VERSION "HNNBNNNYNNNNNNNNNNNNNNNNNNNNNNNNNNNNNNNNNN/4/%%%/4/'%**4NNN///"

NS_ :

BS_:

BU_: BAP_Tester BMS_NV_12V Gateway_Max Klima

BO_ 1640 Klima_12: 8 Klima
 SG_ KL_LRH_Taster : 0|1@1+ (1.0,0.0) [0.0|1] ""  Gateway_Max
 SG_ KL_LRH_Stufe : 1|2@1+ (1.0,0.0) [0.0|3] ""  Gateway_Max
 SG_ HSH_Taster : 3|2@1+ (1.0,0.0) [0.0|3] ""  Gateway_Max
 SG_ FSH_Taster : 5|1@1+ (1.0,0.0) [0.0|1] ""  Gateway_Max
 SG_ KL_Zuheizer_Freigabe : 6|1@1+ (1.0,0.0) [0.0|1] ""  Gateway_Max
 SG_ KL_Beschlagsgefahr : 7|1@1+ (1.0,0.0) [0.0|1] ""  Gateway_Max
 SG_ KL_SIH_Soll_li : 8|3@1+ (1,0) [0|6] ""  Gateway_Max
 SG_ KL_SIH_Soll_re : 11|3@1+ (1,0) [0|6] ""  Gateway_Max
 SG_ KRH_Soll_li : 14|2@1+ (1.0,0.0) [0.0|3] ""  Gateway_Max
 SG_ KL_SIL_Soll_li : 16|3@1+ (1,0) [0|6] ""  Gateway_Max
 SG_ KL_SIL_Soll_re : 19|3@1+ (1,0) [0|6] ""  Gateway_Max
 SG_ KRH_Soll_re : 22|2@1+ (1.0,0.0) [0.0|3] ""  Gateway_Max
 SG_ KL_Geblspng_Soll : 24|8@1+ (0.05,1.45) [1.50|14.00] "Unit_Volt"  Gateway_Max
 SG_ KL_Geblspng_Fond_Soll : 32|8@1+ (0.05,1.45) [1.50|14.00] "Unit_Volt"  Gateway_Max
 SG_ KL_I_Geblaese : 40|8@1+ (0.25,0) [0.00|63.50] "Unit_Amper"  Gateway_Max
 SG_ KL_Kompressorstrom_soll : 48|10@1+ (1,0) [0|1021] ""  Gateway_Max
 SG_ KL_Umluftklappe_Status : 58|4@1+ (1.0,0.0) [0.0|15] ""  Gateway_Max
 SG_ KL_PTC_Verbauinfo : 62|2@1+ (1.0,0.0) [0.0|3] ""  Gateway_Max

BO_ 2527679635 Klima_16: 8 Klima
 SG_ KL_Voko_Status : 0|4@1+ (1.0,0.0) [0.0|15] ""  Gateway_Max
 SG_ KL_LRH_PWM : 4|7@1+ (1,0) [0|100] "Unit_PerCent"  Gateway_Max
 SG_ KL_LRH_Soll : 11|1@1+ (1.0,0.0) [0.0|1] ""  Gateway_Max
 SG_ KL_AL_VR_Anf : 12|2@1+ (1.0,0.0) [0.0|3] ""  Gateway_Max
 SG_ KL_AL_VL_Anf : 14|2@1+ (1.0,0.0) [0.0|3] ""  Gateway_Max
 SG_ KL_AL_HR_Anf : 16|2@1+ (1.0,0.0) [0.0|3] ""  Gateway_Max
 SG_ KL_AL_HL_Anf : 18|2@1+ (1.0,0.0) [0.0|3] ""  Gateway_Max
 SG_ KL_HSH_Soll : 20|1@1+ (1.0,0.0) [0.0|1] ""  Gateway_Max
 SG_ KL_FSH_Soll : 21|1@1+ (1.0,0.0) [0.0|1] ""  Gateway_Max
 SG_ KL_ZR_Anforderung : 22|2@1+ (1.0,0.0) [0.0|3] ""  Gateway_Max
 SG_ KL_VoKo_LED : 24|1@1+ (1.0,0.0) [0.0|1] ""  Gateway_Max
 SG_ KL_Defrost_LED : 25|1@1+ (1.0,0.0) [0.0|1] ""  Gateway_Max
 SG_ KL_HSH_LED : 26|1@1+ (1.0,0.0) [0.0|1] ""  Gateway_Max
 SG_ HSH_Relais_Anf : 27|1@1+ (1.0,0.0) [0.0|1] ""  Gateway_Max
 SG_ FSH_Status : 28|2@1+ (1.0,0.0) [0.0|3] ""  Gateway_Max
 SG_ SIH_Stufe_LED_li : 30|3@1+ (1.0,0.0) [0.0|7] ""  Gateway_Max
 SG_ SIH_Stufe_LED_re : 33|3@1+ (1.0,0.0) [0.0|7] ""  Gateway_Max
 SG_ KL_FSH_LED : 36|1@1+ (1.0,0.0) [0.0|1] ""  Gateway_Max
 SG_ KL_HUP_aktiv : 37|1@1+ (1.0,0.0) [0.0|1] ""  Gateway_Max
 SG_ KL_LSH_DBetr_Ein : 38|1@1+ (1.0,0.0) [0.0|1] ""  Gateway_Max
 SG_ KL_LSH_DBetr_Bestaet : 39|1@1+ (1.0,0.0) [0.0|1] ""  Gateway_Max
 SG_ KL_Klappe_Status : 40|3@1+ (1.0,0.0) [0.0|7] ""  Gateway_Max
 SG_ KL_LSH_Ansteuerung : 43|2@1+ (1.0,0.0) [0.0|3] ""  Gateway_Max
 SG_ KL_Heizstufe_LSH : 45|4@1+ (1.0,0.0) [0.0|15] ""  Gateway_Max
 SG_ KL_LSH_Betriebsdauer : 49|7@1+ (1,0) [0|120] "Unit_Minut"  Gateway_Max
 SG_ KL_Temp_ZH_Soll : 56|8@1+ (0.5,0) [0.5|127.0] "Unit_DegreCelsi"  Gateway_Max

BO_ 2589284015 Klima_21: 8 Klima
 SG_ KL_LRH_FoD_Status : 12|2@1+ (1.0,0.0) [0.0|3] ""  Gateway_Max

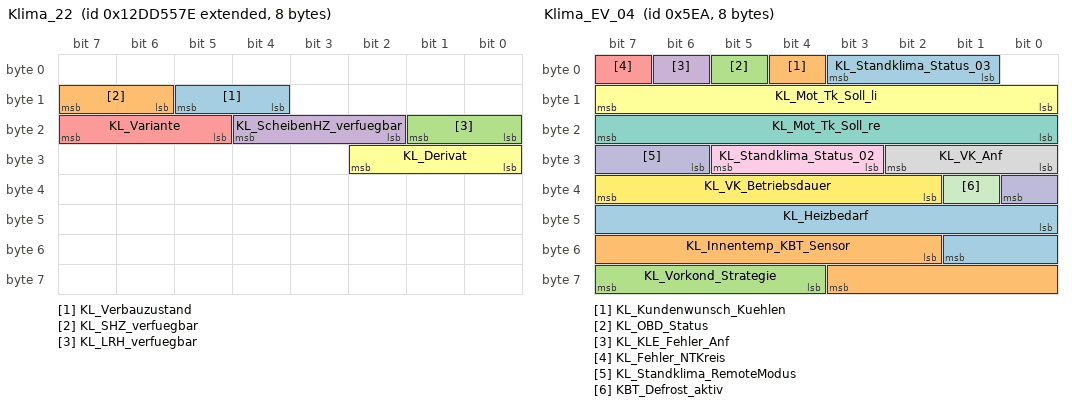
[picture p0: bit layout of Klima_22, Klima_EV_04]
BO_ 2463978878 Klima_22: 8 Klima
 SG_ KL_Verbauzustand : 12|2@1+ (1.0,0.0) [0.0|3] ""  Gateway_Max
 SG_ KL_SHZ_verfuegbar : 14|2@1+ (1.0,0.0) [0.0|3] ""  Gateway_Max
 SG_ KL_LRH_verfuegbar : 16|2@1+ (1.0,0.0) [0.0|3] ""  Gateway_Max
 SG_ KL_ScheibenHZ_verfuegbar : 18|3@1+ (1.0,0.0) [0.0|7] ""  Gateway_Max
 SG_ KL_Variante : 21|3@1+ (1.0,0.0) [0.0|7] ""  Gateway_Max
 SG_ KL_Derivat : 24|3@1+ (1.0,0.0) [0.0|7] ""  Gateway_Max

BO_ 1511 Klima_EV_03: 8 Klima
 SG_ KL_HV_Heizer_Strom : 0|8@1+ (0.25,0) [0.00|63.50] "Unit_Amper"  Gateway_Max
 SG_ KL_EKK_Strom : 8|8@1+ (0.25,0) [0.00|63.50] "Unit_Amper"  Gateway_Max
 SG_ KL_Pumpe_02_Soll : 16|7@1+ (1,0) [0|100] "Unit_PerCent"  Gateway_Max
 SG_ KL_Ventil_03_Soll : 23|1@1+ (1.0,0.0) [0.0|1] ""  Gateway_Max
 SG_ KL_Ventil_10_Status : 24|3@1+ (1.0,0.0) [0.0|7] ""  Gateway_Max
 SG_ KL_Senderkennung : 27|1@1+ (1.0,0.0) [0.0|1] ""  Gateway_Max
 SG_ WP_KJ_Soll : 28|2@1+ (1.0,0.0) [0.0|3] ""  Gateway_Max
 SG_ KL_Fehler_HV_EKK : 30|2@1+ (1.0,0.0) [0.0|3] ""  Gateway_Max
 SG_ KL_Fehler_HV_Heizer : 32|2@1+ (1.0,0.0) [0.0|3] ""  Gateway_Max
 SG_ KL_BattKond_WaPu_DZMax : 34|6@1+ (2,0) [0|100] "Unit_PerCent"  Gateway_Max
 SG_ WP_Kuehlerluefter_Anf : 40|8@1+ (0.4,0) [0.0|101.6] "Unit_PerCent"  Gateway_Max
 SG_ KL_KM_ASV_01_Status : 48|2@1+ (1.0,0.0) [0.0|3] ""  Gateway_Max
 SG_ KL_KM_ASV_02_Status : 50|2@1+ (1.0,0.0) [0.0|3] ""  Gateway_Max
 SG_ KL_Vorwarn_HVHeizer_Leistung : 52|4@1+ (1.0,0.0) [0.0|15] ""  Gateway_Max
 SG_ KL_Status_EoHVL_EKK : 56|2@1+ (1.0,0.0) [0.0|3] ""  Gateway_Max
 SG_ KL_Status_EoHVL_Heizer : 58|2@1+ (1.0,0.0) [0.0|3] ""  Gateway_Max
 SG_ KL_Status_EoHVL_EKK_2 : 60|2@1+ (1.0,0.0) [0.0|3] ""  Gateway_Max
 SG_ KL_Status_EoHVL_Heizer_2 : 62|2@1+ (1.0,0.0) [0.0|3] ""  Gateway_Max

BO_ 1514 Klima_EV_04: 8 Klima
 SG_ KL_Standklima_Status_03 : 1|3@1+ (1.0,0.0) [0.0|7] ""  Gateway_Max
 SG_ KL_Kundenwunsch_Kuehlen : 4|1@1+ (1.0,0.0) [0.0|1] ""  Gateway_Max
 SG_ KL_OBD_Status : 5|1@1+ (1.0,0.0) [0.0|1] ""  Gateway_Max
 SG_ KL_KLE_Fehler_Anf : 6|1@1+ (1.0,0.0) [0.0|1] ""  Gateway_Max
 SG_ KL_Fehler_NTKreis : 7|1@1+ (1.0,0.0) [0.0|1] ""  Gateway_Max
 SG_ KL_Mot_Tk_Soll_li : 8|8@1+ (0.5,0) [0.0|100.0] "Unit_PerCent"  Gateway_Max
 SG_ KL_Mot_Tk_Soll_re : 16|8@1+ (0.5,0) [0.0|100.0] "Unit_PerCent"  Gateway_Max
 SG_ KL_VK_Anf : 24|3@1+ (1.0,0.0) [0.0|7] ""  Gateway_Max
 SG_ KL_Standklima_Status_02 : 27|3@1+ (1.0,0.0) [0.0|7] ""  Gateway_Max
 SG_ KL_Standklima_RemoteModus : 30|3@1+ (1.0,0.0) [0.0|7] ""  Gateway_Max
 SG_ KBT_Defrost_aktiv : 33|1@1+ (1.0,0.0) [0.0|1] ""  Gateway_Max
 SG_ KL_VK_Betriebsdauer : 34|6@1+ (1,0) [0|60] "Unit_Minut"  Gateway_Max
 SG_ KL_Heizbedarf : 40|10@1+ (0.1,0) [0.1|90.0] "Unit_DegreCelsi"  Gateway_Max
 SG_ KL_Innentemp_KBT_Sensor : 50|10@1+ (0.1,-40) [-40.0|62.0] "Unit_DegreCelsi"  Gateway_Max
 SG_ KL_Vorkond_Strategie : 60|4@1+ (1.0,0.0) [0.0|15] ""  Gateway_Max

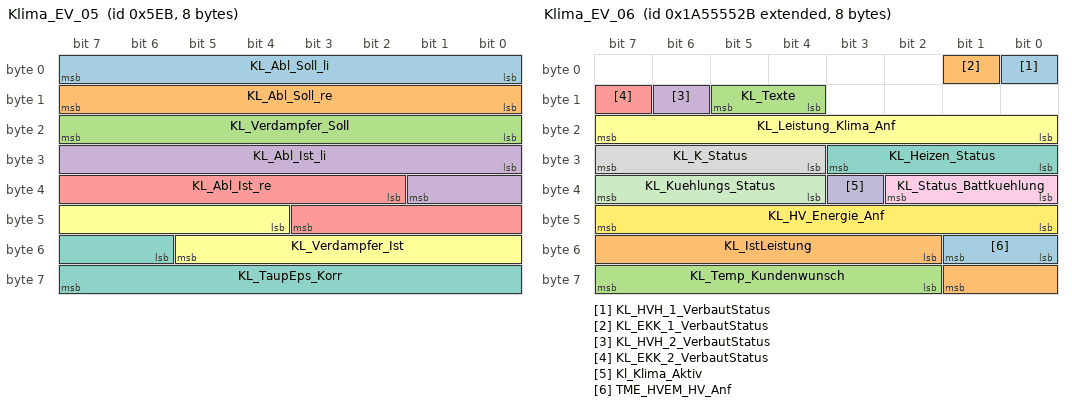
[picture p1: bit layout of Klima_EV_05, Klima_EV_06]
BO_ 1515 Klima_EV_05: 8 Klima
 SG_ KL_Abl_Soll_li : 0|8@1+ (0.5,0) [0.0|86.0] "Unit_DegreCelsi"  Vector__XXX
 SG_ KL_Abl_Soll_re : 8|8@1+ (0.5,0) [0.0|86.0] "Unit_DegreCelsi"  Vector__XXX
 SG_ KL_Verdampfer_Soll : 16|8@1+ (0.5,-40) [-40.0|86.5] "Unit_DegreCelsi"  Vector__XXX
 SG_ KL_Abl_Ist_li : 24|10@1+ (0.1,-20) [-20.0|82.0] "Unit_DegreCelsi"  Vector__XXX
 SG_ KL_Abl_Ist_re : 34|10@1+ (0.1,-20) [-20.0|82.0] "Unit_DegreCelsi"  Vector__XXX
 SG_ KL_Verdampfer_Ist : 44|10@1+ (0.1,-40) [-40.0|62.0] "Unit_DegreCelsi"  Vector__XXX
 SG_ KL_TaupEps_Korr : 54|10@1+ (0.1,-50) [-50.0|52.0] "Unit_DegreCelsi"  Vector__XXX

BO_ 2589283627 Klima_EV_06: 8 Klima
 SG_ KL_HVH_1_VerbautStatus : 0|1@1+ (1.0,0.0) [0.0|1] ""  Gateway_Max
 SG_ KL_EKK_1_VerbautStatus : 1|1@1+ (1.0,0.0) [0.0|1] ""  Gateway_Max
 SG_ KL_Texte : 12|2@1+ (1.0,0.0) [0.0|3] ""  Gateway_Max
 SG_ KL_HVH_2_VerbautStatus : 14|1@1+ (1.0,0.0) [0.0|1] ""  Gateway_Max
 SG_ KL_EKK_2_VerbautStatus : 15|1@1+ (1.0,0.0) [0.0|1] ""  Gateway_Max
 SG_ KL_Leistung_Klima_Anf : 16|8@1+ (50,0) [0|12650] "Unit_Watt"  Gateway_Max
 SG_ KL_Heizen_Status : 24|4@1+ (1.0,0.0) [0.0|15] ""  Gateway_Max
 SG_ KL_K_Status : 28|4@1+ (1.0,0.0) [0.0|15] ""  Gateway_Max
 SG_ KL_Status_Battkuehlung : 32|3@1+ (1.0,0.0) [0.0|7] ""  Gateway_Max
 SG_ Kl_Klima_Aktiv : 35|1@1+ (1.0,0.0) [0.0|1] ""  Gateway_Max
 SG_ KL_Kuehlungs_Status : 36|4@1+ (1.0,0.0) [0.0|15] ""  Gateway_Max
 SG_ KL_HV_Energie_Anf : 40|8@1+ (50,0) [0|12600] "Unit_WattHour"  Gateway_Max
 SG_ TME_HVEM_HV_Anf : 48|2@1+ (1.0,0.0) [0.0|3] ""  Gateway_Max
 SG_ KL_IstLeistung : 50|8@1+ (50,0) [0|12650] "Unit_Watt"  Gateway_Max
 SG_ KL_Temp_Kundenwunsch : 58|6@1+ (0.5,15) [16.0|29.5] "Unit_DegreCelsi"  Gateway_Max

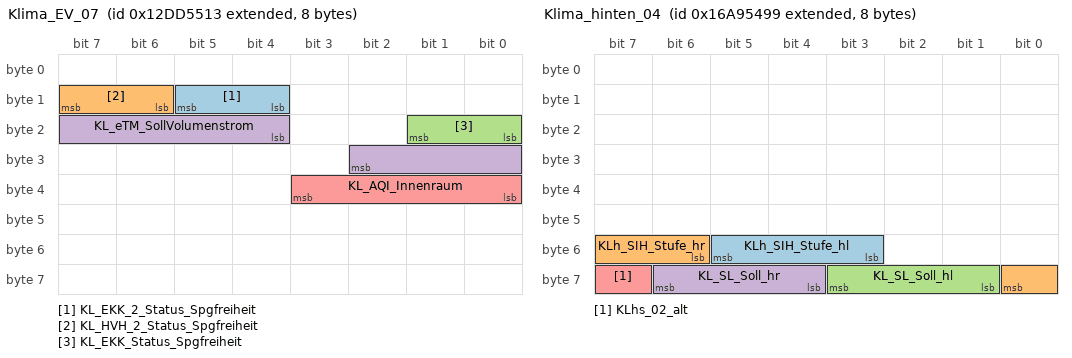
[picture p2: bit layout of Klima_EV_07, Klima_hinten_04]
BO_ 2463978771 Klima_EV_07: 8 Klima
 SG_ KL_EKK_2_Status_Spgfreiheit : 12|2@1+ (1.0,0.0) [0.0|3] ""  Vector__XXX
 SG_ KL_HVH_2_Status_Spgfreiheit : 14|2@1+ (1.0,0.0) [0.0|3] ""  Vector__XXX
 SG_ KL_EKK_Status_Spgfreiheit : 16|2@1+ (1.0,0.0) [0.0|3] ""  Vector__XXX
 SG_ KL_eTM_SollVolumenstrom : 20|7@1+ (0.125,0) [0.000|15.000] "Unit_LiterPerMinut"  Vector__XXX
 SG_ KL_AQI_Innenraum : 32|4@1+ (1.0,0.0) [0.0|15] ""  Gateway_Max

BO_ 2589283574 Klima_EV_10: 16 Klima
 SG_ KL_OBD_Status_Auth : 12|1@1+ (1.0,0.0) [0.0|1] ""  Gateway_Max
 SG_ OBDProtocol_Klima : 16|8@1+ (1.0,0.0) [0.0|255] ""  Gateway_Max
 SG_ SOK_Klima_EV_10_Signatur : 64|64@1+ (1,0) [1|18446744073709551615] "Unit_None"  Gateway_Max

BO_ 2527679641 Klima_hinten_04: 8 Klima
 SG_ KLh_SIH_Stufe_hl : 51|3@1+ (1.0,0.0) [0.0|7] ""  Gateway_Max
 SG_ KLh_SIH_Stufe_hr : 54|3@1+ (1.0,0.0) [0.0|7] ""  Gateway_Max
 SG_ KL_SL_Soll_hl : 57|3@1+ (1.0,0.0) [0.0|7] ""  Gateway_Max
 SG_ KL_SL_Soll_hr : 60|3@1+ (1.0,0.0) [0.0|7] ""  Gateway_Max
 SG_ KLhs_02_alt : 63|1@1+ (1.0,0.0) [0.0|1] ""  Vector__XXX

BO_ 2589283728 Klima_SDA_01: 8 Klima
 SG_ KL_SDA_Sonderfunktionen_Sprache : 0|5@1+ (1.0,0.0) [0.0|31] ""  Gateway_Max
 SG_ KL_SDA_Menutaste : 5|1@1+ (1.0,0.0) [0.0|1] ""  Gateway_Max
 SG_ KL_SDA_Luft_Qualitaet : 6|4@1+ (1.0,0.0) [0.0|15] ""  Gateway_Max
 SG_ KL_SDA_Luft_Feinstaub : 10|8@1+ (5,0) [0|1200] ""  Gateway_Max
 SG_ KL_SDA_AQS_VOZBereich : 18|2@1+ (1.0,0.0) [0.0|3] ""  Gateway_Max
 SG_ KL_SDA_AQS_Traffic : 20|2@1+ (1.0,0.0) [0.0|3] ""  Gateway_Max
 SG_ KL_SDA_AQS_NoxBereich : 22|2@1+ (1.0,0.0) [0.0|3] ""  Gateway_Max
 SG_ KL_SDA_AQS_COBereich : 24|2@1+ (1.0,0.0) [0.0|3] ""  Gateway_Max
 SG_ KL_SDA_AQS_COStatus : 26|4@1+ (1.0,0.0) [0.0|15] ""  Gateway_Max
 SG_ KL_SDA_AQS_NoxStatus : 30|4@1+ (1.0,0.0) [0.0|15] ""  Gateway_Max
 SG_ KL_SDA_AQS_VOZStatus : 34|4@1+ (1.0,0.0) [0.0|15] ""  Gateway_Max
 SG_ KL_SDA_Klima_Automatik : 38|1@1+ (1.0,0.0) [0.0|1] ""  Gateway_Max
 SG_ KL_SDA_Luftverteilung_Person : 39|1@1+ (1.0,0.0) [0.0|1] ""  Gateway_Max
 SG_ KL_SDA_Luftverteilung_Scheibe : 40|1@1+ (1.0,0.0) [0.0|1] ""  Gateway_Max
 SG_ KL_SDA_Luftverteilung_Unten : 41|1@1+ (1.0,0.0) [0.0|1] ""  Gateway_Max
 SG_ KL_SDA_Sitzheizung_VL : 42|2@1+ (1.0,0.0) [0.0|3] ""  Gateway_Max
 SG_ KL_SDA_Sitzheizung_VR : 44|2@1+ (1.0,0.0) [0.0|3] ""  Gateway_Max
 SG_ KL_SDA_Sitzlueftung_VL : 46|2@1+ (1.0,0.0) [0.0|3] ""  Gateway_Max
 SG_ KL_SDA_Sitzlueftung_VR : 48|2@1+ (1.0,0.0) [0.0|3] ""  Gateway_Max
 SG_ KL_SDA_Sonderfkt_AirCare : 50|1@1+ (1.0,0.0) [0.0|1] ""  Gateway_Max
 SG_ KL_SDA_Sonderfkt_HSH : 51|1@1+ (1.0,0.0) [0.0|1] ""  Gateway_Max
 SG_ KL_SDA_Sonderfkt_MaxAC : 52|1@1+ (1.0,0.0) [0.0|1] ""  Gateway_Max
 SG_ KL_SDA_Sonderfkt_MaxDefrost : 53|1@1+ (1.0,0.0) [0.0|1] ""  Gateway_Max
 SG_ KL_SDA_Temp_Kundenwunsch_2 : 54|5@1+ (1.0,0.0) [0.0|31] ""  Gateway_Max
 SG_ KL_SDA_Temp_Kundenwunsch_3 : 59|5@1+ (1.0,0.0) [0.0|31] ""  Gateway_Max

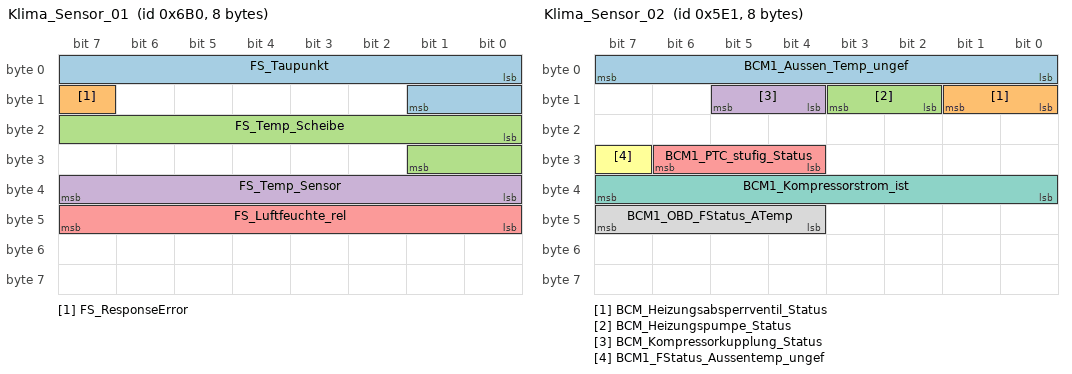
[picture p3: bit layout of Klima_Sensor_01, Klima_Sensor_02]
BO_ 1712 Klima_Sensor_01: 8 Gateway_Max
 SG_ FS_Taupunkt : 0|10@1+ (0.1,-39.6) [-39.5|60.4] "Unit_DegreCelsi"  Klima
 SG_ FS_ResponseError : 15|1@1+ (1.0,0.0) [0.0|1] ""  Klima
 SG_ FS_Temp_Scheibe : 16|10@1+ (0.1,-39.6) [-39.5|60.4] "Unit_DegreCelsi"  Klima
 SG_ FS_Temp_Sensor : 32|8@1+ (0.5,-40) [-39.5|87.0] "Unit_DegreCelsi"  Klima
 SG_ FS_Luftfeuchte_rel : 40|8@1+ (0.5,-0.5) [0.0|100.0] "Unit_PerCent"  Klima

BO_ 1505 Klima_Sensor_02: 8 Gateway_Max
 SG_ BCM1_Aussen_Temp_ungef : 0|8@1+ (0.5,-50) [-50.0|76.0] "Unit_DegreCelsi"  Klima
 SG_ BCM_Heizungsabsperrventil_Status : 8|2@1+ (1.0,0.0) [0.0|3] ""  Vector__XXX
 SG_ BCM_Heizungspumpe_Status : 10|2@1+ (1.0,0.0) [0.0|3] ""  Vector__XXX
 SG_ BCM_Kompressorkupplung_Status : 12|2@1+ (1.0,0.0) [0.0|3] ""  Vector__XXX
 SG_ BCM1_PTC_stufig_Status : 28|3@1+ (1.0,0.0) [0.0|7] ""  Vector__XXX
 SG_ BCM1_FStatus_Aussentemp_ungef : 31|1@1+ (1.0,0.0) [0.0|1] ""  Klima
 SG_ BCM1_Kompressorstrom_ist : 32|8@1+ (4,0) [0|1000] "Unit_MilliAmper"  Vector__XXX
 SG_ BCM1_OBD_FStatus_ATemp : 44|4@1+ (1.0,0.0) [0.0|15] ""  Klima

BO_ 1717 Klima_Sensor_03: 8 Klima
 SG_ FSA_Taupunkt : 0|10@1+ (0.1,-40) [-40.0|60.0] "Unit_DegreCelsi"  Gateway_Max
 SG_ FSA_Err_Defekt_Tsens_TF : 10|1@1+ (1.0,0.0) [0.0|1] ""  Gateway_Max
 SG_ FSA_Luftfeuchte_TNCTOC : 11|1@1+ (1.0,0.0) [0.0|1] ""  Gateway_Max
 SG_ FSA_Luftfeuchte_TF : 12|1@1+ (1.0,0.0) [0.0|1] ""  Gateway_Max
 SG_ FSA_Err_Unterspannung_TF : 13|1@1+ (1.0,0.0) [0.0|1] ""  Gateway_Max
 SG_ FSA_Err_RAMROM_Check_TF : 14|1@1+ (1.0,0.0) [0.0|1] ""  Gateway_Max
 SG_ FSA_ResponseError : 15|1@1+ (1.0,0.0) [0.0|1] ""  Gateway_Max
 SG_ FSA_Temp_Luft : 16|10@1+ (0.1,-40) [-40.0|61.0] "Unit_DegreCelsi"  Gateway_Max
 SG_ FSA_Err_RAMROM_Check_TNCTOC : 26|1@1+ (1.0,0.0) [0.0|1] ""  Gateway_Max
 SG_ FSA_Err_Ueberspannung_TF : 30|1@1+ (1.0,0.0) [0.0|1] ""  Gateway_Max
 SG_ FSA_Luftfeuchte_rel : 32|8@1+ (0.5,0) [0.0|126.0] "Unit_PerCent"  Gateway_Max
 SG_ FSA_HW : 40|4@1+ (1,0) [0|15] ""  Gateway_Max
 SG_ FSA_SW : 44|4@1+ (1,0) [0|15] ""  Gateway_Max
 SG_ FSA_Temp_Sensor : 48|11@1+ (0.1,-40) [-40.0|90.0] "Unit_DegreCelsi"  Gateway_Max
 SG_ FSA_Sensorheizung_Status : 59|1@1+ (1.0,0.0) [0.0|1] ""  Gateway_Max
 SG_ FSA_Err_Defekt_HumSense_TF : 60|1@1+ (1.0,0.0) [0.0|1] ""  Gateway_Max
 SG_ FSA_Err_Defekt_HumSens_TNCTOC : 61|1@1+ (1.0,0.0) [0.0|1] ""  Gateway_Max
 SG_ FSA_ErrMemState : 62|2@1+ (1.0,0.0) [0.0|3] ""  Gateway_Max

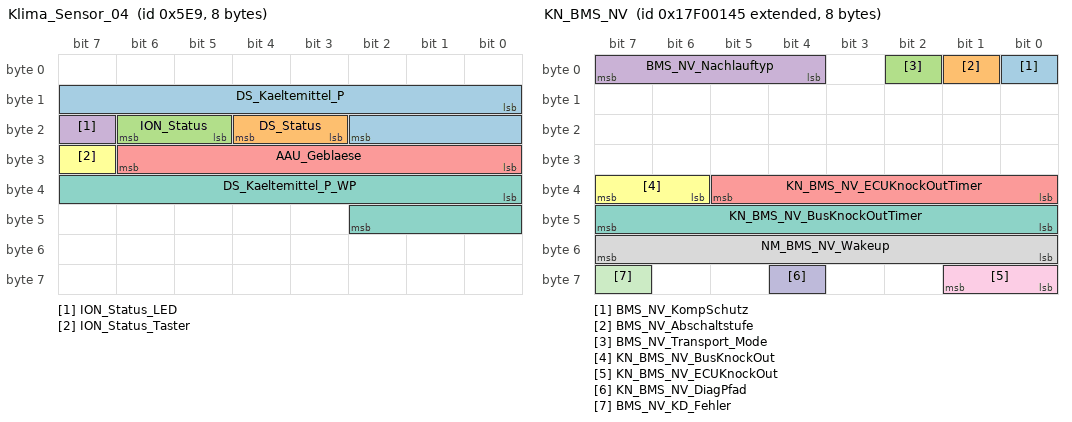
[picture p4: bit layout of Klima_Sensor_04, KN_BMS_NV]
BO_ 1513 Klima_Sensor_04: 8 Klima
 SG_ DS_Kaeltemittel_P : 8|11@1+ (0.0161,0) [0.0000|32.9245] "Unit_Bar"  Gateway_Max
 SG_ DS_Status : 19|2@1+ (1.0,0.0) [0.0|3] ""  Gateway_Max
 SG_ ION_Status : 21|2@1+ (1.0,0.0) [0.0|3] ""  Gateway_Max
 SG_ ION_Status_LED : 23|1@1+ (1.0,0.0) [0.0|1] ""  Gateway_Max
 SG_ AAU_Geblaese : 24|7@1+ (1,0) [0|100] "Unit_PerCent"  Gateway_Max
 SG_ ION_Status_Taster : 31|1@1+ (1.0,0.0) [0.0|1] ""  Gateway_Max
 SG_ DS_Kaeltemittel_P_WP : 32|11@1+ (0.5,0) [0.0|180.0] "Unit_Bar"  Gateway_Max

BO_ 2549088581 KN_BMS_NV: 8 BMS_NV_12V
 SG_ BMS_NV_KompSchutz : 0|1@1+ (1.0,0.0) [0.0|1] ""  Vector__XXX
 SG_ BMS_NV_Abschaltstufe : 1|1@1+ (1.0,0.0) [0.0|1] ""  Vector__XXX
 SG_ BMS_NV_Transport_Mode : 2|1@1+ (1.0,0.0) [0.0|1] ""  Vector__XXX
 SG_ BMS_NV_Nachlauftyp : 4|4@1+ (1.0,0.0) [0.0|15] ""  Gateway_Max
 SG_ KN_BMS_NV_ECUKnockOutTimer : 32|6@1+ (1,0) [0|62] "Unit_Minut"  Vector__XXX
 SG_ KN_BMS_NV_BusKnockOut : 38|2@1+ (1.0,0.0) [0.0|3] ""  Vector__XXX
 SG_ KN_BMS_NV_BusKnockOutTimer : 40|8@1+ (1,0) [0|254] ""  Vector__XXX
 SG_ NM_BMS_NV_Wakeup : 48|8@1+ (1.0,0.0) [0.0|255] ""  Vector__XXX
 SG_ KN_BMS_NV_ECUKnockOut : 56|2@1+ (1.0,0.0) [0.0|3] ""  Vector__XXX
 SG_ KN_BMS_NV_DiagPfad : 60|1@1+ (1.0,0.0) [0.0|1] ""  Gateway_Max
 SG_ BMS_NV_KD_Fehler : 63|1@1+ (1.0,0.0) [0.0|1] ""  Gateway_Max

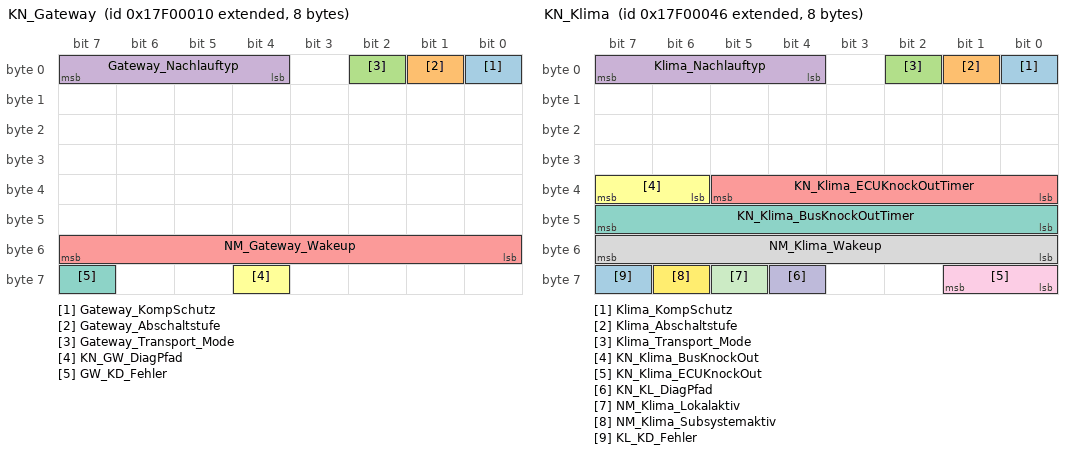
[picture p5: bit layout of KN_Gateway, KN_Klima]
BO_ 2549088272 KN_Gateway: 8 Gateway_Max
 SG_ Gateway_KompSchutz : 0|1@1+ (1.0,0.0) [0.0|1] ""  Vector__XXX
 SG_ Gateway_Abschaltstufe : 1|1@1+ (1.0,0.0) [0.0|1] ""  Vector__XXX
 SG_ Gateway_Transport_Mode : 2|1@1+ (1.0,0.0) [0.0|1] ""  Vector__XXX
 SG_ Gateway_Nachlauftyp : 4|4@1+ (1.0,0.0) [0.0|15] ""  Vector__XXX
 SG_ NM_Gateway_Wakeup : 48|8@1+ (1.0,0.0) [0.0|255] ""  Vector__XXX
 SG_ KN_GW_DiagPfad : 60|1@1+ (1.0,0.0) [0.0|1] ""  Vector__XXX
 SG_ GW_KD_Fehler : 63|1@1+ (1.0,0.0) [0.0|1] ""  Vector__XXX

BO_ 2549088326 KN_Klima: 8 Klima
 SG_ Klima_KompSchutz : 0|1@1+ (1.0,0.0) [0.0|1] ""  Vector__XXX
 SG_ Klima_Abschaltstufe : 1|1@1+ (1.0,0.0) [0.0|1] ""  Vector__XXX
 SG_ Klima_Transport_Mode : 2|1@1+ (1.0,0.0) [0.0|1] ""  Vector__XXX
 SG_ Klima_Nachlauftyp : 4|4@1+ (1.0,0.0) [0.0|15] ""  Gateway_Max
 SG_ KN_Klima_ECUKnockOutTimer : 32|6@1+ (1,0) [0|62] "Unit_Minut"  Vector__XXX
 SG_ KN_Klima_BusKnockOut : 38|2@1+ (1.0,0.0) [0.0|3] ""  Vector__XXX
 SG_ KN_Klima_BusKnockOutTimer : 40|8@1+ (1,0) [0|254] ""  Vector__XXX
 SG_ NM_Klima_Wakeup : 48|8@1+ (1.0,0.0) [0.0|255] ""  Vector__XXX
 SG_ KN_Klima_ECUKnockOut : 56|2@1+ (1.0,0.0) [0.0|3] ""  Vector__XXX
 SG_ KN_KL_DiagPfad : 60|1@1+ (1.0,0.0) [0.0|1] ""  Gateway_Max
 SG_ NM_Klima_Lokalaktiv : 61|1@1+ (1.0,0.0) [0.0|1] ""  Vector__XXX
 SG_ NM_Klima_Subsystemaktiv : 62|1@1+ (1.0,0.0) [0.0|1] ""  Vector__XXX
 SG_ KL_KD_Fehler : 63|1@1+ (1.0,0.0) [0.0|1] ""  Gateway_Max

BO_ 779 Kombi_01: 8 Gateway_Max
 SG_ KBI_ABS_Lampe : 0|1@1+ (1.0,0.0) [0.0|1] ""  Vector__XXX
 SG_ KBI_ESP_Lampe : 1|1@1+ (1.0,0.0) [0.0|1] ""  Vector__XXX
 SG_ KBI_BKL_Lampe : 2|1@1+ (1.0,0.0) [0.0|1] ""  Vector__XXX
 SG_ KBI_Airbag_Lampe : 3|1@1+ (1.0,0.0) [0.0|1] ""  Vector__XXX
 SG_ KBI_SILA_gueltig : 4|1@1+ (1.0,0.0) [0.0|1] ""  Vector__XXX
 SG_ KBI_Lenkung_Lampe : 5|1@1+ (1,0) [0|1] ""  Vector__XXX
 SG_ KBI_Vorglueh_System_Lampe : 6|1@1+ (1.0,0.0) [0.0|1] ""  Vector__XXX
 SG_ KBI_NV_in_Anzeige : 7|1@1+ (1.0,0.0) [0.0|1] ""  Vector__XXX
 SG_ Kombi_01_BZ : 8|4@1+ (1,0) [0|15] ""  Vector__XXX
 SG_ KBI_Anzeigestatus_ACC : 12|1@1+ (1.0,0.0) [0.0|1] ""  Vector__XXX
 SG_ KBI_Anzeigestatus_GRA : 13|2@1+ (1.0,0.0) [0.0|3] ""  Vector__XXX
 SG_ KBI_Oeldruck_Schalter : 15|1@1+ (1.0,0.0) [0.0|1] ""  Vector__XXX
 SG_ KBI_Tankwarnung : 16|1@1+ (1.0,0.0) [0.0|1] ""  Klima
 SG_ KBI_MFA_v_Einheit_01 : 17|1@1+ (1.0,0.0) [0.0|1] ""  Vector__XXX
 SG_ KBI_im_Stellgliedtest : 18|1@1+ (1.0,0.0) [0.0|1] ""  Vector__XXX
 SG_ KBI_Anzeigefehler_LDW : 19|2@1+ (1.0,0.0) [0.0|3] ""  Vector__XXX
 SG_ KBI_Tankwarnung_ungueltig : 21|1@1+ (1.0,0.0) [0.0|1] ""  Vector__XXX
 SG_ KBI_Oeldruckwarnung : 22|1@1+ (1.0,0.0) [0.0|1] ""  Vector__XXX
 SG_ KBI_Handbremse : 23|1@1+ (1.0,0.0) [0.0|1] ""  Vector__XXX
 SG_ KBI_V_Digital : 24|9@1+ (1,0) [0|511] ""  Vector__XXX
 SG_ KBI_PLA_in_Anzeige : 33|1@1+ (1.0,0.0) [0.0|1] ""  Vector__XXX
 SG_ KBI_Anzeigefehler_NV : 34|1@1+ (1.0,0.0) [0.0|1] ""  Vector__XXX
 SG_ KBI_Anzeigestatus_LIM : 35|2@1+ (1.0,0.0) [0.0|3] ""  Vector__XXX
 SG_ KBI_ARA_in_Anzeige : 37|1@1+ (1.0,0.0) [0.0|1] ""  Vector__XXX
 SG_ KBI_Taster_Lift : 38|1@1+ (1.0,0.0) [0.0|1] ""  Vector__XXX
 SG_ KBI_Taster_Fahrwerk : 39|1@1+ (1.0,0.0) [0.0|1] ""  Vector__XXX
 SG_ KBI_Audioabsenkung_MIB : 40|2@1+ (1.0,0.0) [0.0|3] ""  Vector__XXX
 SG_ KBI_Bestaetigung_ESP_Off : 42|2@1+ (1.0,0.0) [0.0|3] ""  Vector__XXX
 SG_ KBI_Anzeigestatus_RHP : 44|2@1+ (1.0,0.0) [0.0|3] ""  Vector__XXX
 SG_ KBI_angez_Geschw : 48|10@1+ (0.32,0) [0.00|325.12] "Unit_KiloMeterPerHour"  Vector__XXX
 SG_ KBI_Konsistenz_ACC : 59|1@1+ (1.0,0.0) [0.0|1] ""  Vector__XXX
 SG_ KBI_Fehler_Anzeige_ACC : 60|1@1+ (1.0,0.0) [0.0|1] ""  Vector__XXX
 SG_ KBI_Anzeigefehler_SWA : 61|2@1+ (1.0,0.0) [0.0|3] ""  Vector__XXX
 SG_ KBI_Systemstatus : 63|1@1+ (1.0,0.0) [0.0|1] ""  Vector__XXX

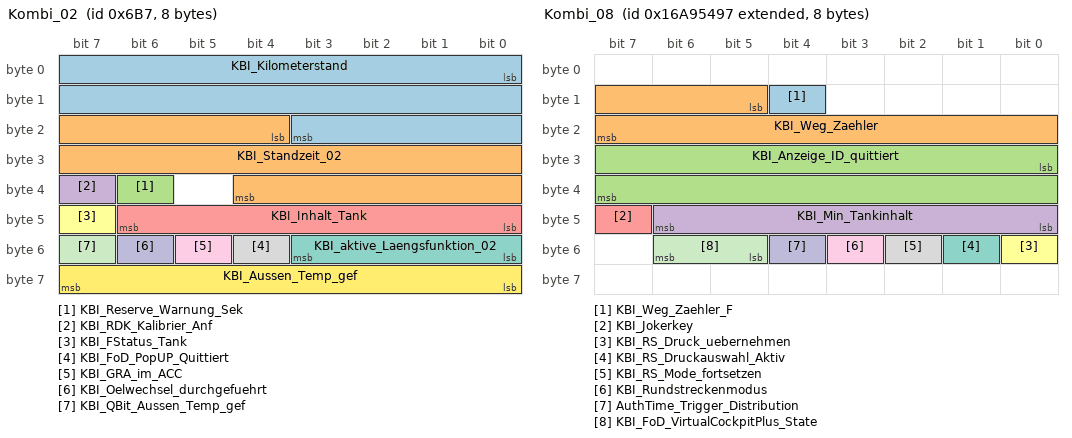
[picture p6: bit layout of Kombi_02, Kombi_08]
BO_ 1719 Kombi_02: 8 Gateway_Max
 SG_ KBI_Kilometerstand : 0|20@1+ (1,0) [0|1048573] "Unit_KiloMeter"  Vector__XXX
 SG_ KBI_Standzeit_02 : 20|17@1+ (1,0) [0|131068] "Unit_Secon"  Klima
 SG_ KBI_Reserve_Warnung_Sek : 38|1@1+ (1.0,0.0) [0.0|1] ""  Vector__XXX
 SG_ KBI_RDK_Kalibrier_Anf : 39|1@1+ (1.0,0.0) [0.0|1] ""  Vector__XXX
 SG_ KBI_Inhalt_Tank : 40|7@1+ (1,0) [0|125] "Unit_Liter"  Vector__XXX
 SG_ KBI_FStatus_Tank : 47|1@1+ (1.0,0.0) [0.0|1] ""  Vector__XXX
 SG_ KBI_aktive_Laengsfunktion_02 : 48|4@1+ (1.0,0.0) [0.0|15] ""  Vector__XXX
 SG_ KBI_FoD_PopUP_Quittiert : 52|1@1+ (1.0,0.0) [0.0|1] ""  Vector__XXX
 SG_ KBI_GRA_im_ACC : 53|1@1+ (1.0,0.0) [0.0|1] ""  Vector__XXX
 SG_ KBI_Oelwechsel_durchgefuehrt : 54|1@1+ (1.0,0.0) [0.0|1] ""  Vector__XXX
 SG_ KBI_QBit_Aussen_Temp_gef : 55|1@1+ (1.0,0.0) [0.0|1] ""  Klima
 SG_ KBI_Aussen_Temp_gef : 56|8@1+ (0.5,-50) [-50.0|75.0] "Unit_DegreCelsi"  Klima

BO_ 2527679639 Kombi_08: 8 Gateway_Max
 SG_ KBI_Weg_Zaehler_F : 12|1@1+ (1.0,0.0) [0.0|1] ""  Vector__XXX
 SG_ KBI_Weg_Zaehler : 13|11@1+ (1,0) [0|2047] "Unit_Meter"  Vector__XXX
 SG_ KBI_Anzeige_ID_quittiert : 24|16@1+ (1,0) [1|65336] "Unit_None"  Vector__XXX
 SG_ KBI_Min_Tankinhalt : 40|7@1+ (0.1,0) [0.0|12.5] "Unit_Liter"  Vector__XXX
 SG_ KBI_Jokerkey : 47|1@1+ (1.0,0.0) [0.0|1] ""  Vector__XXX
 SG_ KBI_RS_Druck_uebernehmen : 48|1@1+ (1.0,0.0) [0.0|1] ""  Vector__XXX
 SG_ KBI_RS_Druckauswahl_Aktiv : 49|1@1+ (1.0,0.0) [0.0|1] ""  Vector__XXX
 SG_ KBI_RS_Mode_fortsetzen : 50|1@1+ (1.0,0.0) [0.0|1] ""  Vector__XXX
 SG_ KBI_Rundstreckenmodus : 51|1@1+ (1.0,0.0) [0.0|1] ""  Vector__XXX
 SG_ AuthTime_Trigger_Distribution : 52|1@1+ (1.0,0.0) [0.0|1] ""  Vector__XXX
 SG_ KBI_FoD_VirtualCockpitPlus_State : 53|2@1+ (1.0,0.0) [0.0|3] ""  Vector__XXX

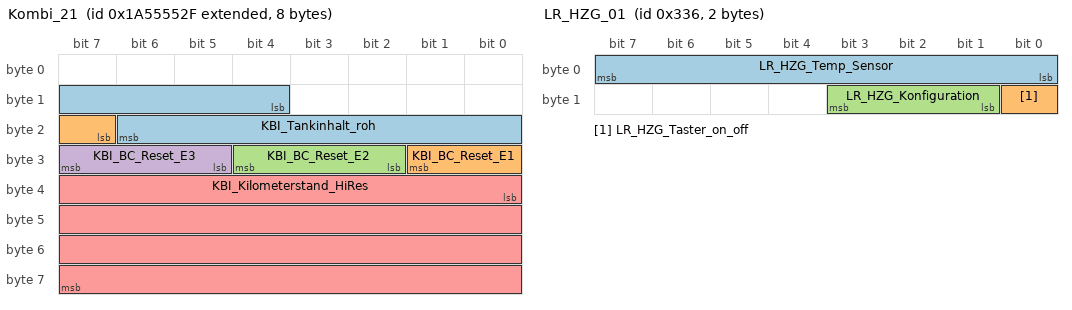
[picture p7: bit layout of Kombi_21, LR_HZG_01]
BO_ 2589283631 Kombi_21: 8 Gateway_Max
 SG_ KBI_Tankinhalt_roh : 12|11@1+ (0.1,0) [0.0|204.5] "Unit_Liter"  Vector__XXX
 SG_ KBI_BC_Reset_E1 : 23|3@1+ (1.0,0.0) [0.0|7] ""  Vector__XXX
 SG_ KBI_BC_Reset_E2 : 26|3@1+ (1.0,0.0) [0.0|7] ""  Vector__XXX
 SG_ KBI_BC_Reset_E3 : 29|3@1+ (1.0,0.0) [0.0|7] ""  Vector__XXX
 SG_ KBI_Kilometerstand_HiRes : 32|32@1+ (0.1,0) [0.0|429496729.5] "Unit_KiloMeter"  Vector__XXX

BO_ 2621440379 KS_Hybrid_01_Req_FD: 16 Gateway_Max
 SG_ KS_Hybrid_01_Req_FD_Data : 0|128@1+ (1.0,0.0) [0.0|340282366920938463463374607431768211455] ""  Vector__XXX

BO_ 2621571451 KS_Hybrid_01_Resp_FD: 16 Vector__XXX
 SG_ KS_Hybrid_01_Resp_FD_Data : 0|128@1+ (1.0,0.0) [0.0|340282366920938463463374607431768211455] ""  Gateway_Max

BO_ 822 LR_HZG_01: 2 Gateway_Max
 SG_ LR_HZG_Temp_Sensor : 0|8@1+ (1,-50) [-50|104] "Unit_DegreCelsi"  Klima
 SG_ LR_HZG_Taster_on_off : 8|1@1+ (1.0,0.0) [0.0|1] ""  Vector__XXX
 SG_ LR_HZG_Konfiguration : 9|3@1+ (1.0,0.0) [0.0|7] ""  Klima

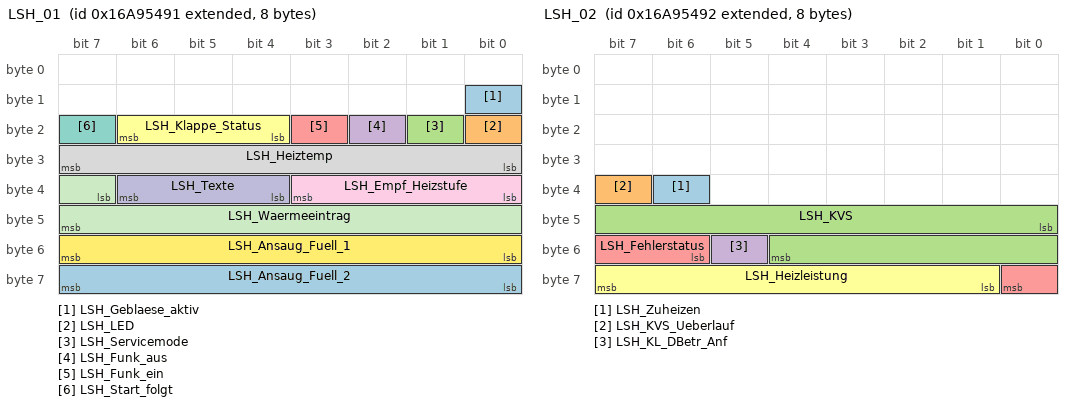
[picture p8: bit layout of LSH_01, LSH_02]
BO_ 2527679633 LSH_01: 8 Gateway_Max
 SG_ LSH_Geblaese_aktiv : 8|1@1+ (1.0,0.0) [0.0|1] ""  Vector__XXX
 SG_ LSH_LED : 16|1@1+ (1.0,0.0) [0.0|1] ""  Klima
 SG_ LSH_Servicemode : 17|1@1+ (1.0,0.0) [0.0|1] ""  Klima
 SG_ LSH_Funk_aus : 18|1@1+ (1.0,0.0) [0.0|1] ""  Klima
 SG_ LSH_Funk_ein : 19|1@1+ (1.0,0.0) [0.0|1] ""  Klima
 SG_ LSH_Klappe_Status : 20|3@1+ (1.0,0.0) [0.0|7] ""  Klima
 SG_ LSH_Start_folgt : 23|1@1+ (1.0,0.0) [0.0|1] ""  Klima
 SG_ LSH_Heiztemp : 24|8@1+ (2,-40) [-40|360] "Unit_DegreCelsi"  Klima
 SG_ LSH_Empf_Heizstufe : 32|4@1+ (1.0,0.0) [0.0|15] ""  Klima
 SG_ LSH_Texte : 36|3@1+ (1.0,0.0) [0.0|7] ""  Klima
 SG_ LSH_Waermeeintrag : 39|9@1+ (5,0) [0|2500] "Unit_Minut"  Klima
 SG_ LSH_Ansaug_Fuell_1 : 48|8@1+ (0.75,-40) [-40.00|142.25] "Unit_DegreCelsi"  Klima
 SG_ LSH_Ansaug_Fuell_2 : 56|8@1+ (0.75,-40) [-40.00|142.25] "Unit_DegreCelsi"  Klima

BO_ 2527679634 LSH_02: 8 Gateway_Max
 SG_ LSH_Zuheizen : 38|1@1+ (1.0,0.0) [0.0|1] ""  Klima
 SG_ LSH_KVS_Ueberlauf : 39|1@1+ (1.0,0.0) [0.0|1] ""  Vector__XXX
 SG_ LSH_KVS : 40|13@1+ (1,0) [0|8191] "Unit_MilliLiter"  Vector__XXX
 SG_ LSH_KL_DBetr_Anf : 53|1@1+ (1.0,0.0) [0.0|1] ""  Klima
 SG_ LSH_Fehlerstatus : 54|3@1+ (1.0,0.0) [0.0|7] ""  Klima
 SG_ LSH_Heizleistung : 57|7@1+ (1,0) [0|100] "Unit_PerCent"  Klima

BO_ 1164 MFG_03: 8 Gateway_Max
 SG_ MFG_Infotainment_Autark : 12|1@1+ (1.0,0.0) [0.0|1] ""  Vector__XXX
 SG_ MFG_Klappe_Status : 13|3@1+ (1.0,0.0) [0.0|7] ""  Vector__XXX
 SG_ MFG_LSH_DBetr_Ein : 16|1@1+ (1.0,0.0) [0.0|1] ""  Vector__XXX
 SG_ MFG_LSH_Betriebsdauer : 17|7@1+ (1,0) [0|120] "Unit_Minut"  Vector__XXX
 SG_ MFG_LSH_DBetr_Bestaet : 24|1@1+ (1.0,0.0) [0.0|1] ""  Vector__XXX
 SG_ MFG_LSH_Ansteuerung : 25|2@1+ (1.0,0.0) [0.0|3] ""  Vector__XXX
 SG_ MF_Radiomute : 27|1@1+ (1.0,0.0) [0.0|1] ""  Vector__XXX
 SG_ MF_Relais_2_Batterie : 28|1@1+ (1.0,0.0) [0.0|1] ""  Vector__XXX
 SG_ MF_Batteriediagnose : 29|3@1+ (1.0,0.0) [0.0|7] ""  Vector__XXX
 SG_ MFG_AppConnect_Anf : 32|2@1+ (1.0,0.0) [0.0|3] ""  Vector__XXX
 SG_ MF_Lampenausfall : 34|1@1+ (1.0,0.0) [0.0|1] ""  Vector__XXX
 SG_ MF_Blinker_L_Sta : 35|1@1+ (1.0,0.0) [0.0|1] ""  Vector__XXX
 SG_ MF_Blinker_R_Sta : 36|1@1+ (1.0,0.0) [0.0|1] ""  Vector__XXX
 SG_ MF_interm_Nebelscheinwerfer : 37|1@1+ (1.0,0.0) [0.0|1] ""  Vector__XXX
 SG_ MF_Generatordiagnose : 38|2@1+ (1.0,0.0) [0.0|3] ""  Vector__XXX
 SG_ MF_Heck_entriegeln : 40|1@1+ (1.0,0.0) [0.0|1] ""  Vector__XXX
 SG_ MF_Heck_verriegeln : 41|1@1+ (1.0,0.0) [0.0|1] ""  Vector__XXX
 SG_ MF_2BatSOCzugering : 42|1@1+ (1.0,0.0) [0.0|1] ""  Vector__XXX
 SG_ MF_Fahrerhinweis : 43|3@1+ (1.0,0.0) [0.0|7] ""  Vector__XXX
 SG_ MF_ZV_Unlock : 46|1@1+ (1.0,0.0) [0.0|1] ""  Vector__XXX
 SG_ MF_Tuerverriegelung_hinten : 47|1@1+ (1.0,0.0) [0.0|1] ""  Vector__XXX
 SG_ MF_2BattAb : 48|1@1+ (1.0,0.0) [0.0|1] ""  Vector__XXX
 SG_ MF_2BattHlkAnf : 49|1@1+ (1.0,0.0) [0.0|1] ""  Vector__XXX
 SG_ MF_2BattLadWarn : 50|1@1+ (1.0,0.0) [0.0|1] ""  Vector__XXX
 SG_ MF_2BattLlaAnf : 51|1@1+ (1.0,0.0) [0.0|1] ""  Vector__XXX
 SG_ MF_2BattSpannungsAnf : 52|2@1+ (1.0,0.0) [0.0|3] ""  Vector__XXX
 SG_ MF_NotStartAktiv : 54|1@1+ (1.0,0.0) [0.0|1] ""  Vector__XXX
 SG_ MF_ExterneLadungWarn : 55|1@1+ (1.0,0.0) [0.0|1] ""  Vector__XXX
 SG_ MF_LSH_Zielzeit : 56|4@1+ (10,0) [0|130] "Unit_Minut"  Klima
 SG_ MF_LSH_Abschaltstufe : 60|3@1+ (1.0,0.0) [0.0|7] ""  Klima
 SG_ MF_LSH_Einschaltverbot : 63|1@1+ (1.0,0.0) [0.0|1] ""  Klima

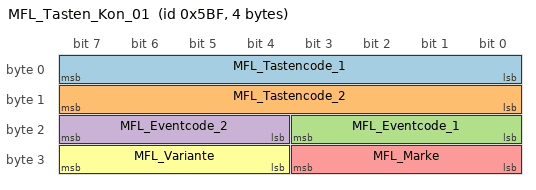
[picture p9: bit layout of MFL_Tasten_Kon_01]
BO_ 1471 MFL_Tasten_Kon_01: 4 Gateway_Max
 SG_ MFL_Tastencode_1 : 0|8@1+ (1.0,0.0) [0.0|255] ""  Klima
 SG_ MFL_Tastencode_2 : 8|8@1+ (1.0,0.0) [0.0|255] ""  Klima
 SG_ MFL_Eventcode_1 : 16|4@1+ (1.0,0.0) [0.0|15] ""  Klima
 SG_ MFL_Eventcode_2 : 20|4@1+ (1.0,0.0) [0.0|15] ""  Klima
 SG_ MFL_Marke : 24|4@1+ (1.0,0.0) [0.0|15] ""  Vector__XXX
 SG_ MFL_Variante : 28|4@1+ (1,0) [0|15] ""  Klima

BO_ 1600 Motor_07: 8 Gateway_Max
 SG_ MO_QBit_Ansaugluft_Temp : 0|1@1+ (1.0,0.0) [0.0|1] ""  Vector__XXX
 SG_ MO_QBit_Oel_Temp : 1|1@1+ (1.0,0.0) [0.0|1] ""  Vector__XXX
 SG_ MO_QBit_Kuehlmittel_Temp : 2|1@1+ (1.0,0.0) [0.0|1] ""  Vector__XXX
 SG_ MO_KL15_Abschaltempfehlung : 3|1@1+ (1.0,0.0) [0.0|1] ""  Vector__XXX
 SG_ MO_HYB_Fehler_HV_Netz : 4|1@1+ (1.0,0.0) [0.0|1] ""  Vector__XXX
 SG_ MO_aktives_Getriebeheizen : 5|1@1+ (1.0,0.0) [0.0|1] ""  Vector__XXX
 SG_ MO_Absperrventil_oeffnen : 6|2@1+ (1.0,0.0) [0.0|3] ""  Klima
 SG_ MO_Ansaugluft_Temp : 8|8@1+ (0.75,-48) [-48.00|141.75] "Unit_DegreCelsi"  Vector__XXX
 SG_ MO_Oel_Temp : 16|8@1+ (1,-60) [-60|192] "Unit_DegreCelsi"  Vector__XXX
 SG_ MO_Kuehlmittel_Temp : 24|8@1+ (0.75,-48) [-48.00|141.75] "Unit_DegreCelsi"  Klima
 SG_ MO_Hoeheninfo : 32|8@1+ (0.00781,0) [0.00000|1.98374] ""  BMS_NV_12V,Klima
 SG_ MO_Kennfeldk : 40|1@1+ (1.0,0.0) [0.0|1] ""  Klima
 SG_ MO_Versionsinfo_02 : 41|5@1+ (1.0,0.0) [0.0|31] ""  Vector__XXX
 SG_ MO_QBit_Hoeheninfo : 46|1@1+ (1.0,0.0) [0.0|1] ""  Vector__XXX
 SG_ MO_Getriebe_kuehlen : 47|1@1+ (1.0,0.0) [0.0|1] ""  Klima
 SG_ MO_Mom_Traegheit_02 : 48|5@1+ (0.01,0) [0.00|0.31] "Unit_KiloGramMeterSquar"  Vector__XXX
 SG_ MO_Heizungspumpenansteuerung : 53|4@1+ (10,0) [0|100] "Unit_PerCent"  Klima
 SG_ MO_SpannungsAnf : 57|1@1+ (1.0,0.0) [0.0|1] ""  Vector__XXX
 SG_ MO_Nachlaufzeit_Heizungspumpe : 58|6@1+ (15,0) [0|945] "Unit_Secon"  Vector__XXX

CM_ BO_ 1640 "ab MQB IS-4";
CM_ BO_ 1712 "1:1 LIN-CAN Botschaft, Originalsender ist Regen-/Licht-/Feuchtesensor auf dem BCM-LIN1";
CM_ BO_ 1505 "ab MQB 7.3";
CM_ BO_ 1717 "ab D4 gültig  --  geänderter Wertebereich und Signalnamen
1:1 LIN-CAN Botschaft vom BCM1, nur bei Kl.15 EIN gesendet";
CM_ BO_ 779 "MQB";
CM_ BO_ 2527679633 "Botschaft mit Signalen der Luftzusatzheizung";
CM_ BO_ 1600 "ab MQB mit QBit Höheneinfo und MO_Versionsinfo_02";

CM_ SG_ 1640 FSH_Taster "Tasterbetätigung Frontscheibenheizung
";
CM_ SG_ 1640 HSH_Taster "An-/Abforderung Heckscheibenheizung über spezielles Tastersignal
";
CM_ SG_ 1640 KL_Beschlagsgefahr "Beschlagsgefahr auf der Frontscheibe im Bereich des Spiegelfusses. Dient zur präventiven Ansteuerung der  Kamera-Scheibenheizung, um Kamera-Blindheit zu vermeiden
PHEV: volle Leistungsfreigabe 
HV Heizer und HV EKK bei Scheibenbeschlag ";
CM_ SG_ 1640 KL_Geblspng_Fond_Soll "Ausgabe des Sollwertes für die Spannung des Klimagebläsemotores hinten.






";
CM_ SG_ 1640 KL_Geblspng_Soll "Ausgabe des Sollwertes für die Spannung des Klimagebläsemotores vorne.







";
CM_ SG_ 1640 KL_I_Geblaese "Stromaufnahme Gebläse";
CM_ SG_ 1640 KL_Kompressorstrom_soll "Sollvorgabe Klima-Kompressorstrom";
CM_ SG_ 1640 KL_LRH_Stufe "Eingestellte Temperaturstufe der Lenkradheizung";
CM_ SG_ 1640 KL_LRH_Taster "Tasterbetätigung Lenkradheizung";
CM_ SG_ 1640 KL_PTC_Verbauinfo "Im Klima- bzw. Heizungsbedienteil wird der Verbau eines PTCs und dessen elektr. Leistungsklasse codiert";
CM_ SG_ 1640 KL_SIH_Soll_li "Einstellung Sitzheizung Fahrer (0...6)";
CM_ SG_ 1640 KL_SIH_Soll_re "Einstellung Sitzheizung Beifahrer (0...6)";
CM_ SG_ 1640 KL_SIL_Soll_li "Einstellung Sitzlüftung Fahrer (0...6)";
CM_ SG_ 1640 KL_SIL_Soll_re "Einstellung Sitzlüftung Beifahrer (0...6)";
CM_ SG_ 1640 KL_Umluftklappe_Status "Status Umluftklappe";
CM_ SG_ 1640 KL_Zuheizer_Freigabe "Freigabe Zuheizer
";
CM_ SG_ 1640 KRH_Soll_li "Ausgabe des Sollwertes für die Kopfraumheizung links.";
CM_ SG_ 1640 KRH_Soll_re "Ausgabe des Sollwertes für die Kopfraumheizung rechts.";

CM_ SG_ 2527679635 FSH_Status "Fehlerstatus der Frontscheibenheizung
";
CM_ SG_ 2527679635 HSH_Relais_Anf "Relaisanforderung Heckscheibenheizung";
CM_ SG_ 2527679635 KL_AL_HL_Anf "Anforderung an das funktionale Ambientelicht eine Solltemperaturveränderung hinten links darzustellen.";
CM_ SG_ 2527679635 KL_AL_HR_Anf "Anforderung an das funktionale Ambientelicht eine Solltemperaturveränderung hinten rechts darzustellen.";
CM_ SG_ 2527679635 KL_AL_VL_Anf "Anforderung an das funktionale Ambientelicht eine Solltemperaturveränderung vorn links darzustellen.";
CM_ SG_ 2527679635 KL_AL_VR_Anf "Anforderung an das funktionale Ambientelicht eine Solltemperaturveränderung vorn rechts darzustellen.";
CM_ SG_ 2527679635 KL_Defrost_LED "Beleuchtung LED Defrost";
CM_ SG_ 2527679635 KL_FSH_LED "Beleuchtung LED Frontscheibenheizung";
CM_ SG_ 2527679635 KL_FSH_Soll "Sollstatus der Frontscheibenheizung";
CM_ SG_ 2527679635 KL_Heizstufe_LSH "Vom Klimabedienteil gesendete Heizstufe der Luftstandheizung";
CM_ SG_ 2527679635 KL_HSH_LED "Beleuchtung LED Heckscheibenheizung";
CM_ SG_ 2527679635 KL_HSH_Soll "Sollstatus Heckscheibenheizung";
CM_ SG_ 2527679635 KL_HUP_aktiv "Signal des Klimabedienteils ob HUP aktiv ist.

0 = HUP aus
1 = HUP ein";
CM_ SG_ 2527679635 KL_Klappe_Status "Status Luftklappe";
CM_ SG_ 2527679635 KL_LRH_PWM "LRH PWM Signal zur Ansteuerung der Treiberstufe im SMLS (0% - 100%)";
CM_ SG_ 2527679635 KL_LRH_Soll "Sollstatus der Lenkradheizung";
CM_ SG_ 2527679635 KL_LSH_Ansteuerung "Ansteuerung LSH";
CM_ SG_ 2527679635 KL_LSH_Betriebsdauer "Betriebsdauer LSH";
CM_ SG_ 2527679635 KL_LSH_DBetr_Bestaet "Bestätigung des Klimabedienteils an die LSH das Dauerbetrieb tatsächlich angefordert ist.";
CM_ SG_ 2527679635 KL_LSH_DBetr_Ein "Dauerbetrieb der Luftstandheizung Ein";
CM_ SG_ 2527679635 KL_Temp_ZH_Soll "Übertragung der Temperaturvorgabe der Klimaanlage an die Wasserzusatzheizung";
CM_ SG_ 2527679635 KL_VoKo_LED "Signalisierung Vorkonditionierung";
CM_ SG_ 2527679635 KL_Voko_Status "Status der Vorkonditionierung.

0 = aus
1 = ein

14 = Init
15 = Fehler";
CM_ SG_ 2527679635 KL_ZR_Anforderung "Anforderung an MIB die Displays zu aktivieren";
CM_ SG_ 2527679635 SIH_Stufe_LED_li "Statusmeldung Sitzheizung links";
CM_ SG_ 2527679635 SIH_Stufe_LED_re "Statusmeldung Sitzheizung rechts";

CM_ SG_ 2589284015 KL_LRH_FoD_Status "LRH-Funktionsspezifisches FoD Statussignal";

CM_ SG_ 2463978878 KL_Derivat "Fahrzeug Derivat";
CM_ SG_ 2463978878 KL_LRH_verfuegbar "Verbauzustand der Lenkradheizung";
CM_ SG_ 2463978878 KL_ScheibenHZ_verfuegbar "Verbauzustand der Scheibenheizung";
CM_ SG_ 2463978878 KL_SHZ_verfuegbar "Verbauinformation der Sitzheizung für die entsprechenden Zone";
CM_ SG_ 2463978878 KL_Variante "Variante Klimabedienung";
CM_ SG_ 2463978878 KL_Verbauzustand "Verbauzustand der Standheizung und weiterer Komponenten";

CM_ SG_ 1511 KL_BattKond_WaPu_DZMax "Maximal-Drehzahl der Wasserpumpe im Batteriekühlkreislauf als Vorgabe für BMS";
CM_ SG_ 1511 KL_EKK_Strom "EKK  Stromaufnahme (Hochvolt)";
CM_ SG_ 1511 KL_Fehler_HV_EKK "Fehlersignal bei Erkennung HV Fehler am elektrischen Klimakompressor EKK
Sender: Klima MQB (evtl. Wärmepumpen SG MQB, OBD SG MQB)";
CM_ SG_ 1511 KL_Fehler_HV_Heizer "Fehlersignal bei Erkennung HV Fehler am HV Heizer
Sender: Klima MQB (evtl. Wärmepumpen SG MQB, OBD SG MQB)";
CM_ SG_ 1511 KL_HV_Heizer_Strom "Strom HV-Heizer für Reichweitenberechnung";
CM_ SG_ 1511 KL_KM_ASV_01_Status "Schaltstatus Kältemittel Absperrventil
VW370/9 PHEV = Ventil vor Verdampfer";
CM_ SG_ 1511 KL_KM_ASV_02_Status "Schaltstatus Kältemittel Absperrventil
VW370/9 PHEV = Ventil vor Chiller";
CM_ SG_ 1511 KL_Pumpe_02_Soll "Anforderung KM-Pumpe Klimakreislauf
Init (126dec)      = 0% Ansteuerung Pumpe
Fehler (127dec) = 100% Ansteuerung Pumpe";
CM_ SG_ 1511 KL_Senderkennung "Gibt an, welches SG (Klima oder WP) die Botschaft sendet";
CM_ SG_ 1511 KL_Status_EoHVL_EKK "Erkennung einer offenen HV-Leitung (EoHVL). Bewertet anhand einer Spannungsgrenze.";
CM_ SG_ 1511 KL_Status_EoHVL_EKK_2 "Erkennung einer offenen HV-Leitung (EoHVL). Bewertet anhand einer Spannungsgrenze.";
CM_ SG_ 1511 KL_Status_EoHVL_Heizer "Erkennung einer offenen HV-Leitung (EoHVL). Bewertet anhand einer Spannungsgrenze.";
CM_ SG_ 1511 KL_Status_EoHVL_Heizer_2 "Erkennung einer offenen HV-Leitung (EoHVL). Bewertet anhand einer Spannungsgrenze.";
CM_ SG_ 1511 KL_Ventil_03_Soll "Anforderung Batteriebypass-Ventil im Klimakreislauf";
CM_ SG_ 1511 KL_Ventil_10_Status "Status Ventil_Wärmepumpe; 
nicht angesteuert: Motor- und Heizkreislauf getrennt; 
angesteuert: Motor- und Heizkreislauf verbunden.";
CM_ SG_ 1511 KL_Vorwarn_HVHeizer_Leistung "Vorwarnung der Heizerleistung für die Stromregelung. Botschaft: Klima_EV_03, da das Signal entweder vom Klimasteuergerät oder dem Wärmepumpensteuergerät gesendet werden soll.";
CM_ SG_ 1511 WP_KJ_Soll "Anforderung der Kuehlerjalousiestellung durch Waermepumpen SG";
CM_ SG_ 1511 WP_Kuehlerluefter_Anf "Anforderung Kühlerlüfter durch Wärmepumpen SG";

CM_ SG_ 1514 KBT_Defrost_aktiv "Defrostmodus im KBT aktiv";
CM_ SG_ 1514 KL_Fehler_NTKreis "Über dieses Fehlersignal werden andere Steuergeräte am NT-Kreis über einen Fehler in der Klimatisierung informiert und können so Folgefehlereinträge vermeiden.";
CM_ SG_ 1514 KL_Heizbedarf "Bedarf an Heizmenge für Innenraumklimatisierung";
CM_ SG_ 1514 KL_Innentemp_KBT_Sensor "Temperatur Innenraum vor Klimabedienteil";
CM_ SG_ 1514 KL_KLE_Fehler_Anf "Anfrage der Klimatisierung an das MSG, ob ein Fehler im Kühlerlüfter vorliegt.";
CM_ SG_ 1514 KL_Kundenwunsch_Kuehlen "KBT meldet aktiven Kühlungswunsch an Waermepumpen SG";
CM_ SG_ 1514 KL_Mot_Tk_Soll_li "Stellung Temperaturklappe Soll links";
CM_ SG_ 1514 KL_Mot_Tk_Soll_re "Stellung Temperaturklappe Soll rechts";
CM_ SG_ 1514 KL_OBD_Status "Dieses Bit steuert die MIL-Lampe an (Motorsteuergerät reicht diese Info an Kombi weiter).";
CM_ SG_ 1514 KL_Standklima_RemoteModus "Modus (Lüften, Kühlen, Heizen) der Standklimatisierung (Innenraum) zur Remote Anzeige";
CM_ SG_ 1514 KL_Standklima_Status_02 "Status der Standklimatisierung (Innenraum)";
CM_ SG_ 1514 KL_Standklima_Status_03 "Standklimatisierung Innenraum";
CM_ SG_ 1514 KL_VK_Anf "Starten einer Standklimatisierung ausgehend von der Climatronic Richtung Lademanagment.";
CM_ SG_ 1514 KL_VK_Betriebsdauer "Berechnete notwendige Betriebsdauer der Vorkonditionierung des Innerraumes (Standklimatisierung). ";
CM_ SG_ 1514 KL_Vorkond_Strategie "Strategie der Vorkonditionierung des Innenraums";

CM_ SG_ 1515 KL_Abl_Ist_li "Ausblastemperatur Ist Links";
CM_ SG_ 1515 KL_Abl_Ist_re "Ausblastemperatur Ist Rechts";
CM_ SG_ 1515 KL_Abl_Soll_li "Ausblastemperatur Soll Links";
CM_ SG_ 1515 KL_Abl_Soll_re "Ausblastemperatur Soll Rechts";
CM_ SG_ 1515 KL_TaupEps_Korr "Korrigierter Taupunktabstannd Windschutzscheibe Innen";
CM_ SG_ 1515 KL_Verdampfer_Ist "Ist Temperatur nach Verdampfer";
CM_ SG_ 1515 KL_Verdampfer_Soll "Soll Temperatur nach Verdampfer";

CM_ SG_ 2589283627 KL_EKK_1_VerbautStatus "Verbaustatus EKK1";
CM_ SG_ 2589283627 KL_EKK_2_VerbautStatus "Verbau Information zweiter EKK";
CM_ SG_ 2589283627 KL_Heizen_Status "Anforderungspriorität Unterkomponente zur Priorisierung und Leistungsverteilung im HV-EM";
CM_ SG_ 2589283627 KL_HV_Energie_Anf "Anforderung HV - Energiebedarf, für VoKo 
";
CM_ SG_ 2589283627 KL_HVH_1_VerbautStatus "Verbau Information HV_Heizer1";
CM_ SG_ 2589283627 KL_HVH_2_VerbautStatus "Verbau Information zusaetzlicher Heizer";
CM_ SG_ 2589283627 KL_IstLeistung "Gesamt-Ist-Leistung für Komfort- und Thermomanagement";
CM_ SG_ 2589283627 KL_K_Status "Satus der Klimatisierung und Wärmepumpe wird ausgegeben.";
CM_ SG_ 2589283627 Kl_Klima_Aktiv "Rückmeldung über HV Klimaaktivität durch Klimasteuergerät für BEV/PHEV";
CM_ SG_ 2589283627 KL_Kuehlungs_Status "Anforderungspriorität Unterkomponente zur Priorisierung und Leistungsverteilung im HV-EM";
CM_ SG_ 2589283627 KL_Leistung_Klima_Anf "Leistungsanforderung ans HVEM von Klima";
CM_ SG_ 2589283627 KL_Status_Battkuehlung "Statusinformation über den akuellen Zustand der aktiven Batteriekühlung durch die Klimaanlage";
CM_ SG_ 2589283627 KL_Temp_Kundenwunsch "Temeratur, die auf der Fahrerseite der Climatronic vom Kunden vorgegeben wird.";
CM_ SG_ 2589283627 KL_Texte "Ein Defizit in Heizleistung bzw. Kühlleistung soll dem Kunden angezeigt werden";
CM_ SG_ 2589283627 TME_HVEM_HV_Anf "Anforderung 'HV-Netz aktivieren' wegen Innenraumkonditionierung mit HV-Komponente";

CM_ SG_ 2463978771 KL_AQI_Innenraum "Weiterleitung der Luftgüte im Innenraum auf den CAN";
CM_ SG_ 2463978771 KL_EKK_2_Status_Spgfreiheit "Status Spannungsfreiheit des EKK";
CM_ SG_ 2463978771 KL_EKK_Status_Spgfreiheit "Status Spannungsfreiheit des EKK1";
CM_ SG_ 2463978771 KL_eTM_SollVolumenstrom "Wasservolumenstrom Anforderung von Klima an das ASG";
CM_ SG_ 2463978771 KL_HVH_2_Status_Spgfreiheit "Status Spannungsfreiheit des zusätzlichen PTC Heizer";

CM_ SG_ 2589283574 KL_OBD_Status_Auth "Ansteuerung der MIL-Lampe über den MIL-Master (Motorsteuergerät)
Redundantes Signal (SOK gesichert) zu KL_OBD_Status";
CM_ SG_ 2589283574 OBDProtocol_Klima "Bestätigung des aktuell umgesetzten Scan Tool Protokolls";
CM_ SG_ 2589283574 SOK_Klima_EV_10_Signatur "Signatur im Rahmen der durch SOK geschützen Broadcast-Kommunikation

Geschützte Funktion: OBD-Malfunction Indicator Light (MIL)
Geschützte PDU: Klima_EV_10";

CM_ SG_ 2527679641 KL_SL_Soll_hl "Einstellung Sitzlüftung hinten links (0...6)";
CM_ SG_ 2527679641 KL_SL_Soll_hr "Einstellung Sitzlüftung hinten rechts (0...6)";
CM_ SG_ 2527679641 KLh_SIH_Stufe_hl "Aktive Stufe Sitzheizung Heck links, auf deren Basis die Sitzheizungsmatten bestromt werden.
Bei dreistufigen Sitzheizungen wird Stufe 0/2/4/6 verwendet.";
CM_ SG_ 2527679641 KLh_SIH_Stufe_hr "Aktive Stufe Sitzheizung Heck rechts, auf deren Basis die Sitzheizungsmatten bestromt werden. 
Bei dreistufigen Sitzheizungen wird Stufe 0/2/4/6 verwendet.";
CM_ SG_ 2527679641 KLhs_02_alt "Veraltet Bit für die LIN-Botschaft KLhs_02";

CM_ SG_ 2589283728 KL_SDA_AQS_COBereich "CO-Bereich (Alle Werte möglich, auch in der INIT-Phase)";
CM_ SG_ 2589283728 KL_SDA_AQS_COStatus "Luftgütestufe";
CM_ SG_ 2589283728 KL_SDA_AQS_NoxBereich "Nox-Bereich (Alle Werte möglich, auch in der INIT-Phase)";
CM_ SG_ 2589283728 KL_SDA_AQS_NoxStatus "Ist die Luftgüte 'Init', ist der AQS-Nox-Status auf 'nicht geschaltet' (Wert 0). Im Anschluß sind die Werte 0 bis 10 für normale Luftgütestufen in Abhänigkeit der Außenluft.  Wert 15 für Nox- Sensor- Fehler ist z. Zt. nicht implementiert.";
CM_ SG_ 2589283728 KL_SDA_AQS_Traffic "Rückgegebener Wert des Signals Navigationsattribute des Frames AQSe";
CM_ SG_ 2589283728 KL_SDA_AQS_VOZBereich "VOZ-Bereich (Alle Werte möglich, auch in der INIT-Phase)";
CM_ SG_ 2589283728 KL_SDA_AQS_VOZStatus "VOZ Status Information";
CM_ SG_ 2589283728 KL_SDA_Klima_Automatik "Status Schalter Klimaautomatik (aus/an)";
CM_ SG_ 2589283728 KL_SDA_Luft_Feinstaub "Feinstaubbelastung der Luft (ug/m3)";
CM_ SG_ 2589283728 KL_SDA_Luft_Qualitaet "Qualität der Luft";
CM_ SG_ 2589283728 KL_SDA_Luftverteilung_Person "Status Luftverteilung Amaturenbrett";
CM_ SG_ 2589283728 KL_SDA_Luftverteilung_Scheibe "Status Luftverteilung auf die Frontscheibe";
CM_ SG_ 2589283728 KL_SDA_Luftverteilung_Unten "Status Luftverteilung Fußraum";
CM_ SG_ 2589283728 KL_SDA_Menutaste "Tasten Status";
CM_ SG_ 2589283728 KL_SDA_Sitzheizung_VL "Intensität der Sitzheizung des Fahrersitzes.";
CM_ SG_ 2589283728 KL_SDA_Sitzheizung_VR "Intensität der Sitzheizung des Beifahrersitzes.";
CM_ SG_ 2589283728 KL_SDA_Sitzlueftung_VL "Intensität der Sitzlüftung des Fahrersitzes.";
CM_ SG_ 2589283728 KL_SDA_Sitzlueftung_VR "Intensität der Sitzlüftung des Beifahrersitzes.";
CM_ SG_ 2589283728 KL_SDA_Sonderfkt_AirCare "Status Schalter Klimaregulierung aktiv/nicht aktiv.";
CM_ SG_ 2589283728 KL_SDA_Sonderfkt_HSH "Status Schalter Scheibenheizung der Heckscheibe aktiv/nicht aktiv.";
CM_ SG_ 2589283728 KL_SDA_Sonderfkt_MaxAC "Status Schalter maximale Klimaregulierung aktiv/nicht aktiv.";
CM_ SG_ 2589283728 KL_SDA_Sonderfkt_MaxDefrost "Status Schalter maximaler Defrost aktiv/nicht aktiv.";
CM_ SG_ 2589283728 KL_SDA_Sonderfunktionen_Sprache "Sprachbefehle und Funktionen für Klimasteuerung";
CM_ SG_ 2589283728 KL_SDA_Temp_Kundenwunsch_2 "Eingestellte Solltemperatur des Beifahrers.";
CM_ SG_ 2589283728 KL_SDA_Temp_Kundenwunsch_3 "Eingestellte Solltemperatur des Rückbank.";

CM_ SG_ 1712 FS_Luftfeuchte_rel "gemessene relative Luftfeuchte";
CM_ SG_ 1712 FS_ResponseError "siehe LIN2.0-Specification
(Darf nicht über ein Fehlergueltigkeitsbit abgesichtert werden!)";
CM_ SG_ 1712 FS_Taupunkt "berechneter Taupunkt";
CM_ SG_ 1712 FS_Temp_Scheibe "gemessene Frontscheibentemperatur";
CM_ SG_ 1712 FS_Temp_Sensor "gemessene Sensortemperatur";

CM_ SG_ 1505 BCM1_Aussen_Temp_ungef "ungefilterter Wert des Aussentemperatursensors
";
CM_ SG_ 1505 BCM1_FStatus_Aussentemp_ungef "Fehlerstatus für Aussentemperatur (Kombianzeige)";
CM_ SG_ 1505 BCM1_Kompressorstrom_ist "IST-Strom vom Klima-Kompressor";
CM_ SG_ 1505 BCM1_OBD_FStatus_ATemp "Fehlerstatus Umgebungstemperatursensor (OBD relevanter Sensor)
";
CM_ SG_ 1505 BCM1_PTC_stufig_Status "Status des BCM1-Heizverbrauchers PTC (stufig)";
CM_ SG_ 1505 BCM_Heizungsabsperrventil_Status "Das Signal beschreibt den Zustand des Heizungsabsperrventils, welches als Portexpander vom BCM1 elektrisch angesteuert wird.";
CM_ SG_ 1505 BCM_Heizungspumpe_Status "Das Signal beschreibt den Zustand der Heizungspumpe, welche als Portexpander vom BCM1 elektrisch angesteuert wird.";
CM_ SG_ 1505 BCM_Kompressorkupplung_Status "Das Signal beschreibt den Zustand der Klimakompressorkupplung, welche als Portexpander vom BCM1 elektrisch angesteuert wird.";

CM_ SG_ 1717 FSA_Err_Defekt_HumSens_TNCTOC "OBD TestNotCompletedThisOperationCycle nach LIN LAH für Feuchteelement, testNotCompletedThisOperationCycle (TNCTOC)";
CM_ SG_ 1717 FSA_Err_Defekt_HumSense_TF "OBD TestFailed Flag, Statusbotschaft für Feuchtesensor außen, testFailed (TF)";
CM_ SG_ 1717 FSA_Err_Defekt_Tsens_TF "OBD TestFailed Flag, Statusbotschaft für diden Feuchtesensor, testFailed (TF)";
CM_ SG_ 1717 FSA_Err_RAMROM_Check_TF "OBD TestFailed Flag, Statusbotschaft für den Feuchtesensor, testFailed (TF)";
CM_ SG_ 1717 FSA_Err_RAMROM_Check_TNCTOC "Signal meldet den Status der Diagnosen nach OBD LIN-LAH, testNotCompletedThisOperationCycle (TNCTOC)";
CM_ SG_ 1717 FSA_Err_Ueberspannung_TF "OBD TestFailed Flag, Statusbotschaft für den Feuchtesensor Außen, testFailed (TF)";
CM_ SG_ 1717 FSA_Err_Unterspannung_TF "OBD TestFailed Flag, Statusbotschaft für den Feuchtesensor, testFailed (TF)";
CM_ SG_ 1717 FSA_ErrMemState "OBD Signal statusbotschaft für den Feuchtesensor außen";
CM_ SG_ 1717 FSA_HW "Hardwarestand";
CM_ SG_ 1717 FSA_Luftfeuchte_rel "Maximaler Feuchtebereich bis 126% für theoretisch errechnete Feuchtewerte des Sensors. Signalwerte >100% bedeuten  rel. Feuchte = 100%";
CM_ SG_ 1717 FSA_Luftfeuchte_TF "OBD TestFailed Flag, Statusbotschaft für den Feuchtesensor, testFailed (TF)";
CM_ SG_ 1717 FSA_Luftfeuchte_TNCTOC "Signal meldet den Status der Diagnosen nach OBD LIN-LAH, testNotCompletedThisOperationCycle (TNCTOC)";
CM_ SG_ 1717 FSA_ResponseError "siehe LIN2.0-Specification
(Darf nicht über ein Fehlergueltigkeitsbit abgesichtert werden!)";
CM_ SG_ 1717 FSA_Sensorheizung_Status "Status der Heizung im Feuchteelement (z.B. SHT10).
0 (=inaktiv) auch bei nicht verbaut";
CM_ SG_ 1717 FSA_SW "Softwarestand";
CM_ SG_ 1717 FSA_Taupunkt "'Init' falls nicht verbaut";
CM_ SG_ 1717 FSA_Temp_Luft "gemessene Temperatur im Luftstrom (z.B. NTC am Sensor)
'Init' falls nicht verbaut
(+61°C bedeutet: Temp_Luft > 60,9°C !)";

CM_ SG_ 1513 AAU_Geblaese "Ansteuergrad des Gebläses";
CM_ SG_ 1513 DS_Kaeltemittel_P "Drucksensor Kältemittel Druck, das Signal wird bei Kl.15 AUS mit dem letzten empfangenen Wert gesendet";
CM_ SG_ 1513 DS_Kaeltemittel_P_WP "Drucksensor Kältemittel Druck, das Signal wird bei Kl.15 AUS mit dem letzten empfangenen Wert gesendet für die Wärmepumpe";
CM_ SG_ 1513 DS_Status "Status des Drucksensors (= LIN-Slave BCM1);
bei Kl.15 AUS wird für 4s noch der letzte Wert gesendet, danach wird das Signal mit dem Wert 3 (= Fehler) gesendet";
CM_ SG_ 1513 ION_Status "Status Hochspannung Ionisator";
CM_ SG_ 1513 ION_Status_LED "Status Funktions LED";
CM_ SG_ 1513 ION_Status_Taster "Status Kundenwunsch (Bedientaster) Ionisator";

CM_ SG_ 2549088581 BMS_NV_Abschaltstufe "Funktionseinschraenkung aufgrund aktiver Abschaltstufe";
CM_ SG_ 2549088581 BMS_NV_KD_Fehler "Bei gesetztem Bit ist mindestens ein Kundendienstfehler eingetragen";
CM_ SG_ 2549088581 BMS_NV_KompSchutz "Signal wird gesetzt wenn Komponentenschutz (KS) im Steuergerät aktiv ist.";
CM_ SG_ 2549088581 BMS_NV_Nachlauftyp "Abgebildet wird die von der Hardware vorgegebene Möglichkeit, die Kommunikation nach Klemme 15 = AUS aufrecht zu erhalten. Es wird ein Init-Wert gesendet.";
CM_ SG_ 2549088581 BMS_NV_Transport_Mode "Funktionseinschraenkung aufgrund aktivem Transport Mode und/oder Transport Schutz";
CM_ SG_ 2549088581 KN_BMS_NV_BusKnockOut "Ausgabe des BusKnockout-Status";
CM_ SG_ 2549088581 KN_BMS_NV_BusKnockOutTimer "Ausgabe des BusKnockOut-Timer";
CM_ SG_ 2549088581 KN_BMS_NV_DiagPfad "Kennzeichnung der Diagnosefähigkeit des BusInterfaces eines Steuergerätes (Knoten)
Umfang LAH 80127

Bei Nutzung des Signal explizit pro angebundenem BusInterface zu setzen:
MQBw_Baseline auf EV-CANFD = 0 (aktiv)";
CM_ SG_ 2549088581 KN_BMS_NV_ECUKnockOut "Ausgabe des ECUKnockout-Status";
CM_ SG_ 2549088581 KN_BMS_NV_ECUKnockOutTimer "Ausgabe des ECUKnockOut-Timer";
CM_ SG_ 2549088581 NM_BMS_NV_Wakeup "enthält die Weckursache; stehen mehrere Weckursachen parallel an, dann muss der kleinste Wert übertragen werden";

CM_ SG_ 2549088272 Gateway_Abschaltstufe "Funktionseinschränkung aufgrund aktiver Abschaltstufe";
CM_ SG_ 2549088272 Gateway_KompSchutz "Funktionseinschränkung aufgrund Komponentenschutz aktiv";
CM_ SG_ 2549088272 Gateway_Nachlauftyp "Abgebildet wird die von der Hardware vorgegebene Möglichkeit, die Kommunikation nach Klemme 15 = AUS aufrecht zu erhalten. Es wird ein Init-Wert gesendet.";
CM_ SG_ 2549088272 Gateway_Transport_Mode "Funktionseinschränkung aufgrund aktivem Transport Mode und/oder Transport Schutz";
CM_ SG_ 2549088272 GW_KD_Fehler "Kundendienstfehlerbit Gateway zur Anzeige eines im Gateway abgelegten Fehlerspeichereintrages.";
CM_ SG_ 2549088272 KN_GW_DiagPfad "Kennzeichnung der Diagnosefähigkeit des BusInterfaces eines Steuergerätes (Knoten)
Umfang LAH 80127

Bei Nutzung des Signal explizit pro angebundenem BusInterface zu setzen:
MQB auf Diag-CAN = 0 (aktiv)
MLBevo auf Diag-CAN = 0 (aktiv)
alle weiteren ";
CM_ SG_ 2549088272 NM_Gateway_Wakeup "enthält die Weckursache; stehen mehrere Weckursachen parallel an, dann muss der kleinste Wert übertragen werden";

CM_ SG_ 2549088326 KL_KD_Fehler "Status Kundendienstfehlerspeichereinträge

";
CM_ SG_ 2549088326 Klima_Abschaltstufe "Funktionseinschränkung aufgrund aktiver Abschaltstufe";
CM_ SG_ 2549088326 Klima_KompSchutz "Funktionseinschränkung aufgrund Komponentenschutz aktiv";
CM_ SG_ 2549088326 Klima_Nachlauftyp "Abgebildet wird die von der Hardware vorgegebene Möglichkeit, die Kommunikation nach Klemme 15 = AUS aufrecht zu erhalten. Es wird ein Init-Wert gesendet.
0 = Kommunikation nur bei KL15=EIN (kein Nachlauf, nicht weckfähig)
1 = Kommunikation nach KL15=AU";
CM_ SG_ 2549088326 Klima_Transport_Mode "Funktionseinschränkung aufgrund aktivem Transport Mode und/oder Transport Schutz";
CM_ SG_ 2549088326 KN_KL_DiagPfad "Kennzeichnung der Diagnosefähigkeit des BusInterfaces eines Steuergerätes (Knoten)
Umfang LAH 80127

Bei Nutzung des Signal explizit pro angebundenem BusInterface zu setzen:

MQB auf K-CAN = 0 (aktiv)
MQB2020 auf K-CAN = 0 (aktiv)
MLBevoGen1 auf H-";
CM_ SG_ 2549088326 KN_Klima_BusKnockOut "Ausgabe des BusKnockout-Status in der Knotenbotschaft";
CM_ SG_ 2549088326 KN_Klima_BusKnockOutTimer "Ausgabe des BusKnockOut-Timer in der Knotenbotschaft";
CM_ SG_ 2549088326 KN_Klima_ECUKnockOut "Ausgabe des ECUKnockout-Status in der Knotenbotschaft";
CM_ SG_ 2549088326 KN_Klima_ECUKnockOutTimer "Ausgabe des ECUKnockOut-Timer in der Knotenbotschaft";
CM_ SG_ 2549088326 NM_Klima_Lokalaktiv "Zeigt an ob das SG nach Klemme15 AUS und nach entsprechender MAX Aktivzeit noch aktiv war";
CM_ SG_ 2549088326 NM_Klima_Subsystemaktiv "Zeigt an ob ein Subsystem des SGs nach Klemme15 AUS und nach entsprechender MAX Aktivzeit noch aktiv war";
CM_ SG_ 2549088326 NM_Klima_Wakeup "enthält die Weckursache; stehen mehrere Weckursachen parallel an, dann muss der kleinste Wert übertragen werden";

CM_ SG_ 779 KBI_ABS_Lampe "ABS-Sicherheits-Lampe wurde eingeschaltet.";
CM_ SG_ 779 KBI_Airbag_Lampe "Airbag Sicherheits-Lampe wurde eingeschaltet ";
CM_ SG_ 779 KBI_angez_Geschw "Im Tacho angezeigte Geschwindigkeit inklusive der Voreilung

";
CM_ SG_ 779 KBI_Anzeigefehler_NV "Über dieses Signal teilt das Kombiinstrument dem Nightvision-Steuergerät mit, dass ein Fehler vom Kombiinstrument diagnostiziert wurde, der zur Abschaltung der Nightvision-Funktion führen muss.";
CM_ SG_ 779 KBI_Anzeigefehler_SWA "Signal bezieht sich nur auf die SWA-Lampe, Vorhalt für Kombis mit SWA-Lampe. ";
CM_ SG_ 779 KBI_Anzeigestatus_ACC "Status der ACC-Anzeige im nicht permanenten Displaybereich";
CM_ SG_ 779 KBI_Anzeigestatus_GRA "Anzeigestatus der GRA High Wunschgeschwindigkeitsanzeige im Kombiinstrument.
Bei VW bedeutet 'nicht vorhanden' GRA-low fähig (LED immer verbaut).
0 = nicht vorhanden
1 = Wunschgeschwindigkeits-Anzeigemöglichkeit vorhanden
2 = reserviert
3 = Fehler (B";
CM_ SG_ 779 KBI_Anzeigestatus_LIM "Anzeigestatus der Speedlimiter Wunschgeschwindigkeitsanzeige im Kombiinstrument (permanenter Anzeigebereich)
0 = nicht vorhanden
1 = Wunschgeschwindigkeits-Anzeigemöglichkeit vorhanden
2 = reserviert
3 = Fehler (Botschaftsüberwachung, Timeout, Akustik";
CM_ SG_ 779 KBI_Anzeigestatus_RHP "Anzeigestatus des roten RHP-Symbols.";
CM_ SG_ 779 KBI_ARA_in_Anzeige "Anzeige von ARA im Kombi aktiv";
CM_ SG_ 779 KBI_Audioabsenkung_MIB "Anforderung der Audioabsenkung im MIB";
CM_ SG_ 779 KBI_Bestaetigung_ESP_Off "ESP Off Bestätigung vom Kombi ans ESC";
CM_ SG_ 779 KBI_BKL_Lampe "Sicherheits-Lampe Bremskontrolle wurde eingeschaltet;
";
CM_ SG_ 779 KBI_ESP_Lampe "ESP-Sicherheits-Lampe wurde eingeschaltet ";
CM_ SG_ 779 KBI_Fehler_Anzeige_ACC "Rückmeldung an ACC, dass mindestens eine der ACC-relevanten Anzeigen -rote Fahrerübernahme, Mitteldisplay, Gong - fehlerhaft sind.";
CM_ SG_ 779 KBI_Handbremse "Handbremsen-Information vom Kombi.
Das Signal bezieht sich ausschließlich auf den Zustand der konventionellen Handbremse.";
CM_ SG_ 779 KBI_im_Stellgliedtest "Kombi im Stellgliedtest, Signal muss eingelesen werden, um Fehlfunktion aufgrund der Bewegung der Stellglieder (Drehzahlmesser, Tacho) des Kombis zu verhindern";
CM_ SG_ 779 KBI_Konsistenz_ACC "Rückmeldung an ACC, dass die Botschaften zur Ansteuerung von Anzeigen nicht bzw. nicht konsistent empfangen wurden (Timeout-, BZ-, CHK- und DLC-Fehler)                                                                                                        ";
CM_ SG_ 779 KBI_Lenkung_Lampe "Sicherheits-Lampe der Lenkung (Lenkhilfe EPS, Audi-Dynamic-Steering ...) wurde eingeschaltet.

0x0 = Lenkungs-Lampe aus
0x1 = Lenkungs-Lampe ein";
CM_ SG_ 779 KBI_MFA_v_Einheit_01 "Einheit der Geschwindigkeit, die vom Fahrer im Car-Menü gewählt wurde. Veränderliche Grösse, im Gegensatz zur Einheit des Tachokranzes.";
CM_ SG_ 779 KBI_NV_in_Anzeige "Das Bit gibt dem NV die Information, ob NV-Bild im Kombi in der Anzeige ist. (Information ist notwendig um Kontrasverstellungen nur dann zuzulassen, wenn der Fahrer das Feedback über das  Kombidisplay bekommt.)";
CM_ SG_ 779 KBI_Oeldruck_Schalter "Das Signal bildet den Status des Öldrucks über den am Kombi angeschlossenen Öldruckschalter ab.";
CM_ SG_ 779 KBI_Oeldruckwarnung "Öldruckwarnung im Kombi aktiv";
CM_ SG_ 779 KBI_PLA_in_Anzeige "Das Signal wird als aktive Rückmeldung genutzt, ob die Info des PLA im Kombi angezeigt wird. Wenn nach Anforderung des Displays das Signal zweimal auf 0 ist, wird der Parkvorgang abgebrochen.
Ein Kombi, dass PLA Anzeige nicht unterstützt, schickt dauerha";
CM_ SG_ 779 KBI_SILA_gueltig "Rückmeldeinformation (Bit 1-6) ist gültig";
CM_ SG_ 779 KBI_Systemstatus "Signalisiert erkannte FuSi-relevante Fehler im Kombi
(keinen Ausfall der Akustik oder des Displays)";
CM_ SG_ 779 KBI_Tankwarnung "Fahrer wird gewarnt, dass er den Reservebereich erreicht hat. Fzg.spezifische Warnschwelle";
CM_ SG_ 779 KBI_Tankwarnung_ungueltig "Validiert den Inhalt des Signales KBI_Tankwarnung";
CM_ SG_ 779 KBI_Taster_Fahrwerk "Betätigung Taster 'Fahrwerk' im Kombi";
CM_ SG_ 779 KBI_Taster_Lift "Betätigung Taster 'Lift' im Kombi J1 zur Verarbeitung im Porsche EFP Steuergerät";
CM_ SG_ 779 KBI_V_Digital "Ausgabe der im Kombi angezeigten digitalen Geschwindigkeit.

Einheit ist im KBI_MFA_v_Einheit_01 definiert";
CM_ SG_ 779 KBI_Vorglueh_System_Lampe "Rückmeldung der Vorglühlampe bzw. Motor Systemlampe (MO_Systemlampe) an den Motor (bei Diesel und Otto!). Hardwaremässig gleiche LED im Kombi (EPC- oder Glühwendel), Unterscheidung nur über Ziffernblatt.";

CM_ SG_ 1719 KBI_aktive_Laengsfunktion_02 "Auswahl, der vom Fahrer gewünschten Laengsregelfunktion";
CM_ SG_ 1719 KBI_FoD_PopUP_Quittiert "Angezeigte FoD-Warnung im Kombi wurde vom Fahrer quittiert; 
Signal wird für die Dauer von 2 Sekunden gesendet";
CM_ SG_ 1719 KBI_FStatus_Tank "Signal wird gesetzt:

a) Während der Fehlerentprellzeit (20 s Entprellung)

b) Bei erkanntem Fehler wird der Tankinhalt während der laufenden KL15-Phase über den 
    Verbrauch zurückgerechnet. In dieser Zeit ist das Bit ebenfalls gesetzt. Nach einem";
CM_ SG_ 1719 KBI_GRA_im_ACC "Gibt den vom Fahrer ausgewählten Modus (ACC oder GRA_im_ACC) an.";
CM_ SG_ 1719 KBI_Inhalt_Tank "Restmenge 2 bzw. 2,5l nicht auflösbar

";
CM_ SG_ 1719 KBI_Kilometerstand "Fehler wird ausgegeben, falls Kilometerstand nicht restaurierbar
";
CM_ SG_ 1719 KBI_Oelwechsel_durchgefuehrt "Nach einen Ölwechsel (Service) ist die Ethanol Warmfahrwarnung zu unterdrücken.";
CM_ SG_ 1719 KBI_QBit_Aussen_Temp_gef "0x0 = gültiger Wert
0x1 = Ersatz-, Init- oder Fehlerwert";
CM_ SG_ 1719 KBI_RDK_Kalibrier_Anf "Bei gesetztem Bit soll die RDK die aktuellen Istdrücke zu Solldrücken übernehmen (nur bei Nichtverbau einer Headunit erforderlich).";
CM_ SG_ 1719 KBI_Reserve_Warnung_Sek "Signalisiert die Reservewarnung für die Energiespeicher CNG, LPG, HV-Batterie.
Fahrer wird gewarnt, dass er den Reservebereich erreicht hat. Fzg.spezifische Warnschwelle.";
CM_ SG_ 1719 KBI_Standzeit_02 "Zähler welcher die Standzeit des Motors wiedergibt.
Das Signal beschreibt den Anteil der Motor-Standzeit zwischen Zündung aus und nächstem Motorstart.";

CM_ SG_ 2527679639 AuthTime_Trigger_Distribution "Funktion Authentische Zeit-Verteilung.Broadcast- Triggersignal für Bekanntgabe an alle Clients, dass ein neuer Zeitstempel im Zeitmaster vorliegt.";
CM_ SG_ 2527679639 KBI_Anzeige_ID_quittiert "Inforrmation über die vom Fahrer quittierte Anzeige";
CM_ SG_ 2527679639 KBI_FoD_VirtualCockpitPlus_State "Informs if the function on demand feature 'Virtual Cockpit Plus' is locked or not.";
CM_ SG_ 2527679639 KBI_Jokerkey "Betaetigung KBI Jokertaste";
CM_ SG_ 2527679639 KBI_Min_Tankinhalt "Tankanzeigeleerwert für Reichweitenberechnung, kein reales Kraftstoffvolumen";
CM_ SG_ 2527679639 KBI_RS_Druck_uebernehmen "Druck für Rundstreckenmodus übernehmen";
CM_ SG_ 2527679639 KBI_RS_Druckauswahl_Aktiv "Menue Druckauswahl aktiv";
CM_ SG_ 2527679639 KBI_RS_Mode_fortsetzen "Kombi fordert Fortsetzung des Rundstreckenmodus";
CM_ SG_ 2527679639 KBI_Rundstreckenmodus "Rundstreckenmodus Anforderung";
CM_ SG_ 2527679639 KBI_Weg_Zaehler "Inkrementaler Zähler des Kombis

PAG-Plattform:
Sendeart: Cyclic
Zykluszeit: 100ms

MLBevo_Konzern:
Sendeart: OnChange
Zykluszeit: 1000ms
Inhibitzeit: 100ms
";
CM_ SG_ 2527679639 KBI_Weg_Zaehler_F "Fehlerbit für den Inkrementalzähler Weg

PAG-Plattform:
Sendeart: Cyclic
Zykluszeit: 100ms

MLBevo_Konzern:
Sendeart: OnChange
Zykluszeit: 1000ms
Inhibitzeit: 100ms";

CM_ SG_ 2589283631 KBI_BC_Reset_E1 "Signalisierung BC Reset. Bei jedem BC Reset wird um 1 hochgezaehlt, bei 0x6 erfolgt Ueberlauf auf 0x1. Bei SG-Reset und Datenverlust vom BC wird der Wert SG_Reset angenommen. Während der Init-Phase wird Init gesendet, nach der Init-Phase der letzte gültig";
CM_ SG_ 2589283631 KBI_BC_Reset_E2 "Signalisierung BC Reset. Bei jedem BC Reset wird um 1 hochgezaehlt, 
bei 0x6 erfolgt Ueberlauf auf 0x1. Bei SG-Reset und Datenverlust vom 
BC wird der Wert SG_Reset angenommen. Während der Init-Phase wird Init gesendet, nach der Init-Phase der letzte gü";
CM_ SG_ 2589283631 KBI_BC_Reset_E3 "Signalisierung BC Reset. Bei jedem BC Reset wird um 1 hochgezaehlt, 
bei 0x6 erfolgt Ueberlauf auf 0x1. Bei SG-Reset und Datenverlust vom 
BC wird der Wert SG_Reset angenommen. Während der Init-Phase wird Init gesendet, nach der Init-Phase der letzte gü";
CM_ SG_ 2589283631 KBI_Kilometerstand_HiRes "Aufgrund gesetzlicher Anforderung muß Motor-SG den Kilometerstand an GST Mode$01 ausgeben.
Vgl. SAEJ1979 Festlegung zum PID$A6: Auflösung 0,1km / Bit
4 Byte länge (Doubleword)";
CM_ SG_ 2589283631 KBI_Tankinhalt_roh "Überträgt den ungefilterten und kalibrierten Tankinhalt (incl. Überhub im Vollbereich). Die Bereitstellung des Signale erfolgt nicht nach OBD Richtlinien. Die OBD konforme Verarbeitung erfolgt im Empfänger";

CM_ SG_ 2621440379 KS_Hybrid_01_Req_FD_Data "ISO-TP FD Datenkanal - FID2NA
Request Funktion 0x01 Komponentenschutz an Knoten 0x7B";

CM_ SG_ 2621571451 KS_Hybrid_01_Resp_FD_Data "ISO-TP FD Datenkanal - FID2NA
Response Knoten 0x7B Funktion 0x01 Komponentenschutz";

CM_ SG_ 822 LR_HZG_Konfiguration "Konfiguration der Heizmatte der Lenkradheizung";
CM_ SG_ 822 LR_HZG_Taster_on_off "Anforderung des Schalters am MFL: Lenkradheizung aus/ein
(Regelung der LR_HZG ist im SMLS)";
CM_ SG_ 822 LR_HZG_Temp_Sensor "Temperaturwert Lenkradheizung";

CM_ SG_ 2527679633 LSH_Ansaug_Fuell_1 "Luftstandheizungsansaugtemperaturfühler 1";
CM_ SG_ 2527679633 LSH_Ansaug_Fuell_2 "Luftstandheizungsansaugtemperaturfühler 2";
CM_ SG_ 2527679633 LSH_Empf_Heizstufe "Heizstufen";
CM_ SG_ 2527679633 LSH_Funk_aus "LSH über Funksignal ausschalten";
CM_ SG_ 2527679633 LSH_Funk_ein "LSH über Funksignal einschalten";
CM_ SG_ 2527679633 LSH_Geblaese_aktiv "Anzeige der Luftstandheizung, dass das interne Gebläse aktiv ist.
0 = Gebläse inaktiv
1 = Gebläse aktiv";
CM_ SG_ 2527679633 LSH_Heiztemp "Luftheizungswärmetauschertemperatur";
CM_ SG_ 2527679633 LSH_Klappe_Status "Status Luftklappe";
CM_ SG_ 2527679633 LSH_LED "Funktionslampe Luftstandheizung";
CM_ SG_ 2527679633 LSH_Servicemode "Luftstandheizung Servicemode";
CM_ SG_ 2527679633 LSH_Start_folgt "Thema Start/Stop: Im Stop-Modus muß das KBT einen Wiederstart anfordern, da ein STH-Start notwendig ist.";
CM_ SG_ 2527679633 LSH_Texte "Anforderung der untersch. Anzeigetexte im Mitteldisplay d. Kombi.

0: Keine Anzeige
1: Kein Standheizungsbetrieb wegen Batteriemanagementeinschränkung
2: Kein Standheizungsbetrieb wegen Kraftstoffmangels
3: Kein Standheizungsbetrieb wegen internem Sy";
CM_ SG_ 2527679633 LSH_Waermeeintrag "Signal enthält die Brenndauer der Luftstandheizung in 5min-Schritten";

CM_ SG_ 2527679634 LSH_Fehlerstatus "Fehlerstatus Luftstandheizung";
CM_ SG_ 2527679634 LSH_Heizleistung "Heizleistung in %";
CM_ SG_ 2527679634 LSH_KL_DBetr_Anf "Sicherheitsabfrage der Luftstandheizung, ob Dauerstandheizbetrieb wirklich gestartet werden soll.
Bestätigungsbit für Anforderung KL_LSH_DBetr_Ein";
CM_ SG_ 2527679634 LSH_KVS "Kraftstoffverbrauch";
CM_ SG_ 2527679634 LSH_KVS_Ueberlauf "Kraftstoffverbrauch Ueberlauf";
CM_ SG_ 2527679634 LSH_Zuheizen "Rückmeldung von der Luftstandheizung, dass das Gerät im Zuheizbetrieb ist.";

CM_ SG_ 1164 MF_2BatSOCzugering "Anzeige bei geringer Ladung der Zweitbatterie";
CM_ SG_ 1164 MF_2BattAb "Batterie Ab Warnung der Zweitbatterie";
CM_ SG_ 1164 MF_2BattHlkAnf "Anforderung einer HLK - Stufe an das BEM";
CM_ SG_ 1164 MF_2BattLadWarn "Anzeige das bei Motorlauf die Zweitbatterie entladen wird im KI";
CM_ SG_ 1164 MF_2BattLlaAnf "Anforderung einer Drehzahlanhebung an das BEM";
CM_ SG_ 1164 MF_2BattSpannungsAnf "Mindestspannugnsanforderung der Zusatbatterie an den BEM";
CM_ SG_ 1164 MF_Batteriediagnose "Erstellt für Zusatzbatterie Crafter";
CM_ SG_ 1164 MF_Blinker_L_Sta "Status Blinker links Sonderaufbauten";
CM_ SG_ 1164 MF_Blinker_R_Sta "Status Blinker rechts Sonderaufbauten";
CM_ SG_ 1164 MF_ExterneLadungWarn "Warnung bei Motorlauf das externer Ladestecker gesteckt ist im KI";
CM_ SG_ 1164 MF_Fahrerhinweis "Fahrerhinweis Kombiinstrument";
CM_ SG_ 1164 MF_Generatordiagnose "Neu erstellt für Crafter";
CM_ SG_ 1164 MF_Heck_entriegeln "Entriegelung Heck über KFG";
CM_ SG_ 1164 MF_Heck_verriegeln "Verriegelung Heck über KFG";
CM_ SG_ 1164 MF_interm_Nebelscheinwerfer "Intermittierender Nebelscheinwerfer bei einer Einsatzfahrt";
CM_ SG_ 1164 MF_Lampenausfall "Meldung Lampenausfall Aufbauhersteller";
CM_ SG_ 1164 MF_LSH_Abschaltstufe "Abschaltstufen der Luftstandheizung an der Zweitbatterie. Das Signal dient der Steuerung des Klima SG an der ersten Batterie und der LSH an der zweiten Batterie durch das Zweitbatterie Em im KFG";
CM_ SG_ 1164 MF_LSH_Einschaltverbot "Statussignal für das Einschaltverbot der Luftstandheizung an der Zweitbatterie, Steuerung durch das Zweitbatterie EM im KFG.
0 volle Verfuegbarkeit Standheizung/-lueftung
1 Standheizung/-lueftung nicht aktivierbar";
CM_ SG_ 1164 MF_LSH_Zielzeit "Definition der Zielzeit für die Luftstandheizung an der zweiten Batterie, Steuerung durch das Zweitbatterie EM im KFG.";
CM_ SG_ 1164 MF_NotStartAktiv "Anzeige Notstart Aktiv für den Zeitraum der Schließung des Notstartrelais";
CM_ SG_ 1164 MF_Radiomute "Wird bei Sonderfahrzeugen wie Polizei dafür verwendet, um das Radio bei einem eingehenden Funkspruch zu muten.";
CM_ SG_ 1164 MF_Relais_2_Batterie "Zeigt den Zustand des vom KFG angesteuerten Laderelais einer verbauten 2. Batterie an";
CM_ SG_ 1164 MF_Tuerverriegelung_hinten "Internes Verriegeln der hinteren Türen";
CM_ SG_ 1164 MF_ZV_Unlock "Globales entriegeln über KFG";
CM_ SG_ 1164 MFG_AppConnect_Anf "AppConnect Anforderung durch das KFG";
CM_ SG_ 1164 MFG_Infotainment_Autark "Das Signal gibt an ob die Energieversorgung für ein Infotainment im Fahrzeug Autarkbetrieb sichergestellt ist";
CM_ SG_ 1164 MFG_Klappe_Status "Einstellung der Luftklappenposition an der Luftstandheizung";
CM_ SG_ 1164 MFG_LSH_Ansteuerung "Ansteuerung LSH";
CM_ SG_ 1164 MFG_LSH_Betriebsdauer "Betriebsdauer LSH";
CM_ SG_ 1164 MFG_LSH_DBetr_Bestaet "Bestätigung des KFGs an die LSH, dass Dauerbetrieb tatsächlich angefordert ist.";
CM_ SG_ 1164 MFG_LSH_DBetr_Ein "Dauerbetrieb der Luftstandheizung Ein";

CM_ SG_ 1471 MFL_Eventcode_1 "Siehe Q-LAH MFL-Protokoll";
CM_ SG_ 1471 MFL_Eventcode_2 "Siehe Q-LAH MFL-Protokoll";
CM_ SG_ 1471 MFL_Marke "Marke für markenspezifische Variantennummer des MFL";
CM_ SG_ 1471 MFL_Tastencode_1 "Beschreibt die Funktion einer fest zugeordneten Taste/Walze auf dem MFL. Bei Betätigung ändert sich der Wert von 0x0 auf den jeweiligen Tastencode.";
CM_ SG_ 1471 MFL_Tastencode_2 "Beschreibt die Funktion einer fest zugeordneten Taste/Walze auf dem MFL. Ist MFL_Tastencode_1 wegen Betätigung einer Taste/Walze bereits mit einem Wert ungleich 0x0 belegt, so ändert sich bei Betätigung einer weiteren Taste/Walze der Wert dieses Signals v";
CM_ SG_ 1471 MFL_Variante "Markenspezifische Variantennummer des MFL";

CM_ SG_ 1600 MO_Absperrventil_oeffnen "Signal an Klima-SG das Absperrrventil anzusteuern. Ab D4 auch 0x3 Ventil_schließen.

Im MQB wird hier der Soll-Status des Absperrventils ausgegeben.
Achtung: bei z. B. klemmendem Ventil entspricht das Signal nicht dem tatsächlichen Status!";
CM_ SG_ 1600 MO_aktives_Getriebeheizen "Information für Getriebe, ob ein Ventil für Getriebheizen angesteuert werden muss";
CM_ SG_ 1600 MO_Ansaugluft_Temp "In Fahrzeugen ohne Außentemperatur vom Kombi kann aus der Ansauglufttemperatur auf die Außentemperatur geschlossen werden. Beim SDI ist das mit einer gewissen Genauigkeit gegeben. Genutzt wird es vom ASG.";
CM_ SG_ 1600 MO_Getriebe_kuehlen "Anforderung Getriebekühlventilansteuerung";
CM_ SG_ 1600 MO_Heizungspumpenansteuerung "Anforderung Heizungspumpenansteuerung
MQB und Hybrid: Status der Heizungsunterstützungspumpe am MSG
";
CM_ SG_ 1600 MO_Hoeheninfo "Korrekturfaktor Höhe (1 entspricht 1013 mbar)";
CM_ SG_ 1600 MO_HYB_Fehler_HV_Netz "Im HV-Bordnetz ist fehlerbedingt kein generatorischer Betrieb möglich. Das 12V-Bordnetz wird über den DC/DC-Wandler allein aus der Traktionsbatterie gespeist. Um diesen Zustand möglichst lange aufrechterhalten zu können, sollten Komfort-Verbraucher abgesc";
CM_ SG_ 1600 MO_Kennfeldk "Die Kennfeldkühlung ist in diesem Fahrzeug verbaut und hat keinen Systemfehler";
CM_ SG_ 1600 MO_KL15_Abschaltempfehlung "Kessy Abschaltempfehlung nach Verlassen des Fahrzeugs";
CM_ SG_ 1600 MO_Kuehlmittel_Temp "Kuehlmitteltemperatur";
CM_ SG_ 1600 MO_Mom_Traegheit_02 "Massenträgheit (J) der Motors bzw. der Antriebsmaschinen in kgm².

Zur Berücksichtigung des E-Motor in Hybrid-Projekten:
in MLB-Projekten wird nur der J-Wert des Verbrennungsmotors und nicht der J-Wert des E-Motors berücksichtigt.
In MQB/MLBevo-Projek";
CM_ SG_ 1600 MO_Nachlaufzeit_Heizungspumpe "Nachlaufzeit für Heizungspumpe für Turboladerschutz";
CM_ SG_ 1600 MO_Oel_Temp "Realer Meßbereich ca. -40..150 Grad";
CM_ SG_ 1600 MO_QBit_Ansaugluft_Temp "
";
CM_ SG_ 1600 MO_QBit_Hoeheninfo "Qualifizierungsbit der Höheninfo. Gesetzt bei Ersatzwert, Init oder Fehler.";
CM_ SG_ 1600 MO_QBit_Kuehlmittel_Temp "
";
CM_ SG_ 1600 MO_SpannungsAnf "Forderung des Motor-SGs zur Spannungsanhebung";
CM_ SG_ 1600 MO_Versionsinfo_02 "Versioninformation vom Motor zur Steuerung bei inkompatiblen KMatrix-Änderung bzw. Einführung von neuen Funktionen, die in den Empfängern verriegelt werden müssen. Zu jedem Ereignis wird ein fixer Zählerstand zugeordnet, um dem Empfänger die funktionale Ä";
BA_DEF_REL_ BU_SG_REL_  "GenSigTimeoutTime" INT 0 65535;
BA_DEF_ BO_  "DiagRequest" ENUM "No", "Yes";
BA_DEF_ BO_  "DiagResponse" ENUM "No", "Yes";
BA_DEF_ BO_  "DiagState" ENUM "No", "Yes";
BA_DEF_ BO_  "GenMsgChkConstant" HEX 0 4095;
BA_DEF_ BO_  "GenMsgCycleTime" INT 0 65535;
BA_DEF_ BO_  "GenMsgCycleTimeFast" INT 0 65535;
BA_DEF_ BO_  "GenMsgDelayTime" INT 0 100000;
BA_DEF_ BO_  "GenMsgILSupport" ENUM "No", "Yes";
BA_DEF_ BO_  "GenMsgNrOfRepetition" INT 0 100;
BA_DEF_ BO_  "GenMsgPDUConstants" STRING;
BA_DEF_ BO_  "GenMsgSendType" ENUM "Cyclic", "not_used", "not_used", "not_used", "not_used", "not_used", "not_used", "IfActive", "NoMsgSendType";
BA_DEF_ BO_  "GenMsgStartDelayTime" INT 0 100000;
BA_DEF_ BO_  "NmMessage" ENUM "No", "Yes";
BA_DEF_ BO_  "NmhMessage" ENUM "No", "Yes";
BA_DEF_ BO_  "MsgType" ENUM "Application", "NM ", "NMH", "TP2.0", "ISO-TP ", "BAP", "EID", "KS", "XCP_PRE_CONFIGURED", "XCP_RUNTIME_CONFIGURED";
BA_DEF_ BO_  "VAGTP20_API" HEX 0 255;
BA_DEF_ BO_  "VAGTP20_DynConnection" ENUM "No", "Yes";
BA_DEF_ BO_  "VAGTP20_DynSetup" ENUM "No", "Yes";
BA_DEF_ BO_  "VAGTP20_StatConnection" ENUM "No", "Yes";
BA_DEF_ BO_  "CANFD_BRS" ENUM "0", "1";
BA_DEF_ BO_  "VFrameFormat" ENUM "StandardCAN", "ExtendedCAN", "reserved", "reserved", "reserved", "reserved", "reserved", "reserved", "reserved", "reserved", "reserved", "reserved", "reserved", "reserved", "StandardCAN_FD", "ExtendedCAN_FD";
BA_DEF_ SG_  "GenSigActiveRepetitions" INT -2147483648 2147483647;
BA_DEF_ SG_  "GenSigInactiveValue" INT -2147483648 2147483647;
BA_DEF_ SG_  "GenSigSendType" ENUM "Cyclic", "OnWrite", "OnWriteWithRepetition", "OnChange", "OnChangeWithRepetition", "IfActive", "IfActiveWithRepetition", "NoSigSendType", "OnChangeAndIfActive", "OnChangeAndIfActiveWithRepetition";
BA_DEF_ SG_  "GenSigStartValue" INT -2147483648 2147483647;
BA_DEF_ SG_  "NWM-WakeupAllowed" ENUM "No", "Yes";
BA_DEF_ SG_  "GenSigFuncType" ENUM "NoFunction", "MsgCounter", "CRC-8", "XOR", "XOR-2", "DatedBit", "SW-Kl15", "CHK", "Constant", "Protocol", "CRC-8-SAE_J1850", "CRC-32", "DataLength", "DataID", "MsgCounter16", "SOK-Signatur", "Cluster";
BA_DEF_ SG_  "GenSigSwitchedByIgnition" ENUM "No", "Yes";
BA_DEF_ SG_  "Fehlerwert" HEX 0 2147483647;
BA_DEF_ SG_  "GenSigMissingSourceValue" HEX 0 2147483647;
BA_DEF_DEF_REL_  "GenSigTimeoutTime" 0;
BA_DEF_DEF_  "DiagRequest" "No";
BA_DEF_DEF_  "DiagResponse" "No";
BA_DEF_DEF_  "DiagState" "No";
BA_DEF_DEF_  "GenMsgChkConstant" 0;
BA_DEF_DEF_  "GenMsgCycleTime" 0;
BA_DEF_DEF_  "GenMsgCycleTimeFast" 0;
BA_DEF_DEF_  "GenMsgDelayTime" 0;
BA_DEF_DEF_  "GenMsgILSupport" "No";
BA_DEF_DEF_  "GenMsgNrOfRepetition" 0;
BA_DEF_DEF_  "GenMsgPDUConstants" "";
BA_DEF_DEF_  "GenMsgSendType" "NoMsgSendType";
BA_DEF_DEF_  "GenMsgStartDelayTime" 0;
BA_DEF_DEF_  "NmMessage" "No";
BA_DEF_DEF_  "NmhMessage" "No";
BA_DEF_DEF_  "MsgType" "Application";
BA_DEF_DEF_  "VAGTP20_API" 0;
BA_DEF_DEF_  "VAGTP20_DynConnection" "No";
BA_DEF_DEF_  "VAGTP20_DynSetup" "No";
BA_DEF_DEF_  "VAGTP20_StatConnection" "No";
BA_DEF_DEF_  "CANFD_BRS" "1";
BA_DEF_DEF_  "VFrameFormat" "StandardCAN";
BA_DEF_DEF_  "GenSigActiveRepetitions" 0;
BA_DEF_DEF_  "GenSigInactiveValue" 0;
BA_DEF_DEF_  "GenSigSendType" "NoSigSendType";
BA_DEF_DEF_  "GenSigStartValue" 0;
BA_DEF_DEF_  "NWM-WakeupAllowed" "No";
BA_DEF_DEF_  "GenSigFuncType" "NoFunction";
BA_DEF_DEF_  "GenSigSwitchedByIgnition" "Yes";
BA_DEF_DEF_  "Fehlerwert" 0;
BA_DEF_DEF_  "GenSigMissingSourceValue" 0;
BA_ "GenMsgCycleTime" BO_ 1640 200;
BA_ "GenMsgCycleTimeFast" BO_ 1640 100;
BA_ "GenMsgDelayTime" BO_ 1640 50;
BA_ "GenMsgILSupport" BO_ 1640 1;
BA_ "GenMsgNrOfRepetition" BO_ 1640 5;
BA_ "GenMsgSendType" BO_ 1640 0;
BA_ "VFrameFormat" BO_ 1640 14;
BA_ "GenMsgCycleTime" BO_ 2527679635 2000;
BA_ "GenMsgDelayTime" BO_ 2527679635 200;
BA_ "GenMsgILSupport" BO_ 2527679635 1;
BA_ "GenMsgSendType" BO_ 2527679635 0;
BA_ "VFrameFormat" BO_ 2527679635 15;
BA_ "GenMsgCycleTime" BO_ 2589284015 1000;
BA_ "GenMsgILSupport" BO_ 2589284015 1;
BA_ "GenMsgSendType" BO_ 2589284015 0;
BA_ "VFrameFormat" BO_ 2589284015 15;
BA_ "GenMsgCycleTime" BO_ 2463978878 100;
BA_ "GenMsgILSupport" BO_ 2463978878 1;
BA_ "GenMsgSendType" BO_ 2463978878 0;
BA_ "VFrameFormat" BO_ 2463978878 15;
BA_ "GenMsgCycleTime" BO_ 1511 200;
BA_ "GenMsgILSupport" BO_ 1511 1;
BA_ "GenMsgSendType" BO_ 1511 0;
BA_ "VFrameFormat" BO_ 1511 14;
BA_ "GenMsgCycleTime" BO_ 1514 500;
BA_ "GenMsgILSupport" BO_ 1514 1;
BA_ "GenMsgSendType" BO_ 1514 0;
BA_ "VFrameFormat" BO_ 1514 14;
BA_ "GenMsgCycleTime" BO_ 1515 500;
BA_ "GenMsgILSupport" BO_ 1515 1;
BA_ "GenMsgSendType" BO_ 1515 0;
BA_ "VFrameFormat" BO_ 1515 14;
BA_ "GenMsgCycleTime" BO_ 2589283627 500;
BA_ "GenMsgILSupport" BO_ 2589283627 1;
BA_ "GenMsgSendType" BO_ 2589283627 0;
BA_ "VFrameFormat" BO_ 2589283627 15;
BA_ "GenMsgCycleTime" BO_ 2463978771 100;
BA_ "GenMsgILSupport" BO_ 2463978771 1;
BA_ "GenMsgSendType" BO_ 2463978771 0;
BA_ "VFrameFormat" BO_ 2463978771 15;
BA_ "GenMsgCycleTime" BO_ 2589283574 500;
BA_ "GenMsgILSupport" BO_ 2589283574 1;
BA_ "GenMsgSendType" BO_ 2589283574 0;
BA_ "VFrameFormat" BO_ 2589283574 15;
BA_ "GenMsgCycleTime" BO_ 2527679641 1000;
BA_ "GenMsgDelayTime" BO_ 2527679641 100;
BA_ "GenMsgILSupport" BO_ 2527679641 1;
BA_ "GenMsgSendType" BO_ 2527679641 0;
BA_ "VFrameFormat" BO_ 2527679641 15;
BA_ "GenMsgCycleTime" BO_ 2589283728 1000;
BA_ "GenMsgILSupport" BO_ 2589283728 1;
BA_ "GenMsgSendType" BO_ 2589283728 0;
BA_ "VFrameFormat" BO_ 2589283728 15;
BA_ "GenMsgCycleTime" BO_ 1712 500;
BA_ "GenMsgILSupport" BO_ 1712 1;
BA_ "GenMsgSendType" BO_ 1712 0;
BA_ "VFrameFormat" BO_ 1712 14;
BA_ "GenMsgCycleTime" BO_ 1505 200;
BA_ "GenMsgILSupport" BO_ 1505 1;
BA_ "GenMsgSendType" BO_ 1505 0;
BA_ "VFrameFormat" BO_ 1505 14;
BA_ "GenMsgCycleTime" BO_ 1717 500;
BA_ "GenMsgILSupport" BO_ 1717 1;
BA_ "GenMsgSendType" BO_ 1717 0;
BA_ "VFrameFormat" BO_ 1717 14;
BA_ "GenMsgCycleTime" BO_ 1513 200;
BA_ "GenMsgILSupport" BO_ 1513 1;
BA_ "GenMsgSendType" BO_ 1513 0;
BA_ "VFrameFormat" BO_ 1513 14;
BA_ "GenMsgCycleTime" BO_ 2549088581 500;
BA_ "GenMsgILSupport" BO_ 2549088581 1;
BA_ "GenMsgSendType" BO_ 2549088581 0;
BA_ "VFrameFormat" BO_ 2549088581 15;
BA_ "GenMsgCycleTime" BO_ 2549088272 500;
BA_ "GenMsgILSupport" BO_ 2549088272 1;
BA_ "GenMsgSendType" BO_ 2549088272 0;
BA_ "VFrameFormat" BO_ 2549088272 15;
BA_ "GenMsgCycleTime" BO_ 2549088326 500;
BA_ "GenMsgILSupport" BO_ 2549088326 1;
BA_ "GenMsgSendType" BO_ 2549088326 0;
BA_ "VFrameFormat" BO_ 2549088326 15;
BA_ "GenMsgCycleTime" BO_ 779 50;
BA_ "GenMsgILSupport" BO_ 779 1;
BA_ "GenMsgSendType" BO_ 779 0;
BA_ "VFrameFormat" BO_ 779 14;
BA_ "GenMsgCycleTime" BO_ 1719 1000;
BA_ "GenMsgDelayTime" BO_ 1719 100;
BA_ "GenMsgILSupport" BO_ 1719 1;
BA_ "GenMsgSendType" BO_ 1719 0;
BA_ "VFrameFormat" BO_ 1719 14;
BA_ "GenMsgCycleTime" BO_ 2527679639 1000;
BA_ "GenMsgCycleTimeFast" BO_ 2527679639 100;
BA_ "GenMsgDelayTime" BO_ 2527679639 100;
BA_ "GenMsgILSupport" BO_ 2527679639 1;
BA_ "GenMsgNrOfRepetition" BO_ 2527679639 5;
BA_ "GenMsgSendType" BO_ 2527679639 0;
BA_ "VFrameFormat" BO_ 2527679639 15;
BA_ "GenMsgCycleTime" BO_ 2589283631 500;
BA_ "GenMsgILSupport" BO_ 2589283631 1;
BA_ "GenMsgSendType" BO_ 2589283631 0;
BA_ "VFrameFormat" BO_ 2589283631 15;
BA_ "MsgType" BO_ 2621440379 4;
BA_ "VFrameFormat" BO_ 2621440379 15;
BA_ "MsgType" BO_ 2621571451 4;
BA_ "VFrameFormat" BO_ 2621571451 15;
BA_ "GenMsgCycleTime" BO_ 822 120;
BA_ "GenMsgILSupport" BO_ 822 1;
BA_ "GenMsgSendType" BO_ 822 0;
BA_ "VFrameFormat" BO_ 822 14;
BA_ "GenMsgCycleTime" BO_ 2527679633 200;
BA_ "GenMsgILSupport" BO_ 2527679633 1;
BA_ "GenMsgSendType" BO_ 2527679633 0;
BA_ "VFrameFormat" BO_ 2527679633 15;
BA_ "GenMsgCycleTime" BO_ 2527679634 200;
BA_ "GenMsgILSupport" BO_ 2527679634 1;
BA_ "GenMsgSendType" BO_ 2527679634 0;
BA_ "VFrameFormat" BO_ 2527679634 15;
BA_ "GenMsgCycleTime" BO_ 1164 200;
BA_ "GenMsgCycleTimeFast" BO_ 1164 50;
BA_ "GenMsgDelayTime" BO_ 1164 20;
BA_ "GenMsgILSupport" BO_ 1164 1;
BA_ "GenMsgNrOfRepetition" BO_ 1164 5;
BA_ "GenMsgSendType" BO_ 1164 0;
BA_ "VFrameFormat" BO_ 1164 14;
BA_ "GenMsgCycleTimeFast" BO_ 1471 1000;
BA_ "GenMsgDelayTime" BO_ 1471 30;
BA_ "GenMsgILSupport" BO_ 1471 1;
BA_ "GenMsgNrOfRepetition" BO_ 1471 5;
BA_ "VFrameFormat" BO_ 1471 14;
BA_ "GenMsgCycleTime" BO_ 1600 500;
BA_ "GenMsgILSupport" BO_ 1600 1;
BA_ "GenMsgSendType" BO_ 1600 0;
BA_ "VFrameFormat" BO_ 1600 14;
BA_ "GenSigActiveRepetitions" SG_ 1640 FSH_Taster 5;
BA_ "GenSigSendType" SG_ 1640 FSH_Taster 4;
BA_ "GenSigSwitchedByIgnition" SG_ 1640 FSH_Taster 0;
BA_ "GenSigActiveRepetitions" SG_ 1640 HSH_Taster 5;
BA_ "GenSigSendType" SG_ 1640 HSH_Taster 4;
BA_ "GenSigSwitchedByIgnition" SG_ 1640 HSH_Taster 0;
BA_ "GenSigSendType" SG_ 1640 KL_Beschlagsgefahr 3;
BA_ "GenSigSwitchedByIgnition" SG_ 1640 KL_Beschlagsgefahr 0;
BA_ "GenSigSendType" SG_ 1640 KL_Geblspng_Fond_Soll 0;
BA_ "GenSigSwitchedByIgnition" SG_ 1640 KL_Geblspng_Fond_Soll 0;
BA_ "Fehlerwert" SG_ 1640 KL_Geblspng_Fond_Soll 255;
BA_ "GenSigSendType" SG_ 1640 KL_Geblspng_Soll 0;
BA_ "GenSigSwitchedByIgnition" SG_ 1640 KL_Geblspng_Soll 0;
BA_ "Fehlerwert" SG_ 1640 KL_Geblspng_Soll 255;
BA_ "GenSigSendType" SG_ 1640 KL_I_Geblaese 0;
BA_ "GenSigSwitchedByIgnition" SG_ 1640 KL_I_Geblaese 0;
BA_ "Fehlerwert" SG_ 1640 KL_I_Geblaese 255;
BA_ "GenSigSendType" SG_ 1640 KL_Kompressorstrom_soll 0;
BA_ "GenSigStartValue" SG_ 1640 KL_Kompressorstrom_soll 1022;
BA_ "GenSigSwitchedByIgnition" SG_ 1640 KL_Kompressorstrom_soll 0;
BA_ "Fehlerwert" SG_ 1640 KL_Kompressorstrom_soll 1023;
BA_ "GenSigSendType" SG_ 1640 KL_LRH_Stufe 3;
BA_ "GenSigStartValue" SG_ 1640 KL_LRH_Stufe 1;
BA_ "GenSigSwitchedByIgnition" SG_ 1640 KL_LRH_Stufe 0;
BA_ "GenSigActiveRepetitions" SG_ 1640 KL_LRH_Taster 5;
BA_ "GenSigSendType" SG_ 1640 KL_LRH_Taster 4;
BA_ "GenSigSwitchedByIgnition" SG_ 1640 KL_LRH_Taster 0;
BA_ "GenSigSendType" SG_ 1640 KL_PTC_Verbauinfo 0;
BA_ "GenSigSwitchedByIgnition" SG_ 1640 KL_PTC_Verbauinfo 0;
BA_ "GenSigSendType" SG_ 1640 KL_SIH_Soll_li 3;
BA_ "GenSigSwitchedByIgnition" SG_ 1640 KL_SIH_Soll_li 0;
BA_ "GenSigSendType" SG_ 1640 KL_SIH_Soll_re 3;
BA_ "GenSigSwitchedByIgnition" SG_ 1640 KL_SIH_Soll_re 0;
BA_ "GenSigSendType" SG_ 1640 KL_SIL_Soll_li 3;
BA_ "GenSigSwitchedByIgnition" SG_ 1640 KL_SIL_Soll_li 0;
BA_ "GenSigSendType" SG_ 1640 KL_SIL_Soll_re 3;
BA_ "GenSigSwitchedByIgnition" SG_ 1640 KL_SIL_Soll_re 0;
BA_ "GenSigSendType" SG_ 1640 KL_Umluftklappe_Status 0;
BA_ "GenSigStartValue" SG_ 1640 KL_Umluftklappe_Status 14;
BA_ "GenSigSwitchedByIgnition" SG_ 1640 KL_Umluftklappe_Status 0;
BA_ "Fehlerwert" SG_ 1640 KL_Umluftklappe_Status 15;
BA_ "GenSigSendType" SG_ 1640 KL_Zuheizer_Freigabe 3;
BA_ "GenSigSwitchedByIgnition" SG_ 1640 KL_Zuheizer_Freigabe 0;
BA_ "GenSigSendType" SG_ 1640 KRH_Soll_li 3;
BA_ "GenSigSwitchedByIgnition" SG_ 1640 KRH_Soll_li 0;
BA_ "GenSigSendType" SG_ 1640 KRH_Soll_re 3;
BA_ "GenSigSwitchedByIgnition" SG_ 1640 KRH_Soll_re 0;
BA_ "GenSigSendType" SG_ 2527679635 FSH_Status 0;
BA_ "GenSigSwitchedByIgnition" SG_ 2527679635 FSH_Status 0;
BA_ "Fehlerwert" SG_ 2527679635 FSH_Status 3;
BA_ "GenSigSendType" SG_ 2527679635 HSH_Relais_Anf 3;
BA_ "GenSigSwitchedByIgnition" SG_ 2527679635 HSH_Relais_Anf 0;
BA_ "GenSigSendType" SG_ 2527679635 KL_AL_HL_Anf 3;
BA_ "GenSigSwitchedByIgnition" SG_ 2527679635 KL_AL_HL_Anf 0;
BA_ "GenSigSendType" SG_ 2527679635 KL_AL_HR_Anf 3;
BA_ "GenSigSwitchedByIgnition" SG_ 2527679635 KL_AL_HR_Anf 0;
BA_ "GenSigSendType" SG_ 2527679635 KL_AL_VL_Anf 3;
BA_ "GenSigSwitchedByIgnition" SG_ 2527679635 KL_AL_VL_Anf 0;
BA_ "GenSigSendType" SG_ 2527679635 KL_AL_VR_Anf 3;
BA_ "GenSigSwitchedByIgnition" SG_ 2527679635 KL_AL_VR_Anf 0;
BA_ "GenSigSendType" SG_ 2527679635 KL_Defrost_LED 3;
BA_ "GenSigSwitchedByIgnition" SG_ 2527679635 KL_Defrost_LED 0;
BA_ "GenSigSendType" SG_ 2527679635 KL_FSH_LED 3;
BA_ "GenSigSwitchedByIgnition" SG_ 2527679635 KL_FSH_LED 0;
BA_ "GenSigSendType" SG_ 2527679635 KL_FSH_Soll 3;
BA_ "GenSigSwitchedByIgnition" SG_ 2527679635 KL_FSH_Soll 0;
BA_ "GenSigSendType" SG_ 2527679635 KL_Heizstufe_LSH 3;
BA_ "GenSigSwitchedByIgnition" SG_ 2527679635 KL_Heizstufe_LSH 0;
BA_ "Fehlerwert" SG_ 2527679635 KL_Heizstufe_LSH 15;
BA_ "GenSigSendType" SG_ 2527679635 KL_HSH_LED 3;
BA_ "GenSigSwitchedByIgnition" SG_ 2527679635 KL_HSH_LED 0;
BA_ "GenSigSendType" SG_ 2527679635 KL_HSH_Soll 3;
BA_ "GenSigSwitchedByIgnition" SG_ 2527679635 KL_HSH_Soll 0;
BA_ "GenSigSendType" SG_ 2527679635 KL_HUP_aktiv 3;
BA_ "GenSigSwitchedByIgnition" SG_ 2527679635 KL_HUP_aktiv 0;
BA_ "GenSigSendType" SG_ 2527679635 KL_Klappe_Status 3;
BA_ "GenSigSwitchedByIgnition" SG_ 2527679635 KL_Klappe_Status 0;
BA_ "GenSigSendType" SG_ 2527679635 KL_LRH_PWM 3;
BA_ "GenSigSwitchedByIgnition" SG_ 2527679635 KL_LRH_PWM 0;
BA_ "GenSigSendType" SG_ 2527679635 KL_LRH_Soll 3;
BA_ "GenSigSwitchedByIgnition" SG_ 2527679635 KL_LRH_Soll 0;
BA_ "GenSigSendType" SG_ 2527679635 KL_LSH_Ansteuerung 3;
BA_ "GenSigSwitchedByIgnition" SG_ 2527679635 KL_LSH_Ansteuerung 0;
BA_ "GenSigSendType" SG_ 2527679635 KL_LSH_Betriebsdauer 3;
BA_ "GenSigSwitchedByIgnition" SG_ 2527679635 KL_LSH_Betriebsdauer 0;
BA_ "GenSigSendType" SG_ 2527679635 KL_LSH_DBetr_Bestaet 3;
BA_ "GenSigSwitchedByIgnition" SG_ 2527679635 KL_LSH_DBetr_Bestaet 0;
BA_ "GenSigSendType" SG_ 2527679635 KL_LSH_DBetr_Ein 3;
BA_ "GenSigSwitchedByIgnition" SG_ 2527679635 KL_LSH_DBetr_Ein 0;
BA_ "GenSigSendType" SG_ 2527679635 KL_Temp_ZH_Soll 3;
BA_ "GenSigSwitchedByIgnition" SG_ 2527679635 KL_Temp_ZH_Soll 0;
BA_ "Fehlerwert" SG_ 2527679635 KL_Temp_ZH_Soll 255;
BA_ "GenSigSendType" SG_ 2527679635 KL_VoKo_LED 3;
BA_ "GenSigSwitchedByIgnition" SG_ 2527679635 KL_VoKo_LED 0;
BA_ "GenSigSendType" SG_ 2527679635 KL_Voko_Status 3;
BA_ "GenSigStartValue" SG_ 2527679635 KL_Voko_Status 14;
BA_ "GenSigSwitchedByIgnition" SG_ 2527679635 KL_Voko_Status 0;
BA_ "Fehlerwert" SG_ 2527679635 KL_Voko_Status 15;
BA_ "GenSigSendType" SG_ 2527679635 KL_ZR_Anforderung 3;
BA_ "GenSigSwitchedByIgnition" SG_ 2527679635 KL_ZR_Anforderung 0;
BA_ "GenSigSendType" SG_ 2527679635 SIH_Stufe_LED_li 3;
BA_ "GenSigSwitchedByIgnition" SG_ 2527679635 SIH_Stufe_LED_li 0;
BA_ "GenSigSendType" SG_ 2527679635 SIH_Stufe_LED_re 3;
BA_ "GenSigSwitchedByIgnition" SG_ 2527679635 SIH_Stufe_LED_re 0;
BA_ "GenSigSendType" SG_ 2589284015 KL_LRH_FoD_Status 0;
BA_ "GenSigSwitchedByIgnition" SG_ 2589284015 KL_LRH_FoD_Status 0;
BA_ "GenSigSendType" SG_ 2463978878 KL_Derivat 0;
BA_ "GenSigSwitchedByIgnition" SG_ 2463978878 KL_Derivat 0;
BA_ "Fehlerwert" SG_ 2463978878 KL_Derivat 1;
BA_ "GenSigSendType" SG_ 2463978878 KL_LRH_verfuegbar 0;
BA_ "GenSigSwitchedByIgnition" SG_ 2463978878 KL_LRH_verfuegbar 0;
BA_ "Fehlerwert" SG_ 2463978878 KL_LRH_verfuegbar 1;
BA_ "GenSigSendType" SG_ 2463978878 KL_ScheibenHZ_verfuegbar 0;
BA_ "GenSigSwitchedByIgnition" SG_ 2463978878 KL_ScheibenHZ_verfuegbar 0;
BA_ "Fehlerwert" SG_ 2463978878 KL_ScheibenHZ_verfuegbar 1;
BA_ "GenSigSendType" SG_ 2463978878 KL_SHZ_verfuegbar 0;
BA_ "GenSigSwitchedByIgnition" SG_ 2463978878 KL_SHZ_verfuegbar 0;
BA_ "GenSigSendType" SG_ 2463978878 KL_Variante 0;
BA_ "GenSigSwitchedByIgnition" SG_ 2463978878 KL_Variante 0;
BA_ "Fehlerwert" SG_ 2463978878 KL_Variante 1;
BA_ "GenSigSendType" SG_ 2463978878 KL_Verbauzustand 0;
BA_ "GenSigSwitchedByIgnition" SG_ 2463978878 KL_Verbauzustand 0;
BA_ "Fehlerwert" SG_ 2463978878 KL_Verbauzustand 1;
BA_ "GenSigSendType" SG_ 1511 KL_BattKond_WaPu_DZMax 0;
BA_ "GenSigStartValue" SG_ 1511 KL_BattKond_WaPu_DZMax 62;
BA_ "GenSigSwitchedByIgnition" SG_ 1511 KL_BattKond_WaPu_DZMax 0;
BA_ "Fehlerwert" SG_ 1511 KL_BattKond_WaPu_DZMax 63;
BA_ "GenSigSendType" SG_ 1511 KL_EKK_Strom 0;
BA_ "GenSigStartValue" SG_ 1511 KL_EKK_Strom 255;
BA_ "GenSigSwitchedByIgnition" SG_ 1511 KL_EKK_Strom 0;
BA_ "GenSigSendType" SG_ 1511 KL_Fehler_HV_EKK 0;
BA_ "GenSigSwitchedByIgnition" SG_ 1511 KL_Fehler_HV_EKK 0;
BA_ "Fehlerwert" SG_ 1511 KL_Fehler_HV_EKK 3;
BA_ "GenSigSendType" SG_ 1511 KL_Fehler_HV_Heizer 0;
BA_ "GenSigSwitchedByIgnition" SG_ 1511 KL_Fehler_HV_Heizer 0;
BA_ "Fehlerwert" SG_ 1511 KL_Fehler_HV_Heizer 3;
BA_ "GenSigSendType" SG_ 1511 KL_HV_Heizer_Strom 0;
BA_ "GenSigStartValue" SG_ 1511 KL_HV_Heizer_Strom 255;
BA_ "GenSigSwitchedByIgnition" SG_ 1511 KL_HV_Heizer_Strom 0;
BA_ "GenSigSendType" SG_ 1511 KL_KM_ASV_01_Status 0;
BA_ "GenSigSwitchedByIgnition" SG_ 1511 KL_KM_ASV_01_Status 0;
BA_ "Fehlerwert" SG_ 1511 KL_KM_ASV_01_Status 3;
BA_ "GenSigSendType" SG_ 1511 KL_KM_ASV_02_Status 0;
BA_ "GenSigSwitchedByIgnition" SG_ 1511 KL_KM_ASV_02_Status 0;
BA_ "Fehlerwert" SG_ 1511 KL_KM_ASV_02_Status 3;
BA_ "GenSigSendType" SG_ 1511 KL_Pumpe_02_Soll 0;
BA_ "GenSigStartValue" SG_ 1511 KL_Pumpe_02_Soll 126;
BA_ "GenSigSwitchedByIgnition" SG_ 1511 KL_Pumpe_02_Soll 0;
BA_ "Fehlerwert" SG_ 1511 KL_Pumpe_02_Soll 127;
BA_ "GenSigSendType" SG_ 1511 KL_Senderkennung 0;
BA_ "GenSigSwitchedByIgnition" SG_ 1511 KL_Senderkennung 0;
BA_ "GenSigSendType" SG_ 1511 KL_Status_EoHVL_EKK 0;
BA_ "GenSigSwitchedByIgnition" SG_ 1511 KL_Status_EoHVL_EKK 0;
BA_ "Fehlerwert" SG_ 1511 KL_Status_EoHVL_EKK 3;
BA_ "GenSigSendType" SG_ 1511 KL_Status_EoHVL_EKK_2 0;
BA_ "GenSigSwitchedByIgnition" SG_ 1511 KL_Status_EoHVL_EKK_2 0;
BA_ "Fehlerwert" SG_ 1511 KL_Status_EoHVL_EKK_2 3;
BA_ "GenSigSendType" SG_ 1511 KL_Status_EoHVL_Heizer 0;
BA_ "GenSigSwitchedByIgnition" SG_ 1511 KL_Status_EoHVL_Heizer 0;
BA_ "Fehlerwert" SG_ 1511 KL_Status_EoHVL_Heizer 3;
BA_ "GenSigSendType" SG_ 1511 KL_Status_EoHVL_Heizer_2 0;
BA_ "GenSigSwitchedByIgnition" SG_ 1511 KL_Status_EoHVL_Heizer_2 0;
BA_ "Fehlerwert" SG_ 1511 KL_Status_EoHVL_Heizer_2 3;
BA_ "GenSigSendType" SG_ 1511 KL_Ventil_03_Soll 0;
BA_ "GenSigSwitchedByIgnition" SG_ 1511 KL_Ventil_03_Soll 0;
BA_ "GenSigSendType" SG_ 1511 KL_Ventil_10_Status 0;
BA_ "GenSigStartValue" SG_ 1511 KL_Ventil_10_Status 6;
BA_ "GenSigSwitchedByIgnition" SG_ 1511 KL_Ventil_10_Status 0;
BA_ "Fehlerwert" SG_ 1511 KL_Ventil_10_Status 7;
BA_ "GenSigSendType" SG_ 1511 KL_Vorwarn_HVHeizer_Leistung 0;
BA_ "GenSigSwitchedByIgnition" SG_ 1511 KL_Vorwarn_HVHeizer_Leistung 0;
BA_ "Fehlerwert" SG_ 1511 KL_Vorwarn_HVHeizer_Leistung 15;
BA_ "GenSigSendType" SG_ 1511 WP_KJ_Soll 0;
BA_ "GenSigSwitchedByIgnition" SG_ 1511 WP_KJ_Soll 0;
BA_ "Fehlerwert" SG_ 1511 WP_KJ_Soll 3;
BA_ "GenSigSendType" SG_ 1511 WP_Kuehlerluefter_Anf 0;
BA_ "GenSigSwitchedByIgnition" SG_ 1511 WP_Kuehlerluefter_Anf 0;
BA_ "Fehlerwert" SG_ 1511 WP_Kuehlerluefter_Anf 255;
BA_ "GenSigSendType" SG_ 1514 KBT_Defrost_aktiv 0;
BA_ "GenSigSwitchedByIgnition" SG_ 1514 KBT_Defrost_aktiv 0;
BA_ "GenSigSendType" SG_ 1514 KL_Fehler_NTKreis 0;
BA_ "GenSigSwitchedByIgnition" SG_ 1514 KL_Fehler_NTKreis 0;
BA_ "Fehlerwert" SG_ 1514 KL_Fehler_NTKreis 1;
BA_ "GenSigSendType" SG_ 1514 KL_Heizbedarf 0;
BA_ "GenSigStartValue" SG_ 1514 KL_Heizbedarf 1022;
BA_ "GenSigSwitchedByIgnition" SG_ 1514 KL_Heizbedarf 0;
BA_ "Fehlerwert" SG_ 1514 KL_Heizbedarf 1023;
BA_ "GenSigSendType" SG_ 1514 KL_Innentemp_KBT_Sensor 0;
BA_ "GenSigStartValue" SG_ 1514 KL_Innentemp_KBT_Sensor 1022;
BA_ "GenSigSwitchedByIgnition" SG_ 1514 KL_Innentemp_KBT_Sensor 0;
BA_ "Fehlerwert" SG_ 1514 KL_Innentemp_KBT_Sensor 1023;
BA_ "GenSigSendType" SG_ 1514 KL_KLE_Fehler_Anf 0;
BA_ "GenSigSwitchedByIgnition" SG_ 1514 KL_KLE_Fehler_Anf 0;
BA_ "GenSigSendType" SG_ 1514 KL_Kundenwunsch_Kuehlen 0;
BA_ "GenSigSwitchedByIgnition" SG_ 1514 KL_Kundenwunsch_Kuehlen 0;
BA_ "GenSigSendType" SG_ 1514 KL_Mot_Tk_Soll_li 0;
BA_ "GenSigSwitchedByIgnition" SG_ 1514 KL_Mot_Tk_Soll_li 0;
BA_ "GenSigSendType" SG_ 1514 KL_Mot_Tk_Soll_re 0;
BA_ "GenSigSwitchedByIgnition" SG_ 1514 KL_Mot_Tk_Soll_re 0;
BA_ "GenSigSendType" SG_ 1514 KL_OBD_Status 0;
BA_ "GenSigSwitchedByIgnition" SG_ 1514 KL_OBD_Status 0;
BA_ "GenSigSendType" SG_ 1514 KL_Standklima_RemoteModus 0;
BA_ "GenSigSwitchedByIgnition" SG_ 1514 KL_Standklima_RemoteModus 0;
BA_ "GenSigSendType" SG_ 1514 KL_Standklima_Status_02 0;
BA_ "GenSigStartValue" SG_ 1514 KL_Standklima_Status_02 6;
BA_ "GenSigSwitchedByIgnition" SG_ 1514 KL_Standklima_Status_02 0;
BA_ "Fehlerwert" SG_ 1514 KL_Standklima_Status_02 7;
BA_ "GenSigSendType" SG_ 1514 KL_Standklima_Status_03 0;
BA_ "GenSigStartValue" SG_ 1514 KL_Standklima_Status_03 6;
BA_ "GenSigSwitchedByIgnition" SG_ 1514 KL_Standklima_Status_03 0;
BA_ "Fehlerwert" SG_ 1514 KL_Standklima_Status_03 7;
BA_ "GenSigSendType" SG_ 1514 KL_VK_Anf 0;
BA_ "GenSigStartValue" SG_ 1514 KL_VK_Anf 6;
BA_ "GenSigSwitchedByIgnition" SG_ 1514 KL_VK_Anf 0;
BA_ "Fehlerwert" SG_ 1514 KL_VK_Anf 7;
BA_ "GenSigSendType" SG_ 1514 KL_VK_Betriebsdauer 0;
BA_ "GenSigStartValue" SG_ 1514 KL_VK_Betriebsdauer 62;
BA_ "GenSigSwitchedByIgnition" SG_ 1514 KL_VK_Betriebsdauer 0;
BA_ "Fehlerwert" SG_ 1514 KL_VK_Betriebsdauer 63;
BA_ "GenSigSendType" SG_ 1514 KL_Vorkond_Strategie 0;
BA_ "GenSigStartValue" SG_ 1514 KL_Vorkond_Strategie 15;
BA_ "GenSigSwitchedByIgnition" SG_ 1514 KL_Vorkond_Strategie 0;
BA_ "GenSigSendType" SG_ 1515 KL_Abl_Ist_li 0;
BA_ "GenSigStartValue" SG_ 1515 KL_Abl_Ist_li 1022;
BA_ "GenSigSwitchedByIgnition" SG_ 1515 KL_Abl_Ist_li 0;
BA_ "Fehlerwert" SG_ 1515 KL_Abl_Ist_li 1023;
BA_ "GenSigSendType" SG_ 1515 KL_Abl_Ist_re 0;
BA_ "GenSigStartValue" SG_ 1515 KL_Abl_Ist_re 1022;
BA_ "GenSigSwitchedByIgnition" SG_ 1515 KL_Abl_Ist_re 0;
BA_ "Fehlerwert" SG_ 1515 KL_Abl_Ist_re 1023;
BA_ "GenSigSendType" SG_ 1515 KL_Abl_Soll_li 0;
BA_ "GenSigSwitchedByIgnition" SG_ 1515 KL_Abl_Soll_li 0;
BA_ "Fehlerwert" SG_ 1515 KL_Abl_Soll_li 255;
BA_ "GenSigSendType" SG_ 1515 KL_Abl_Soll_re 0;
BA_ "GenSigSwitchedByIgnition" SG_ 1515 KL_Abl_Soll_re 0;
BA_ "Fehlerwert" SG_ 1515 KL_Abl_Soll_re 255;
BA_ "GenSigSendType" SG_ 1515 KL_TaupEps_Korr 0;
BA_ "GenSigStartValue" SG_ 1515 KL_TaupEps_Korr 1022;
BA_ "GenSigSwitchedByIgnition" SG_ 1515 KL_TaupEps_Korr 0;
BA_ "Fehlerwert" SG_ 1515 KL_TaupEps_Korr 1023;
BA_ "GenSigSendType" SG_ 1515 KL_Verdampfer_Ist 0;
BA_ "GenSigSwitchedByIgnition" SG_ 1515 KL_Verdampfer_Ist 0;
BA_ "GenSigSendType" SG_ 1515 KL_Verdampfer_Soll 0;
BA_ "GenSigStartValue" SG_ 1515 KL_Verdampfer_Soll 254;
BA_ "GenSigSwitchedByIgnition" SG_ 1515 KL_Verdampfer_Soll 0;
BA_ "Fehlerwert" SG_ 1515 KL_Verdampfer_Soll 255;
BA_ "GenSigSendType" SG_ 2589283627 KL_EKK_1_VerbautStatus 0;
BA_ "GenSigSwitchedByIgnition" SG_ 2589283627 KL_EKK_1_VerbautStatus 0;
BA_ "GenSigSendType" SG_ 2589283627 KL_EKK_2_VerbautStatus 0;
BA_ "GenSigSwitchedByIgnition" SG_ 2589283627 KL_EKK_2_VerbautStatus 0;
BA_ "GenSigSendType" SG_ 2589283627 KL_Heizen_Status 0;
BA_ "GenSigStartValue" SG_ 2589283627 KL_Heizen_Status 14;
BA_ "GenSigSwitchedByIgnition" SG_ 2589283627 KL_Heizen_Status 0;
BA_ "Fehlerwert" SG_ 2589283627 KL_Heizen_Status 15;
BA_ "GenSigSendType" SG_ 2589283627 KL_HV_Energie_Anf 0;
BA_ "GenSigStartValue" SG_ 2589283627 KL_HV_Energie_Anf 254;
BA_ "GenSigSwitchedByIgnition" SG_ 2589283627 KL_HV_Energie_Anf 0;
BA_ "Fehlerwert" SG_ 2589283627 KL_HV_Energie_Anf 255;
BA_ "GenSigSendType" SG_ 2589283627 KL_HVH_1_VerbautStatus 0;
BA_ "GenSigSwitchedByIgnition" SG_ 2589283627 KL_HVH_1_VerbautStatus 0;
BA_ "GenSigSendType" SG_ 2589283627 KL_HVH_2_VerbautStatus 0;
BA_ "GenSigSwitchedByIgnition" SG_ 2589283627 KL_HVH_2_VerbautStatus 0;
BA_ "GenSigSendType" SG_ 2589283627 KL_IstLeistung 0;
BA_ "GenSigStartValue" SG_ 2589283627 KL_IstLeistung 254;
BA_ "GenSigSwitchedByIgnition" SG_ 2589283627 KL_IstLeistung 0;
BA_ "Fehlerwert" SG_ 2589283627 KL_IstLeistung 255;
BA_ "GenSigSendType" SG_ 2589283627 KL_K_Status 0;
BA_ "GenSigSwitchedByIgnition" SG_ 2589283627 KL_K_Status 0;
BA_ "Fehlerwert" SG_ 2589283627 KL_K_Status 14;
BA_ "GenSigSendType" SG_ 2589283627 Kl_Klima_Aktiv 0;
BA_ "GenSigSwitchedByIgnition" SG_ 2589283627 Kl_Klima_Aktiv 0;
BA_ "GenSigSendType" SG_ 2589283627 KL_Kuehlungs_Status 0;
BA_ "GenSigStartValue" SG_ 2589283627 KL_Kuehlungs_Status 14;
BA_ "GenSigSwitchedByIgnition" SG_ 2589283627 KL_Kuehlungs_Status 0;
BA_ "Fehlerwert" SG_ 2589283627 KL_Kuehlungs_Status 15;
BA_ "GenSigSendType" SG_ 2589283627 KL_Leistung_Klima_Anf 0;
BA_ "GenSigStartValue" SG_ 2589283627 KL_Leistung_Klima_Anf 254;
BA_ "GenSigSwitchedByIgnition" SG_ 2589283627 KL_Leistung_Klima_Anf 0;
BA_ "GenSigSendType" SG_ 2589283627 KL_Status_Battkuehlung 0;
BA_ "GenSigSwitchedByIgnition" SG_ 2589283627 KL_Status_Battkuehlung 0;
BA_ "GenSigSendType" SG_ 2589283627 KL_Temp_Kundenwunsch 0;
BA_ "GenSigSwitchedByIgnition" SG_ 2589283627 KL_Temp_Kundenwunsch 0;
BA_ "Fehlerwert" SG_ 2589283627 KL_Temp_Kundenwunsch 63;
BA_ "GenSigSendType" SG_ 2589283627 KL_Texte 0;
BA_ "GenSigSwitchedByIgnition" SG_ 2589283627 KL_Texte 0;
BA_ "GenSigSendType" SG_ 2589283627 TME_HVEM_HV_Anf 0;
BA_ "GenSigSwitchedByIgnition" SG_ 2589283627 TME_HVEM_HV_Anf 0;
BA_ "Fehlerwert" SG_ 2589283627 TME_HVEM_HV_Anf 3;
BA_ "GenSigSendType" SG_ 2463978771 KL_AQI_Innenraum 0;
BA_ "GenSigStartValue" SG_ 2463978771 KL_AQI_Innenraum 14;
BA_ "GenSigSwitchedByIgnition" SG_ 2463978771 KL_AQI_Innenraum 0;
BA_ "Fehlerwert" SG_ 2463978771 KL_AQI_Innenraum 15;
BA_ "GenSigSendType" SG_ 2463978771 KL_EKK_2_Status_Spgfreiheit 0;
BA_ "GenSigSwitchedByIgnition" SG_ 2463978771 KL_EKK_2_Status_Spgfreiheit 0;
BA_ "Fehlerwert" SG_ 2463978771 KL_EKK_2_Status_Spgfreiheit 3;
BA_ "GenSigSendType" SG_ 2463978771 KL_EKK_Status_Spgfreiheit 0;
BA_ "GenSigSwitchedByIgnition" SG_ 2463978771 KL_EKK_Status_Spgfreiheit 0;
BA_ "Fehlerwert" SG_ 2463978771 KL_EKK_Status_Spgfreiheit 3;
BA_ "GenSigSendType" SG_ 2463978771 KL_eTM_SollVolumenstrom 0;
BA_ "GenSigSendType" SG_ 2463978771 KL_HVH_2_Status_Spgfreiheit 0;
BA_ "GenSigSwitchedByIgnition" SG_ 2463978771 KL_HVH_2_Status_Spgfreiheit 0;
BA_ "Fehlerwert" SG_ 2463978771 KL_HVH_2_Status_Spgfreiheit 3;
BA_ "GenSigSendType" SG_ 2589283574 KL_OBD_Status_Auth 0;
BA_ "GenSigSwitchedByIgnition" SG_ 2589283574 KL_OBD_Status_Auth 0;
BA_ "GenSigSendType" SG_ 2589283574 OBDProtocol_Klima 0;
BA_ "GenSigStartValue" SG_ 2589283574 OBDProtocol_Klima 254;
BA_ "GenSigSwitchedByIgnition" SG_ 2589283574 OBDProtocol_Klima 0;
BA_ "Fehlerwert" SG_ 2589283574 OBDProtocol_Klima 255;
BA_ "GenSigSendType" SG_ 2589283574 SOK_Klima_EV_10_Signatur 0;
BA_ "GenSigFuncType" SG_ 2589283574 SOK_Klima_EV_10_Signatur 15;
BA_ "GenSigSwitchedByIgnition" SG_ 2589283574 SOK_Klima_EV_10_Signatur 0;
BA_ "GenSigSendType" SG_ 2527679641 KL_SL_Soll_hl 3;
BA_ "GenSigSwitchedByIgnition" SG_ 2527679641 KL_SL_Soll_hl 0;
BA_ "GenSigSendType" SG_ 2527679641 KL_SL_Soll_hr 3;
BA_ "GenSigSwitchedByIgnition" SG_ 2527679641 KL_SL_Soll_hr 0;
BA_ "GenSigSendType" SG_ 2527679641 KLh_SIH_Stufe_hl 3;
BA_ "GenSigSwitchedByIgnition" SG_ 2527679641 KLh_SIH_Stufe_hl 0;
BA_ "GenSigSendType" SG_ 2527679641 KLh_SIH_Stufe_hr 3;
BA_ "GenSigSwitchedByIgnition" SG_ 2527679641 KLh_SIH_Stufe_hr 0;
BA_ "GenSigSendType" SG_ 2527679641 KLhs_02_alt 0;
BA_ "GenSigStartValue" SG_ 2527679641 KLhs_02_alt 1;
BA_ "GenSigFuncType" SG_ 2527679641 KLhs_02_alt 5;
BA_ "GenSigSwitchedByIgnition" SG_ 2527679641 KLhs_02_alt 0;
BA_ "GenSigSendType" SG_ 2589283728 KL_SDA_AQS_COBereich 0;
BA_ "GenSigSwitchedByIgnition" SG_ 2589283728 KL_SDA_AQS_COBereich 0;
BA_ "GenSigSendType" SG_ 2589283728 KL_SDA_AQS_COStatus 0;
BA_ "GenSigSwitchedByIgnition" SG_ 2589283728 KL_SDA_AQS_COStatus 0;
BA_ "Fehlerwert" SG_ 2589283728 KL_SDA_AQS_COStatus 15;
BA_ "GenSigSendType" SG_ 2589283728 KL_SDA_AQS_NoxBereich 0;
BA_ "GenSigSwitchedByIgnition" SG_ 2589283728 KL_SDA_AQS_NoxBereich 0;
BA_ "GenSigSendType" SG_ 2589283728 KL_SDA_AQS_NoxStatus 0;
BA_ "GenSigSwitchedByIgnition" SG_ 2589283728 KL_SDA_AQS_NoxStatus 0;
BA_ "Fehlerwert" SG_ 2589283728 KL_SDA_AQS_NoxStatus 15;
BA_ "GenSigSendType" SG_ 2589283728 KL_SDA_AQS_Traffic 0;
BA_ "GenSigSwitchedByIgnition" SG_ 2589283728 KL_SDA_AQS_Traffic 0;
BA_ "GenSigSendType" SG_ 2589283728 KL_SDA_AQS_VOZBereich 0;
BA_ "GenSigSwitchedByIgnition" SG_ 2589283728 KL_SDA_AQS_VOZBereich 0;
BA_ "GenSigSendType" SG_ 2589283728 KL_SDA_AQS_VOZStatus 0;
BA_ "GenSigSwitchedByIgnition" SG_ 2589283728 KL_SDA_AQS_VOZStatus 0;
BA_ "Fehlerwert" SG_ 2589283728 KL_SDA_AQS_VOZStatus 15;
BA_ "GenSigSendType" SG_ 2589283728 KL_SDA_Klima_Automatik 0;
BA_ "GenSigSwitchedByIgnition" SG_ 2589283728 KL_SDA_Klima_Automatik 0;
BA_ "GenSigSendType" SG_ 2589283728 KL_SDA_Luft_Feinstaub 0;
BA_ "GenSigStartValue" SG_ 2589283728 KL_SDA_Luft_Feinstaub 254;
BA_ "GenSigSwitchedByIgnition" SG_ 2589283728 KL_SDA_Luft_Feinstaub 0;
BA_ "Fehlerwert" SG_ 2589283728 KL_SDA_Luft_Feinstaub 255;
BA_ "GenSigSendType" SG_ 2589283728 KL_SDA_Luft_Qualitaet 0;
BA_ "GenSigStartValue" SG_ 2589283728 KL_SDA_Luft_Qualitaet 14;
BA_ "GenSigSwitchedByIgnition" SG_ 2589283728 KL_SDA_Luft_Qualitaet 0;
BA_ "Fehlerwert" SG_ 2589283728 KL_SDA_Luft_Qualitaet 15;
BA_ "GenSigSendType" SG_ 2589283728 KL_SDA_Luftverteilung_Person 0;
BA_ "GenSigSwitchedByIgnition" SG_ 2589283728 KL_SDA_Luftverteilung_Person 0;
BA_ "GenSigSendType" SG_ 2589283728 KL_SDA_Luftverteilung_Scheibe 0;
BA_ "GenSigSwitchedByIgnition" SG_ 2589283728 KL_SDA_Luftverteilung_Scheibe 0;
BA_ "GenSigSendType" SG_ 2589283728 KL_SDA_Luftverteilung_Unten 0;
BA_ "GenSigSwitchedByIgnition" SG_ 2589283728 KL_SDA_Luftverteilung_Unten 0;
BA_ "GenSigSendType" SG_ 2589283728 KL_SDA_Menutaste 0;
BA_ "GenSigSwitchedByIgnition" SG_ 2589283728 KL_SDA_Menutaste 0;
BA_ "GenSigSendType" SG_ 2589283728 KL_SDA_Sitzheizung_VL 0;
BA_ "GenSigSwitchedByIgnition" SG_ 2589283728 KL_SDA_Sitzheizung_VL 0;
BA_ "GenSigSendType" SG_ 2589283728 KL_SDA_Sitzheizung_VR 0;
BA_ "GenSigSwitchedByIgnition" SG_ 2589283728 KL_SDA_Sitzheizung_VR 0;
BA_ "GenSigSendType" SG_ 2589283728 KL_SDA_Sitzlueftung_VL 0;
BA_ "GenSigSwitchedByIgnition" SG_ 2589283728 KL_SDA_Sitzlueftung_VL 0;
BA_ "GenSigSendType" SG_ 2589283728 KL_SDA_Sitzlueftung_VR 0;
BA_ "GenSigSwitchedByIgnition" SG_ 2589283728 KL_SDA_Sitzlueftung_VR 0;
BA_ "GenSigSendType" SG_ 2589283728 KL_SDA_Sonderfkt_AirCare 0;
BA_ "GenSigSwitchedByIgnition" SG_ 2589283728 KL_SDA_Sonderfkt_AirCare 0;
BA_ "GenSigSendType" SG_ 2589283728 KL_SDA_Sonderfkt_HSH 0;
BA_ "GenSigSwitchedByIgnition" SG_ 2589283728 KL_SDA_Sonderfkt_HSH 0;
BA_ "GenSigSendType" SG_ 2589283728 KL_SDA_Sonderfkt_MaxAC 0;
BA_ "GenSigSwitchedByIgnition" SG_ 2589283728 KL_SDA_Sonderfkt_MaxAC 0;
BA_ "GenSigSendType" SG_ 2589283728 KL_SDA_Sonderfkt_MaxDefrost 0;
BA_ "GenSigSwitchedByIgnition" SG_ 2589283728 KL_SDA_Sonderfkt_MaxDefrost 0;
BA_ "GenSigSendType" SG_ 2589283728 KL_SDA_Sonderfunktionen_Sprache 0;
BA_ "GenSigStartValue" SG_ 2589283728 KL_SDA_Sonderfunktionen_Sprache 30;
BA_ "GenSigSwitchedByIgnition" SG_ 2589283728 KL_SDA_Sonderfunktionen_Sprache 0;
BA_ "Fehlerwert" SG_ 2589283728 KL_SDA_Sonderfunktionen_Sprache 31;
BA_ "GenSigSendType" SG_ 2589283728 KL_SDA_Temp_Kundenwunsch_2 0;
BA_ "GenSigStartValue" SG_ 2589283728 KL_SDA_Temp_Kundenwunsch_2 16;
BA_ "GenSigSwitchedByIgnition" SG_ 2589283728 KL_SDA_Temp_Kundenwunsch_2 0;
BA_ "GenSigSendType" SG_ 2589283728 KL_SDA_Temp_Kundenwunsch_3 0;
BA_ "GenSigStartValue" SG_ 2589283728 KL_SDA_Temp_Kundenwunsch_3 16;
BA_ "GenSigSwitchedByIgnition" SG_ 2589283728 KL_SDA_Temp_Kundenwunsch_3 0;
BA_ "GenSigSendType" SG_ 1712 FS_Luftfeuchte_rel 0;
BA_ "Fehlerwert" SG_ 1712 FS_Luftfeuchte_rel 255;
BA_ "GenSigMissingSourceValue" SG_ 1712 FS_Luftfeuchte_rel 255;
BA_ "GenSigSendType" SG_ 1712 FS_ResponseError 0;
BA_ "Fehlerwert" SG_ 1712 FS_ResponseError 1;
BA_ "GenSigSendType" SG_ 1712 FS_Taupunkt 0;
BA_ "Fehlerwert" SG_ 1712 FS_Taupunkt 1023;
BA_ "GenSigMissingSourceValue" SG_ 1712 FS_Taupunkt 1023;
BA_ "GenSigSendType" SG_ 1712 FS_Temp_Scheibe 0;
BA_ "Fehlerwert" SG_ 1712 FS_Temp_Scheibe 1023;
BA_ "GenSigMissingSourceValue" SG_ 1712 FS_Temp_Scheibe 1023;
BA_ "GenSigSendType" SG_ 1712 FS_Temp_Sensor 0;
BA_ "Fehlerwert" SG_ 1712 FS_Temp_Sensor 255;
BA_ "GenSigMissingSourceValue" SG_ 1712 FS_Temp_Sensor 255;
BA_ "GenSigSendType" SG_ 1505 BCM1_Aussen_Temp_ungef 0;
BA_ "GenSigStartValue" SG_ 1505 BCM1_Aussen_Temp_ungef 254;
BA_ "GenSigSwitchedByIgnition" SG_ 1505 BCM1_Aussen_Temp_ungef 0;
BA_ "Fehlerwert" SG_ 1505 BCM1_Aussen_Temp_ungef 255;
BA_ "GenSigSendType" SG_ 1505 BCM1_FStatus_Aussentemp_ungef 0;
BA_ "GenSigStartValue" SG_ 1505 BCM1_FStatus_Aussentemp_ungef 1;
BA_ "GenSigSwitchedByIgnition" SG_ 1505 BCM1_FStatus_Aussentemp_ungef 0;
BA_ "GenSigSendType" SG_ 1505 BCM1_Kompressorstrom_ist 0;
BA_ "GenSigStartValue" SG_ 1505 BCM1_Kompressorstrom_ist 254;
BA_ "GenSigSwitchedByIgnition" SG_ 1505 BCM1_Kompressorstrom_ist 0;
BA_ "Fehlerwert" SG_ 1505 BCM1_Kompressorstrom_ist 255;
BA_ "GenSigSendType" SG_ 1505 BCM1_OBD_FStatus_ATemp 0;
BA_ "GenSigSwitchedByIgnition" SG_ 1505 BCM1_OBD_FStatus_ATemp 0;
BA_ "GenSigSendType" SG_ 1505 BCM1_PTC_stufig_Status 0;
BA_ "GenSigStartValue" SG_ 1505 BCM1_PTC_stufig_Status 6;
BA_ "GenSigSwitchedByIgnition" SG_ 1505 BCM1_PTC_stufig_Status 0;
BA_ "Fehlerwert" SG_ 1505 BCM1_PTC_stufig_Status 7;
BA_ "GenSigSendType" SG_ 1505 BCM_Heizungsabsperrventil_Status 0;
BA_ "GenSigStartValue" SG_ 1505 BCM_Heizungsabsperrventil_Status 2;
BA_ "GenSigSwitchedByIgnition" SG_ 1505 BCM_Heizungsabsperrventil_Status 0;
BA_ "Fehlerwert" SG_ 1505 BCM_Heizungsabsperrventil_Status 3;
BA_ "GenSigSendType" SG_ 1505 BCM_Heizungspumpe_Status 0;
BA_ "GenSigStartValue" SG_ 1505 BCM_Heizungspumpe_Status 2;
BA_ "GenSigSwitchedByIgnition" SG_ 1505 BCM_Heizungspumpe_Status 0;
BA_ "Fehlerwert" SG_ 1505 BCM_Heizungspumpe_Status 3;
BA_ "GenSigSendType" SG_ 1505 BCM_Kompressorkupplung_Status 0;
BA_ "GenSigStartValue" SG_ 1505 BCM_Kompressorkupplung_Status 2;
BA_ "GenSigSwitchedByIgnition" SG_ 1505 BCM_Kompressorkupplung_Status 0;
BA_ "Fehlerwert" SG_ 1505 BCM_Kompressorkupplung_Status 3;
BA_ "GenSigSendType" SG_ 1717 FSA_Err_Defekt_HumSens_TNCTOC 0;
BA_ "GenSigStartValue" SG_ 1717 FSA_Err_Defekt_HumSens_TNCTOC 1;
BA_ "GenSigSwitchedByIgnition" SG_ 1717 FSA_Err_Defekt_HumSens_TNCTOC 0;
BA_ "GenSigSendType" SG_ 1717 FSA_Err_Defekt_HumSense_TF 0;
BA_ "GenSigSwitchedByIgnition" SG_ 1717 FSA_Err_Defekt_HumSense_TF 0;
BA_ "GenSigSendType" SG_ 1717 FSA_Err_Defekt_Tsens_TF 0;
BA_ "GenSigSwitchedByIgnition" SG_ 1717 FSA_Err_Defekt_Tsens_TF 0;
BA_ "GenSigSendType" SG_ 1717 FSA_Err_RAMROM_Check_TF 0;
BA_ "GenSigSwitchedByIgnition" SG_ 1717 FSA_Err_RAMROM_Check_TF 0;
BA_ "GenSigSendType" SG_ 1717 FSA_Err_RAMROM_Check_TNCTOC 0;
BA_ "GenSigStartValue" SG_ 1717 FSA_Err_RAMROM_Check_TNCTOC 1;
BA_ "GenSigSwitchedByIgnition" SG_ 1717 FSA_Err_RAMROM_Check_TNCTOC 0;
BA_ "GenSigSendType" SG_ 1717 FSA_Err_Ueberspannung_TF 0;
BA_ "GenSigSwitchedByIgnition" SG_ 1717 FSA_Err_Ueberspannung_TF 0;
BA_ "GenSigSendType" SG_ 1717 FSA_Err_Unterspannung_TF 0;
BA_ "GenSigSwitchedByIgnition" SG_ 1717 FSA_Err_Unterspannung_TF 0;
BA_ "GenSigSendType" SG_ 1717 FSA_ErrMemState 0;
BA_ "GenSigSwitchedByIgnition" SG_ 1717 FSA_ErrMemState 0;
BA_ "GenSigSendType" SG_ 1717 FSA_HW 0;
BA_ "GenSigSendType" SG_ 1717 FSA_Luftfeuchte_rel 0;
BA_ "GenSigStartValue" SG_ 1717 FSA_Luftfeuchte_rel 254;
BA_ "Fehlerwert" SG_ 1717 FSA_Luftfeuchte_rel 255;
BA_ "GenSigSendType" SG_ 1717 FSA_Luftfeuchte_TF 0;
BA_ "GenSigSwitchedByIgnition" SG_ 1717 FSA_Luftfeuchte_TF 0;
BA_ "GenSigSendType" SG_ 1717 FSA_Luftfeuchte_TNCTOC 0;
BA_ "GenSigStartValue" SG_ 1717 FSA_Luftfeuchte_TNCTOC 1;
BA_ "GenSigSwitchedByIgnition" SG_ 1717 FSA_Luftfeuchte_TNCTOC 0;
BA_ "GenSigSendType" SG_ 1717 FSA_ResponseError 0;
BA_ "Fehlerwert" SG_ 1717 FSA_ResponseError 1;
BA_ "GenSigSendType" SG_ 1717 FSA_Sensorheizung_Status 0;
BA_ "GenSigSendType" SG_ 1717 FSA_SW 0;
BA_ "GenSigSendType" SG_ 1717 FSA_Taupunkt 0;
BA_ "GenSigStartValue" SG_ 1717 FSA_Taupunkt 1022;
BA_ "Fehlerwert" SG_ 1717 FSA_Taupunkt 1023;
BA_ "GenSigSendType" SG_ 1717 FSA_Temp_Luft 0;
BA_ "GenSigStartValue" SG_ 1717 FSA_Temp_Luft 1022;
BA_ "Fehlerwert" SG_ 1717 FSA_Temp_Luft 1023;
BA_ "GenSigSendType" SG_ 1717 FSA_Temp_Sensor 0;
BA_ "GenSigStartValue" SG_ 1717 FSA_Temp_Sensor 2046;
BA_ "Fehlerwert" SG_ 1717 FSA_Temp_Sensor 2047;
BA_ "GenSigSendType" SG_ 1513 AAU_Geblaese 0;
BA_ "GenSigStartValue" SG_ 1513 AAU_Geblaese 126;
BA_ "GenSigSwitchedByIgnition" SG_ 1513 AAU_Geblaese 0;
BA_ "Fehlerwert" SG_ 1513 AAU_Geblaese 127;
BA_ "GenSigSendType" SG_ 1513 DS_Kaeltemittel_P 0;
BA_ "GenSigStartValue" SG_ 1513 DS_Kaeltemittel_P 2046;
BA_ "GenSigSwitchedByIgnition" SG_ 1513 DS_Kaeltemittel_P 0;
BA_ "Fehlerwert" SG_ 1513 DS_Kaeltemittel_P 2047;
BA_ "GenSigSendType" SG_ 1513 DS_Kaeltemittel_P_WP 0;
BA_ "GenSigStartValue" SG_ 1513 DS_Kaeltemittel_P_WP 2046;
BA_ "GenSigSwitchedByIgnition" SG_ 1513 DS_Kaeltemittel_P_WP 0;
BA_ "Fehlerwert" SG_ 1513 DS_Kaeltemittel_P_WP 2047;
BA_ "GenSigSendType" SG_ 1513 DS_Status 0;
BA_ "GenSigStartValue" SG_ 1513 DS_Status 2;
BA_ "GenSigSwitchedByIgnition" SG_ 1513 DS_Status 0;
BA_ "Fehlerwert" SG_ 1513 DS_Status 3;
BA_ "GenSigSendType" SG_ 1513 ION_Status 0;
BA_ "GenSigStartValue" SG_ 1513 ION_Status 2;
BA_ "GenSigSendType" SG_ 1513 ION_Status_LED 0;
BA_ "GenSigSendType" SG_ 1513 ION_Status_Taster 0;
BA_ "GenSigSendType" SG_ 2549088581 BMS_NV_Abschaltstufe 0;
BA_ "GenSigSwitchedByIgnition" SG_ 2549088581 BMS_NV_Abschaltstufe 0;
BA_ "GenSigSendType" SG_ 2549088581 BMS_NV_KD_Fehler 0;
BA_ "GenSigSwitchedByIgnition" SG_ 2549088581 BMS_NV_KD_Fehler 0;
BA_ "GenSigSendType" SG_ 2549088581 BMS_NV_KompSchutz 0;
BA_ "GenSigSwitchedByIgnition" SG_ 2549088581 BMS_NV_KompSchutz 0;
BA_ "GenSigSendType" SG_ 2549088581 BMS_NV_Nachlauftyp 0;
BA_ "GenSigStartValue" SG_ 2549088581 BMS_NV_Nachlauftyp 2;
BA_ "GenSigSwitchedByIgnition" SG_ 2549088581 BMS_NV_Nachlauftyp 0;
BA_ "GenSigSendType" SG_ 2549088581 BMS_NV_Transport_Mode 0;
BA_ "GenSigSwitchedByIgnition" SG_ 2549088581 BMS_NV_Transport_Mode 0;
BA_ "GenSigSendType" SG_ 2549088581 KN_BMS_NV_BusKnockOut 0;
BA_ "GenSigSwitchedByIgnition" SG_ 2549088581 KN_BMS_NV_BusKnockOut 0;
BA_ "GenSigSendType" SG_ 2549088581 KN_BMS_NV_BusKnockOutTimer 0;
BA_ "GenSigSwitchedByIgnition" SG_ 2549088581 KN_BMS_NV_BusKnockOutTimer 0;
BA_ "GenSigSendType" SG_ 2549088581 KN_BMS_NV_DiagPfad 0;
BA_ "GenSigSwitchedByIgnition" SG_ 2549088581 KN_BMS_NV_DiagPfad 0;
BA_ "GenSigSendType" SG_ 2549088581 KN_BMS_NV_ECUKnockOut 0;
BA_ "GenSigSwitchedByIgnition" SG_ 2549088581 KN_BMS_NV_ECUKnockOut 0;
BA_ "GenSigSendType" SG_ 2549088581 KN_BMS_NV_ECUKnockOutTimer 0;
BA_ "GenSigSwitchedByIgnition" SG_ 2549088581 KN_BMS_NV_ECUKnockOutTimer 0;
BA_ "GenSigSendType" SG_ 2549088581 NM_BMS_NV_Wakeup 0;
BA_ "GenSigSwitchedByIgnition" SG_ 2549088581 NM_BMS_NV_Wakeup 0;
BA_ "GenSigSendType" SG_ 2549088272 Gateway_Abschaltstufe 0;
BA_ "GenSigSwitchedByIgnition" SG_ 2549088272 Gateway_Abschaltstufe 0;
BA_ "GenSigSendType" SG_ 2549088272 Gateway_KompSchutz 0;
BA_ "GenSigSwitchedByIgnition" SG_ 2549088272 Gateway_KompSchutz 0;
BA_ "GenSigSendType" SG_ 2549088272 Gateway_Nachlauftyp 0;
BA_ "GenSigStartValue" SG_ 2549088272 Gateway_Nachlauftyp 2;
BA_ "GenSigSwitchedByIgnition" SG_ 2549088272 Gateway_Nachlauftyp 0;
BA_ "GenSigSendType" SG_ 2549088272 Gateway_Transport_Mode 0;
BA_ "GenSigSwitchedByIgnition" SG_ 2549088272 Gateway_Transport_Mode 0;
BA_ "GenSigSendType" SG_ 2549088272 GW_KD_Fehler 0;
BA_ "GenSigSendType" SG_ 2549088272 KN_GW_DiagPfad 0;
BA_ "GenSigSwitchedByIgnition" SG_ 2549088272 KN_GW_DiagPfad 0;
BA_ "GenSigSendType" SG_ 2549088272 NM_Gateway_Wakeup 0;
BA_ "NWM-WakeupAllowed" SG_ 2549088272 NM_Gateway_Wakeup 1;
BA_ "GenSigSwitchedByIgnition" SG_ 2549088272 NM_Gateway_Wakeup 0;
BA_ "GenSigSendType" SG_ 2549088326 KL_KD_Fehler 0;
BA_ "GenSigSwitchedByIgnition" SG_ 2549088326 KL_KD_Fehler 0;
BA_ "GenSigSendType" SG_ 2549088326 Klima_Abschaltstufe 0;
BA_ "GenSigSwitchedByIgnition" SG_ 2549088326 Klima_Abschaltstufe 0;
BA_ "GenSigSendType" SG_ 2549088326 Klima_KompSchutz 0;
BA_ "GenSigSwitchedByIgnition" SG_ 2549088326 Klima_KompSchutz 0;
BA_ "GenSigSendType" SG_ 2549088326 Klima_Nachlauftyp 0;
BA_ "GenSigStartValue" SG_ 2549088326 Klima_Nachlauftyp 2;
BA_ "GenSigSwitchedByIgnition" SG_ 2549088326 Klima_Nachlauftyp 0;
BA_ "GenSigSendType" SG_ 2549088326 Klima_Transport_Mode 0;
BA_ "GenSigSwitchedByIgnition" SG_ 2549088326 Klima_Transport_Mode 0;
BA_ "GenSigSendType" SG_ 2549088326 KN_KL_DiagPfad 0;
BA_ "GenSigSwitchedByIgnition" SG_ 2549088326 KN_KL_DiagPfad 0;
BA_ "GenSigSendType" SG_ 2549088326 KN_Klima_BusKnockOut 0;
BA_ "GenSigSwitchedByIgnition" SG_ 2549088326 KN_Klima_BusKnockOut 0;
BA_ "GenSigSendType" SG_ 2549088326 KN_Klima_BusKnockOutTimer 0;
BA_ "GenSigSwitchedByIgnition" SG_ 2549088326 KN_Klima_BusKnockOutTimer 0;
BA_ "GenSigSendType" SG_ 2549088326 KN_Klima_ECUKnockOut 0;
BA_ "GenSigSwitchedByIgnition" SG_ 2549088326 KN_Klima_ECUKnockOut 0;
BA_ "GenSigSendType" SG_ 2549088326 KN_Klima_ECUKnockOutTimer 0;
BA_ "GenSigSwitchedByIgnition" SG_ 2549088326 KN_Klima_ECUKnockOutTimer 0;
BA_ "GenSigSendType" SG_ 2549088326 NM_Klima_Lokalaktiv 0;
BA_ "GenSigSwitchedByIgnition" SG_ 2549088326 NM_Klima_Lokalaktiv 0;
BA_ "GenSigSendType" SG_ 2549088326 NM_Klima_Subsystemaktiv 0;
BA_ "GenSigSwitchedByIgnition" SG_ 2549088326 NM_Klima_Subsystemaktiv 0;
BA_ "GenSigSendType" SG_ 2549088326 NM_Klima_Wakeup 0;
BA_ "NWM-WakeupAllowed" SG_ 2549088326 NM_Klima_Wakeup 1;
BA_ "GenSigSwitchedByIgnition" SG_ 2549088326 NM_Klima_Wakeup 0;
BA_ "GenSigSendType" SG_ 779 KBI_ABS_Lampe 0;
BA_ "GenSigSwitchedByIgnition" SG_ 779 KBI_ABS_Lampe 0;
BA_ "GenSigSendType" SG_ 779 KBI_Airbag_Lampe 0;
BA_ "GenSigSwitchedByIgnition" SG_ 779 KBI_Airbag_Lampe 0;
BA_ "GenSigSendType" SG_ 779 KBI_angez_Geschw 0;
BA_ "GenSigSwitchedByIgnition" SG_ 779 KBI_angez_Geschw 0;
BA_ "GenSigSendType" SG_ 779 KBI_Anzeigefehler_LDW 0;
BA_ "GenSigSwitchedByIgnition" SG_ 779 KBI_Anzeigefehler_LDW 0;
BA_ "GenSigSendType" SG_ 779 KBI_Anzeigefehler_NV 0;
BA_ "GenSigSwitchedByIgnition" SG_ 779 KBI_Anzeigefehler_NV 0;
BA_ "GenSigSendType" SG_ 779 KBI_Anzeigefehler_SWA 0;
BA_ "GenSigSwitchedByIgnition" SG_ 779 KBI_Anzeigefehler_SWA 0;
BA_ "GenSigSendType" SG_ 779 KBI_Anzeigestatus_ACC 0;
BA_ "GenSigSwitchedByIgnition" SG_ 779 KBI_Anzeigestatus_ACC 0;
BA_ "GenSigSendType" SG_ 779 KBI_Anzeigestatus_GRA 0;
BA_ "GenSigSwitchedByIgnition" SG_ 779 KBI_Anzeigestatus_GRA 0;
BA_ "Fehlerwert" SG_ 779 KBI_Anzeigestatus_GRA 3;
BA_ "GenSigSendType" SG_ 779 KBI_Anzeigestatus_LIM 0;
BA_ "GenSigSwitchedByIgnition" SG_ 779 KBI_Anzeigestatus_LIM 0;
BA_ "Fehlerwert" SG_ 779 KBI_Anzeigestatus_LIM 3;
BA_ "GenSigSendType" SG_ 779 KBI_Anzeigestatus_RHP 0;
BA_ "GenSigSwitchedByIgnition" SG_ 779 KBI_Anzeigestatus_RHP 0;
BA_ "GenSigSendType" SG_ 779 KBI_ARA_in_Anzeige 0;
BA_ "GenSigSwitchedByIgnition" SG_ 779 KBI_ARA_in_Anzeige 0;
BA_ "GenSigSendType" SG_ 779 KBI_Audioabsenkung_MIB 0;
BA_ "GenSigSwitchedByIgnition" SG_ 779 KBI_Audioabsenkung_MIB 0;
BA_ "GenSigSendType" SG_ 779 KBI_Bestaetigung_ESP_Off 0;
BA_ "GenSigSwitchedByIgnition" SG_ 779 KBI_Bestaetigung_ESP_Off 0;
BA_ "GenSigSendType" SG_ 779 KBI_BKL_Lampe 0;
BA_ "GenSigSwitchedByIgnition" SG_ 779 KBI_BKL_Lampe 0;
BA_ "GenSigSendType" SG_ 779 KBI_ESP_Lampe 0;
BA_ "GenSigSwitchedByIgnition" SG_ 779 KBI_ESP_Lampe 0;
BA_ "GenSigSendType" SG_ 779 KBI_Fehler_Anzeige_ACC 0;
BA_ "GenSigSwitchedByIgnition" SG_ 779 KBI_Fehler_Anzeige_ACC 0;
BA_ "GenSigSendType" SG_ 779 KBI_Handbremse 0;
BA_ "GenSigSwitchedByIgnition" SG_ 779 KBI_Handbremse 0;
BA_ "GenSigSendType" SG_ 779 KBI_im_Stellgliedtest 0;
BA_ "GenSigSwitchedByIgnition" SG_ 779 KBI_im_Stellgliedtest 0;
BA_ "GenSigSendType" SG_ 779 KBI_Konsistenz_ACC 0;
BA_ "GenSigSwitchedByIgnition" SG_ 779 KBI_Konsistenz_ACC 0;
BA_ "GenSigSendType" SG_ 779 KBI_Lenkung_Lampe 0;
BA_ "GenSigSwitchedByIgnition" SG_ 779 KBI_Lenkung_Lampe 0;
BA_ "GenSigSendType" SG_ 779 KBI_MFA_v_Einheit_01 0;
BA_ "GenSigSwitchedByIgnition" SG_ 779 KBI_MFA_v_Einheit_01 0;
BA_ "GenSigSendType" SG_ 779 KBI_NV_in_Anzeige 0;
BA_ "GenSigSwitchedByIgnition" SG_ 779 KBI_NV_in_Anzeige 0;
BA_ "GenSigSendType" SG_ 779 KBI_Oeldruck_Schalter 0;
BA_ "GenSigSwitchedByIgnition" SG_ 779 KBI_Oeldruck_Schalter 0;
BA_ "GenSigSendType" SG_ 779 KBI_Oeldruckwarnung 0;
BA_ "GenSigSwitchedByIgnition" SG_ 779 KBI_Oeldruckwarnung 0;
BA_ "GenSigSendType" SG_ 779 KBI_PLA_in_Anzeige 0;
BA_ "GenSigSwitchedByIgnition" SG_ 779 KBI_PLA_in_Anzeige 0;
BA_ "GenSigSendType" SG_ 779 KBI_SILA_gueltig 0;
BA_ "GenSigSwitchedByIgnition" SG_ 779 KBI_SILA_gueltig 0;
BA_ "GenSigSendType" SG_ 779 KBI_Systemstatus 0;
BA_ "GenSigSwitchedByIgnition" SG_ 779 KBI_Systemstatus 0;
BA_ "GenSigSendType" SG_ 779 KBI_Tankwarnung 0;
BA_ "GenSigSwitchedByIgnition" SG_ 779 KBI_Tankwarnung 0;
BA_ "GenSigSendType" SG_ 779 KBI_Tankwarnung_ungueltig 0;
BA_ "GenSigStartValue" SG_ 779 KBI_Tankwarnung_ungueltig 1;
BA_ "GenSigSwitchedByIgnition" SG_ 779 KBI_Tankwarnung_ungueltig 0;
BA_ "GenSigSendType" SG_ 779 KBI_Taster_Fahrwerk 0;
BA_ "GenSigSwitchedByIgnition" SG_ 779 KBI_Taster_Fahrwerk 0;
BA_ "GenSigSendType" SG_ 779 KBI_Taster_Lift 0;
BA_ "GenSigSwitchedByIgnition" SG_ 779 KBI_Taster_Lift 0;
BA_ "GenSigSendType" SG_ 779 KBI_V_Digital 0;
BA_ "GenSigSwitchedByIgnition" SG_ 779 KBI_V_Digital 0;
BA_ "GenSigSendType" SG_ 779 KBI_Vorglueh_System_Lampe 0;
BA_ "GenSigSwitchedByIgnition" SG_ 779 KBI_Vorglueh_System_Lampe 0;
BA_ "GenSigSendType" SG_ 779 Kombi_01_BZ 0;
BA_ "GenSigFuncType" SG_ 779 Kombi_01_BZ 1;
BA_ "GenSigSwitchedByIgnition" SG_ 779 Kombi_01_BZ 0;
BA_ "GenSigSendType" SG_ 1719 KBI_aktive_Laengsfunktion_02 3;
BA_ "GenSigSendType" SG_ 1719 KBI_Aussen_Temp_gef 0;
BA_ "GenSigStartValue" SG_ 1719 KBI_Aussen_Temp_gef 254;
BA_ "GenSigSwitchedByIgnition" SG_ 1719 KBI_Aussen_Temp_gef 0;
BA_ "Fehlerwert" SG_ 1719 KBI_Aussen_Temp_gef 255;
BA_ "GenSigSendType" SG_ 1719 KBI_FoD_PopUP_Quittiert 3;
BA_ "GenSigSendType" SG_ 1719 KBI_FStatus_Tank 0;
BA_ "GenSigSwitchedByIgnition" SG_ 1719 KBI_FStatus_Tank 0;
BA_ "GenSigSendType" SG_ 1719 KBI_GRA_im_ACC 3;
BA_ "GenSigSwitchedByIgnition" SG_ 1719 KBI_GRA_im_ACC 0;
BA_ "GenSigSendType" SG_ 1719 KBI_Inhalt_Tank 0;
BA_ "GenSigStartValue" SG_ 1719 KBI_Inhalt_Tank 126;
BA_ "GenSigSwitchedByIgnition" SG_ 1719 KBI_Inhalt_Tank 0;
BA_ "Fehlerwert" SG_ 1719 KBI_Inhalt_Tank 127;
BA_ "GenSigSendType" SG_ 1719 KBI_Kilometerstand 0;
BA_ "GenSigStartValue" SG_ 1719 KBI_Kilometerstand 1048574;
BA_ "GenSigSwitchedByIgnition" SG_ 1719 KBI_Kilometerstand 0;
BA_ "Fehlerwert" SG_ 1719 KBI_Kilometerstand 1048575;
BA_ "GenSigSendType" SG_ 1719 KBI_Oelwechsel_durchgefuehrt 0;
BA_ "GenSigSwitchedByIgnition" SG_ 1719 KBI_Oelwechsel_durchgefuehrt 0;
BA_ "GenSigSendType" SG_ 1719 KBI_QBit_Aussen_Temp_gef 0;
BA_ "GenSigStartValue" SG_ 1719 KBI_QBit_Aussen_Temp_gef 1;
BA_ "GenSigSwitchedByIgnition" SG_ 1719 KBI_QBit_Aussen_Temp_gef 0;
BA_ "GenSigSendType" SG_ 1719 KBI_RDK_Kalibrier_Anf 3;
BA_ "GenSigSwitchedByIgnition" SG_ 1719 KBI_RDK_Kalibrier_Anf 0;
BA_ "GenSigSendType" SG_ 1719 KBI_Reserve_Warnung_Sek 3;
BA_ "GenSigSwitchedByIgnition" SG_ 1719 KBI_Reserve_Warnung_Sek 0;
BA_ "GenSigSendType" SG_ 1719 KBI_Standzeit_02 0;
BA_ "GenSigStartValue" SG_ 1719 KBI_Standzeit_02 131070;
BA_ "GenSigSwitchedByIgnition" SG_ 1719 KBI_Standzeit_02 0;
BA_ "Fehlerwert" SG_ 1719 KBI_Standzeit_02 131071;
BA_ "GenSigSendType" SG_ 2527679639 AuthTime_Trigger_Distribution 4;
BA_ "GenSigSwitchedByIgnition" SG_ 2527679639 AuthTime_Trigger_Distribution 0;
BA_ "GenSigSendType" SG_ 2527679639 KBI_Anzeige_ID_quittiert 5;
BA_ "GenSigSwitchedByIgnition" SG_ 2527679639 KBI_Anzeige_ID_quittiert 0;
BA_ "GenSigSendType" SG_ 2527679639 KBI_FoD_VirtualCockpitPlus_State 3;
BA_ "GenSigSwitchedByIgnition" SG_ 2527679639 KBI_FoD_VirtualCockpitPlus_State 0;
BA_ "GenSigSendType" SG_ 2527679639 KBI_Jokerkey 3;
BA_ "GenSigSwitchedByIgnition" SG_ 2527679639 KBI_Jokerkey 0;
BA_ "GenSigSendType" SG_ 2527679639 KBI_Min_Tankinhalt 0;
BA_ "GenSigStartValue" SG_ 2527679639 KBI_Min_Tankinhalt 126;
BA_ "GenSigSwitchedByIgnition" SG_ 2527679639 KBI_Min_Tankinhalt 0;
BA_ "Fehlerwert" SG_ 2527679639 KBI_Min_Tankinhalt 127;
BA_ "GenSigSendType" SG_ 2527679639 KBI_RS_Druck_uebernehmen 3;
BA_ "GenSigSwitchedByIgnition" SG_ 2527679639 KBI_RS_Druck_uebernehmen 0;
BA_ "GenSigSendType" SG_ 2527679639 KBI_RS_Druckauswahl_Aktiv 3;
BA_ "GenSigSwitchedByIgnition" SG_ 2527679639 KBI_RS_Druckauswahl_Aktiv 0;
BA_ "GenSigSendType" SG_ 2527679639 KBI_RS_Mode_fortsetzen 3;
BA_ "GenSigSwitchedByIgnition" SG_ 2527679639 KBI_RS_Mode_fortsetzen 0;
BA_ "GenSigSendType" SG_ 2527679639 KBI_Rundstreckenmodus 3;
BA_ "GenSigSwitchedByIgnition" SG_ 2527679639 KBI_Rundstreckenmodus 0;
BA_ "GenSigSendType" SG_ 2527679639 KBI_Weg_Zaehler 3;
BA_ "GenSigSwitchedByIgnition" SG_ 2527679639 KBI_Weg_Zaehler 0;
BA_ "GenSigSendType" SG_ 2527679639 KBI_Weg_Zaehler_F 3;
BA_ "GenSigSwitchedByIgnition" SG_ 2527679639 KBI_Weg_Zaehler_F 0;
BA_ "Fehlerwert" SG_ 2527679639 KBI_Weg_Zaehler_F 1;
BA_ "GenSigSendType" SG_ 2589283631 KBI_BC_Reset_E1 0;
BA_ "GenSigStartValue" SG_ 2589283631 KBI_BC_Reset_E1 7;
BA_ "GenSigSwitchedByIgnition" SG_ 2589283631 KBI_BC_Reset_E1 0;
BA_ "GenSigSendType" SG_ 2589283631 KBI_BC_Reset_E2 0;
BA_ "GenSigStartValue" SG_ 2589283631 KBI_BC_Reset_E2 7;
BA_ "GenSigSwitchedByIgnition" SG_ 2589283631 KBI_BC_Reset_E2 0;
BA_ "GenSigSendType" SG_ 2589283631 KBI_BC_Reset_E3 0;
BA_ "GenSigStartValue" SG_ 2589283631 KBI_BC_Reset_E3 7;
BA_ "GenSigSwitchedByIgnition" SG_ 2589283631 KBI_BC_Reset_E3 0;
BA_ "GenSigSendType" SG_ 2589283631 KBI_Kilometerstand_HiRes 0;
BA_ "GenSigSwitchedByIgnition" SG_ 2589283631 KBI_Kilometerstand_HiRes 0;
BA_ "GenSigSendType" SG_ 2589283631 KBI_Tankinhalt_roh 0;
BA_ "GenSigStartValue" SG_ 2589283631 KBI_Tankinhalt_roh 2046;
BA_ "GenSigSwitchedByIgnition" SG_ 2589283631 KBI_Tankinhalt_roh 0;
BA_ "Fehlerwert" SG_ 2589283631 KBI_Tankinhalt_roh 2047;
BA_ "GenSigFuncType" SG_ 2621440379 KS_Hybrid_01_Req_FD_Data 9;
BA_ "GenSigSwitchedByIgnition" SG_ 2621440379 KS_Hybrid_01_Req_FD_Data 0;
BA_ "GenSigFuncType" SG_ 2621571451 KS_Hybrid_01_Resp_FD_Data 9;
BA_ "GenSigSwitchedByIgnition" SG_ 2621571451 KS_Hybrid_01_Resp_FD_Data 0;
BA_ "GenSigSendType" SG_ 822 LR_HZG_Konfiguration 0;
BA_ "GenSigSwitchedByIgnition" SG_ 822 LR_HZG_Konfiguration 0;
BA_ "GenSigSendType" SG_ 822 LR_HZG_Taster_on_off 0;
BA_ "GenSigSwitchedByIgnition" SG_ 822 LR_HZG_Taster_on_off 0;
BA_ "GenSigSendType" SG_ 822 LR_HZG_Temp_Sensor 0;
BA_ "GenSigStartValue" SG_ 822 LR_HZG_Temp_Sensor 254;
BA_ "GenSigSwitchedByIgnition" SG_ 822 LR_HZG_Temp_Sensor 0;
BA_ "GenSigSendType" SG_ 2527679633 LSH_Ansaug_Fuell_1 0;
BA_ "GenSigStartValue" SG_ 2527679633 LSH_Ansaug_Fuell_1 254;
BA_ "GenSigSwitchedByIgnition" SG_ 2527679633 LSH_Ansaug_Fuell_1 0;
BA_ "Fehlerwert" SG_ 2527679633 LSH_Ansaug_Fuell_1 255;
BA_ "GenSigSendType" SG_ 2527679633 LSH_Ansaug_Fuell_2 0;
BA_ "GenSigStartValue" SG_ 2527679633 LSH_Ansaug_Fuell_2 254;
BA_ "GenSigSwitchedByIgnition" SG_ 2527679633 LSH_Ansaug_Fuell_2 0;
BA_ "Fehlerwert" SG_ 2527679633 LSH_Ansaug_Fuell_2 255;
BA_ "GenSigSendType" SG_ 2527679633 LSH_Empf_Heizstufe 0;
BA_ "GenSigSwitchedByIgnition" SG_ 2527679633 LSH_Empf_Heizstufe 0;
BA_ "Fehlerwert" SG_ 2527679633 LSH_Empf_Heizstufe 15;
BA_ "GenSigSendType" SG_ 2527679633 LSH_Funk_aus 0;
BA_ "GenSigSwitchedByIgnition" SG_ 2527679633 LSH_Funk_aus 0;
BA_ "GenSigSendType" SG_ 2527679633 LSH_Funk_ein 0;
BA_ "GenSigSwitchedByIgnition" SG_ 2527679633 LSH_Funk_ein 0;
BA_ "GenSigSendType" SG_ 2527679633 LSH_Geblaese_aktiv 0;
BA_ "GenSigSwitchedByIgnition" SG_ 2527679633 LSH_Geblaese_aktiv 0;
BA_ "GenSigSendType" SG_ 2527679633 LSH_Heiztemp 0;
BA_ "GenSigStartValue" SG_ 2527679633 LSH_Heiztemp 254;
BA_ "GenSigSwitchedByIgnition" SG_ 2527679633 LSH_Heiztemp 0;
BA_ "Fehlerwert" SG_ 2527679633 LSH_Heiztemp 255;
BA_ "GenSigSendType" SG_ 2527679633 LSH_Klappe_Status 0;
BA_ "GenSigSwitchedByIgnition" SG_ 2527679633 LSH_Klappe_Status 0;
BA_ "GenSigSendType" SG_ 2527679633 LSH_LED 0;
BA_ "GenSigSwitchedByIgnition" SG_ 2527679633 LSH_LED 0;
BA_ "GenSigSendType" SG_ 2527679633 LSH_Servicemode 0;
BA_ "GenSigSwitchedByIgnition" SG_ 2527679633 LSH_Servicemode 0;
BA_ "GenSigSendType" SG_ 2527679633 LSH_Start_folgt 0;
BA_ "GenSigSwitchedByIgnition" SG_ 2527679633 LSH_Start_folgt 0;
BA_ "GenSigSendType" SG_ 2527679633 LSH_Texte 0;
BA_ "GenSigSwitchedByIgnition" SG_ 2527679633 LSH_Texte 0;
BA_ "GenSigSendType" SG_ 2527679633 LSH_Waermeeintrag 0;
BA_ "GenSigStartValue" SG_ 2527679633 LSH_Waermeeintrag 510;
BA_ "GenSigSwitchedByIgnition" SG_ 2527679633 LSH_Waermeeintrag 0;
BA_ "Fehlerwert" SG_ 2527679633 LSH_Waermeeintrag 511;
BA_ "GenSigSendType" SG_ 2527679634 LSH_Fehlerstatus 0;
BA_ "GenSigSwitchedByIgnition" SG_ 2527679634 LSH_Fehlerstatus 0;
BA_ "GenSigSendType" SG_ 2527679634 LSH_Heizleistung 0;
BA_ "GenSigSwitchedByIgnition" SG_ 2527679634 LSH_Heizleistung 0;
BA_ "GenSigSendType" SG_ 2527679634 LSH_KL_DBetr_Anf 0;
BA_ "GenSigSwitchedByIgnition" SG_ 2527679634 LSH_KL_DBetr_Anf 0;
BA_ "GenSigSendType" SG_ 2527679634 LSH_KVS 0;
BA_ "GenSigSwitchedByIgnition" SG_ 2527679634 LSH_KVS 0;
BA_ "GenSigSendType" SG_ 2527679634 LSH_KVS_Ueberlauf 0;
BA_ "GenSigSwitchedByIgnition" SG_ 2527679634 LSH_KVS_Ueberlauf 0;
BA_ "GenSigSendType" SG_ 2527679634 LSH_Zuheizen 0;
BA_ "GenSigSwitchedByIgnition" SG_ 2527679634 LSH_Zuheizen 0;
BA_ "GenSigSendType" SG_ 1164 MF_2BatSOCzugering 0;
BA_ "GenSigSendType" SG_ 1164 MF_2BattAb 0;
BA_ "GenSigSendType" SG_ 1164 MF_2BattHlkAnf 0;
BA_ "GenSigSendType" SG_ 1164 MF_2BattLadWarn 0;
BA_ "GenSigSendType" SG_ 1164 MF_2BattLlaAnf 0;
BA_ "GenSigSendType" SG_ 1164 MF_2BattSpannungsAnf 0;
BA_ "GenSigSendType" SG_ 1164 MF_Batteriediagnose 0;
BA_ "GenSigSwitchedByIgnition" SG_ 1164 MF_Batteriediagnose 0;
BA_ "Fehlerwert" SG_ 1164 MF_Batteriediagnose 7;
BA_ "GenSigSendType" SG_ 1164 MF_Blinker_L_Sta 3;
BA_ "GenSigSwitchedByIgnition" SG_ 1164 MF_Blinker_L_Sta 0;
BA_ "GenSigSendType" SG_ 1164 MF_Blinker_R_Sta 3;
BA_ "GenSigSwitchedByIgnition" SG_ 1164 MF_Blinker_R_Sta 0;
BA_ "GenSigSendType" SG_ 1164 MF_ExterneLadungWarn 0;
BA_ "GenSigSendType" SG_ 1164 MF_Fahrerhinweis 0;
BA_ "GenSigSendType" SG_ 1164 MF_Generatordiagnose 0;
BA_ "GenSigStartValue" SG_ 1164 MF_Generatordiagnose 3;
BA_ "GenSigSwitchedByIgnition" SG_ 1164 MF_Generatordiagnose 0;
BA_ "GenSigSendType" SG_ 1164 MF_Heck_entriegeln 0;
BA_ "GenSigSendType" SG_ 1164 MF_Heck_verriegeln 0;
BA_ "GenSigSendType" SG_ 1164 MF_interm_Nebelscheinwerfer 0;
BA_ "GenSigSwitchedByIgnition" SG_ 1164 MF_interm_Nebelscheinwerfer 0;
BA_ "GenSigSendType" SG_ 1164 MF_Lampenausfall 0;
BA_ "GenSigSwitchedByIgnition" SG_ 1164 MF_Lampenausfall 0;
BA_ "GenSigSendType" SG_ 1164 MF_LSH_Abschaltstufe 0;
BA_ "GenSigSwitchedByIgnition" SG_ 1164 MF_LSH_Abschaltstufe 0;
BA_ "GenSigSendType" SG_ 1164 MF_LSH_Einschaltverbot 0;
BA_ "GenSigSwitchedByIgnition" SG_ 1164 MF_LSH_Einschaltverbot 0;
BA_ "GenSigSendType" SG_ 1164 MF_LSH_Zielzeit 0;
BA_ "GenSigStartValue" SG_ 1164 MF_LSH_Zielzeit 14;
BA_ "GenSigSwitchedByIgnition" SG_ 1164 MF_LSH_Zielzeit 0;
BA_ "Fehlerwert" SG_ 1164 MF_LSH_Zielzeit 15;
BA_ "GenSigSendType" SG_ 1164 MF_NotStartAktiv 0;
BA_ "GenSigSendType" SG_ 1164 MF_Radiomute 3;
BA_ "GenSigSwitchedByIgnition" SG_ 1164 MF_Radiomute 0;
BA_ "GenSigSendType" SG_ 1164 MF_Relais_2_Batterie 3;
BA_ "GenSigSwitchedByIgnition" SG_ 1164 MF_Relais_2_Batterie 0;
BA_ "GenSigSendType" SG_ 1164 MF_Tuerverriegelung_hinten 3;
BA_ "GenSigSwitchedByIgnition" SG_ 1164 MF_Tuerverriegelung_hinten 0;
BA_ "GenSigSendType" SG_ 1164 MF_ZV_Unlock 0;
BA_ "GenSigSwitchedByIgnition" SG_ 1164 MF_ZV_Unlock 0;
BA_ "GenSigSendType" SG_ 1164 MFG_AppConnect_Anf 4;
BA_ "GenSigSwitchedByIgnition" SG_ 1164 MFG_AppConnect_Anf 0;
BA_ "GenSigSendType" SG_ 1164 MFG_Infotainment_Autark 0;
BA_ "GenSigSwitchedByIgnition" SG_ 1164 MFG_Infotainment_Autark 0;
BA_ "GenSigSendType" SG_ 1164 MFG_Klappe_Status 0;
BA_ "GenSigSwitchedByIgnition" SG_ 1164 MFG_Klappe_Status 0;
BA_ "GenSigSendType" SG_ 1164 MFG_LSH_Ansteuerung 0;
BA_ "GenSigSwitchedByIgnition" SG_ 1164 MFG_LSH_Ansteuerung 0;
BA_ "GenSigSendType" SG_ 1164 MFG_LSH_Betriebsdauer 0;
BA_ "GenSigSwitchedByIgnition" SG_ 1164 MFG_LSH_Betriebsdauer 0;
BA_ "GenSigSendType" SG_ 1164 MFG_LSH_DBetr_Bestaet 0;
BA_ "GenSigSwitchedByIgnition" SG_ 1164 MFG_LSH_DBetr_Bestaet 0;
BA_ "GenSigSendType" SG_ 1164 MFG_LSH_DBetr_Ein 0;
BA_ "GenSigSwitchedByIgnition" SG_ 1164 MFG_LSH_DBetr_Ein 0;
BA_ "GenSigSendType" SG_ 1471 MFL_Eventcode_1 9;
BA_ "GenSigSwitchedByIgnition" SG_ 1471 MFL_Eventcode_1 0;
BA_ "GenSigSendType" SG_ 1471 MFL_Eventcode_2 9;
BA_ "GenSigSwitchedByIgnition" SG_ 1471 MFL_Eventcode_2 0;
BA_ "GenSigFuncType" SG_ 1471 MFL_Marke 8;
BA_ "GenSigSwitchedByIgnition" SG_ 1471 MFL_Marke 0;
BA_ "GenSigSendType" SG_ 1471 MFL_Tastencode_1 9;
BA_ "GenSigSwitchedByIgnition" SG_ 1471 MFL_Tastencode_1 0;
BA_ "GenSigSendType" SG_ 1471 MFL_Tastencode_2 9;
BA_ "GenSigSwitchedByIgnition" SG_ 1471 MFL_Tastencode_2 0;
BA_ "GenSigFuncType" SG_ 1471 MFL_Variante 8;
BA_ "GenSigSwitchedByIgnition" SG_ 1471 MFL_Variante 0;
BA_ "GenSigSendType" SG_ 1600 MO_Absperrventil_oeffnen 0;
BA_ "GenSigSwitchedByIgnition" SG_ 1600 MO_Absperrventil_oeffnen 0;
BA_ "GenSigSendType" SG_ 1600 MO_aktives_Getriebeheizen 0;
BA_ "GenSigSwitchedByIgnition" SG_ 1600 MO_aktives_Getriebeheizen 0;
BA_ "GenSigSendType" SG_ 1600 MO_Ansaugluft_Temp 0;
BA_ "GenSigStartValue" SG_ 1600 MO_Ansaugluft_Temp 254;
BA_ "GenSigSwitchedByIgnition" SG_ 1600 MO_Ansaugluft_Temp 0;
BA_ "Fehlerwert" SG_ 1600 MO_Ansaugluft_Temp 255;
BA_ "GenSigSendType" SG_ 1600 MO_Getriebe_kuehlen 0;
BA_ "GenSigSwitchedByIgnition" SG_ 1600 MO_Getriebe_kuehlen 0;
BA_ "GenSigSendType" SG_ 1600 MO_Heizungspumpenansteuerung 0;
BA_ "GenSigStartValue" SG_ 1600 MO_Heizungspumpenansteuerung 14;
BA_ "GenSigSwitchedByIgnition" SG_ 1600 MO_Heizungspumpenansteuerung 0;
BA_ "Fehlerwert" SG_ 1600 MO_Heizungspumpenansteuerung 13;
BA_ "GenSigSendType" SG_ 1600 MO_Hoeheninfo 0;
BA_ "GenSigSwitchedByIgnition" SG_ 1600 MO_Hoeheninfo 0;
BA_ "Fehlerwert" SG_ 1600 MO_Hoeheninfo 255;
BA_ "GenSigSendType" SG_ 1600 MO_HYB_Fehler_HV_Netz 0;
BA_ "GenSigSwitchedByIgnition" SG_ 1600 MO_HYB_Fehler_HV_Netz 0;
BA_ "GenSigSendType" SG_ 1600 MO_Kennfeldk 0;
BA_ "GenSigSwitchedByIgnition" SG_ 1600 MO_Kennfeldk 0;
BA_ "GenSigSendType" SG_ 1600 MO_KL15_Abschaltempfehlung 0;
BA_ "GenSigSwitchedByIgnition" SG_ 1600 MO_KL15_Abschaltempfehlung 0;
BA_ "GenSigSendType" SG_ 1600 MO_Kuehlmittel_Temp 0;
BA_ "GenSigStartValue" SG_ 1600 MO_Kuehlmittel_Temp 254;
BA_ "GenSigSwitchedByIgnition" SG_ 1600 MO_Kuehlmittel_Temp 0;
BA_ "Fehlerwert" SG_ 1600 MO_Kuehlmittel_Temp 255;
BA_ "GenSigSendType" SG_ 1600 MO_Mom_Traegheit_02 0;
BA_ "GenSigSwitchedByIgnition" SG_ 1600 MO_Mom_Traegheit_02 0;
BA_ "GenSigSendType" SG_ 1600 MO_Nachlaufzeit_Heizungspumpe 0;
BA_ "GenSigSwitchedByIgnition" SG_ 1600 MO_Nachlaufzeit_Heizungspumpe 0;
BA_ "GenSigSendType" SG_ 1600 MO_Oel_Temp 0;
BA_ "GenSigStartValue" SG_ 1600 MO_Oel_Temp 254;
BA_ "GenSigSwitchedByIgnition" SG_ 1600 MO_Oel_Temp 0;
BA_ "Fehlerwert" SG_ 1600 MO_Oel_Temp 255;
BA_ "GenSigSendType" SG_ 1600 MO_QBit_Ansaugluft_Temp 0;
BA_ "GenSigStartValue" SG_ 1600 MO_QBit_Ansaugluft_Temp 1;
BA_ "GenSigSwitchedByIgnition" SG_ 1600 MO_QBit_Ansaugluft_Temp 0;
BA_ "GenSigSendType" SG_ 1600 MO_QBit_Hoeheninfo 0;
BA_ "GenSigStartValue" SG_ 1600 MO_QBit_Hoeheninfo 1;
BA_ "GenSigSwitchedByIgnition" SG_ 1600 MO_QBit_Hoeheninfo 0;
BA_ "GenSigSendType" SG_ 1600 MO_QBit_Kuehlmittel_Temp 0;
BA_ "GenSigStartValue" SG_ 1600 MO_QBit_Kuehlmittel_Temp 1;
BA_ "GenSigSwitchedByIgnition" SG_ 1600 MO_QBit_Kuehlmittel_Temp 0;
BA_ "GenSigSendType" SG_ 1600 MO_QBit_Oel_Temp 0;
BA_ "GenSigStartValue" SG_ 1600 MO_QBit_Oel_Temp 1;
BA_ "GenSigSwitchedByIgnition" SG_ 1600 MO_QBit_Oel_Temp 0;
BA_ "GenSigSendType" SG_ 1600 MO_SpannungsAnf 0;
BA_ "GenSigSwitchedByIgnition" SG_ 1600 MO_SpannungsAnf 0;
BA_ "GenSigSendType" SG_ 1600 MO_Versionsinfo_02 0;
BA_ "GenSigSwitchedByIgnition" SG_ 1600 MO_Versionsinfo_02 0;
BA_REL_ "GenSigTimeoutTime" BU_SG_REL_ BMS_NV_12V SG_ 1600 MO_Hoeheninfo 5000;
BA_REL_ "GenSigTimeoutTime" BU_SG_REL_ Gateway_Max SG_ 1640 KL_LRH_Stufe 2000;
BA_REL_ "GenSigTimeoutTime" BU_SG_REL_ Gateway_Max SG_ 1640 HSH_Taster 2000;
BA_REL_ "GenSigTimeoutTime" BU_SG_REL_ Gateway_Max SG_ 1640 KL_Beschlagsgefahr 2000;
BA_REL_ "GenSigTimeoutTime" BU_SG_REL_ Gateway_Max SG_ 1640 KL_SIH_Soll_li 2000;
BA_REL_ "GenSigTimeoutTime" BU_SG_REL_ Gateway_Max SG_ 1640 KL_SIH_Soll_re 2000;
BA_REL_ "GenSigTimeoutTime" BU_SG_REL_ Gateway_Max SG_ 1640 KRH_Soll_li 2000;
BA_REL_ "GenSigTimeoutTime" BU_SG_REL_ Gateway_Max SG_ 1640 KL_SIL_Soll_li 2000;
BA_REL_ "GenSigTimeoutTime" BU_SG_REL_ Gateway_Max SG_ 1640 KL_SIL_Soll_re 2000;
BA_REL_ "GenSigTimeoutTime" BU_SG_REL_ Gateway_Max SG_ 1640 KRH_Soll_re 2000;
BA_REL_ "GenSigTimeoutTime" BU_SG_REL_ Gateway_Max SG_ 1640 KL_Geblspng_Soll 2000;
BA_REL_ "GenSigTimeoutTime" BU_SG_REL_ Gateway_Max SG_ 1640 KL_Geblspng_Fond_Soll 2000;
BA_REL_ "GenSigTimeoutTime" BU_SG_REL_ Gateway_Max SG_ 1640 KL_I_Geblaese 2000;
BA_REL_ "GenSigTimeoutTime" BU_SG_REL_ Gateway_Max SG_ 1640 KL_PTC_Verbauinfo 2000;
BA_REL_ "GenSigTimeoutTime" BU_SG_REL_ Gateway_Max SG_ 2527679635 KL_LRH_Soll 5000;
BA_REL_ "GenSigTimeoutTime" BU_SG_REL_ Gateway_Max SG_ 2527679635 KL_HSH_Soll 5000;
BA_REL_ "GenSigTimeoutTime" BU_SG_REL_ Gateway_Max SG_ 2527679635 KL_FSH_Soll 5000;
BA_REL_ "GenSigTimeoutTime" BU_SG_REL_ Gateway_Max SG_ 2527679635 KL_VoKo_LED 5000;
BA_REL_ "GenSigTimeoutTime" BU_SG_REL_ Gateway_Max SG_ 2527679635 KL_HSH_LED 5000;
BA_REL_ "GenSigTimeoutTime" BU_SG_REL_ Gateway_Max SG_ 2527679635 KL_FSH_LED 5000;
BA_REL_ "GenSigTimeoutTime" BU_SG_REL_ Gateway_Max SG_ 2463978878 KL_Verbauzustand 1000;
BA_REL_ "GenSigTimeoutTime" BU_SG_REL_ Gateway_Max SG_ 2463978878 KL_SHZ_verfuegbar 1000;
BA_REL_ "GenSigTimeoutTime" BU_SG_REL_ Gateway_Max SG_ 2463978878 KL_LRH_verfuegbar 1000;
BA_REL_ "GenSigTimeoutTime" BU_SG_REL_ Gateway_Max SG_ 2463978878 KL_ScheibenHZ_verfuegbar 1000;
BA_REL_ "GenSigTimeoutTime" BU_SG_REL_ Gateway_Max SG_ 2463978878 KL_Variante 1000;
BA_REL_ "GenSigTimeoutTime" BU_SG_REL_ Gateway_Max SG_ 2463978878 KL_Derivat 1000;
BA_REL_ "GenSigTimeoutTime" BU_SG_REL_ Gateway_Max SG_ 1511 KL_HV_Heizer_Strom 2000;
BA_REL_ "GenSigTimeoutTime" BU_SG_REL_ Gateway_Max SG_ 1511 KL_Fehler_HV_EKK 2000;
BA_REL_ "GenSigTimeoutTime" BU_SG_REL_ Gateway_Max SG_ 1511 KL_Fehler_HV_Heizer 2000;
BA_REL_ "GenSigTimeoutTime" BU_SG_REL_ Gateway_Max SG_ 1511 KL_Vorwarn_HVHeizer_Leistung 2000;
BA_REL_ "GenSigTimeoutTime" BU_SG_REL_ Gateway_Max SG_ 1514 KL_Standklima_Status_03 5000;
BA_REL_ "GenSigTimeoutTime" BU_SG_REL_ Gateway_Max SG_ 1514 KL_VK_Anf 5000;
BA_REL_ "GenSigTimeoutTime" BU_SG_REL_ Gateway_Max SG_ 1514 KL_Standklima_RemoteModus 5000;
BA_REL_ "GenSigTimeoutTime" BU_SG_REL_ Gateway_Max SG_ 1514 KBT_Defrost_aktiv 5000;
BA_REL_ "GenSigTimeoutTime" BU_SG_REL_ Gateway_Max SG_ 1514 KL_VK_Betriebsdauer 5000;
BA_REL_ "GenSigTimeoutTime" BU_SG_REL_ Gateway_Max SG_ 1514 KL_Vorkond_Strategie 5000;
BA_REL_ "GenSigTimeoutTime" BU_SG_REL_ Gateway_Max SG_ 2589283627 KL_Leistung_Klima_Anf 5000;
BA_REL_ "GenSigTimeoutTime" BU_SG_REL_ Gateway_Max SG_ 2589283627 KL_Heizen_Status 5000;
BA_REL_ "GenSigTimeoutTime" BU_SG_REL_ Gateway_Max SG_ 2589283627 Kl_Klima_Aktiv 5000;
BA_REL_ "GenSigTimeoutTime" BU_SG_REL_ Gateway_Max SG_ 2589283627 KL_Kuehlungs_Status 5000;
BA_REL_ "GenSigTimeoutTime" BU_SG_REL_ Gateway_Max SG_ 2589283627 KL_HV_Energie_Anf 5000;
BA_REL_ "GenSigTimeoutTime" BU_SG_REL_ Gateway_Max SG_ 2589283627 KL_IstLeistung 5000;
BA_REL_ "GenSigTimeoutTime" BU_SG_REL_ Gateway_Max SG_ 2463978771 KL_AQI_Innenraum 1000;
BA_REL_ "GenSigTimeoutTime" BU_SG_REL_ Gateway_Max SG_ 2527679641 KLh_SIH_Stufe_hl 5000;
BA_REL_ "GenSigTimeoutTime" BU_SG_REL_ Gateway_Max SG_ 2527679641 KLh_SIH_Stufe_hr 5000;
BA_REL_ "GenSigTimeoutTime" BU_SG_REL_ Gateway_Max SG_ 2527679641 KL_SL_Soll_hl 5000;
BA_REL_ "GenSigTimeoutTime" BU_SG_REL_ Gateway_Max SG_ 2527679641 KL_SL_Soll_hr 5000;
BA_REL_ "GenSigTimeoutTime" BU_SG_REL_ Gateway_Max SG_ 1513 DS_Kaeltemittel_P 2000;
BA_REL_ "GenSigTimeoutTime" BU_SG_REL_ Gateway_Max SG_ 2549088581 BMS_NV_Nachlauftyp 5000;
BA_REL_ "GenSigTimeoutTime" BU_SG_REL_ Gateway_Max SG_ 2549088581 KN_BMS_NV_DiagPfad 5000;
BA_REL_ "GenSigTimeoutTime" BU_SG_REL_ Gateway_Max SG_ 2549088581 BMS_NV_KD_Fehler 2500;
BA_REL_ "GenSigTimeoutTime" BU_SG_REL_ Gateway_Max SG_ 2549088326 Klima_Nachlauftyp 5000;
BA_REL_ "GenSigTimeoutTime" BU_SG_REL_ Gateway_Max SG_ 2549088326 KN_KL_DiagPfad 5000;
BA_REL_ "GenSigTimeoutTime" BU_SG_REL_ Gateway_Max SG_ 2549088326 KL_KD_Fehler 2500;
BA_REL_ "GenSigTimeoutTime" BU_SG_REL_ Klima SG_ 1712 FS_Taupunkt 5000;
BA_REL_ "GenSigTimeoutTime" BU_SG_REL_ Klima SG_ 1712 FS_ResponseError 5000;
BA_REL_ "GenSigTimeoutTime" BU_SG_REL_ Klima SG_ 1712 FS_Temp_Scheibe 5000;
BA_REL_ "GenSigTimeoutTime" BU_SG_REL_ Klima SG_ 1712 FS_Temp_Sensor 5000;
BA_REL_ "GenSigTimeoutTime" BU_SG_REL_ Klima SG_ 1712 FS_Luftfeuchte_rel 5000;
BA_REL_ "GenSigTimeoutTime" BU_SG_REL_ Klima SG_ 1505 BCM1_Aussen_Temp_ungef 2000;
BA_REL_ "GenSigTimeoutTime" BU_SG_REL_ Klima SG_ 1505 BCM1_FStatus_Aussentemp_ungef 2000;
BA_REL_ "GenSigTimeoutTime" BU_SG_REL_ Klima SG_ 1505 BCM1_OBD_FStatus_ATemp 2000;
BA_REL_ "GenSigTimeoutTime" BU_SG_REL_ Klima SG_ 779 KBI_Tankwarnung 500;
BA_REL_ "GenSigTimeoutTime" BU_SG_REL_ Klima SG_ 1719 KBI_Standzeit_02 5000;
BA_REL_ "GenSigTimeoutTime" BU_SG_REL_ Klima SG_ 1719 KBI_QBit_Aussen_Temp_gef 5000;
BA_REL_ "GenSigTimeoutTime" BU_SG_REL_ Klima SG_ 1719 KBI_Aussen_Temp_gef 5000;
BA_REL_ "GenSigTimeoutTime" BU_SG_REL_ Klima SG_ 822 LR_HZG_Temp_Sensor 1200;
BA_REL_ "GenSigTimeoutTime" BU_SG_REL_ Klima SG_ 822 LR_HZG_Konfiguration 1200;
BA_REL_ "GenSigTimeoutTime" BU_SG_REL_ Klima SG_ 2527679633 LSH_LED 2000;
BA_REL_ "GenSigTimeoutTime" BU_SG_REL_ Klima SG_ 2527679633 LSH_Servicemode 2000;
BA_REL_ "GenSigTimeoutTime" BU_SG_REL_ Klima SG_ 2527679633 LSH_Funk_aus 2000;
BA_REL_ "GenSigTimeoutTime" BU_SG_REL_ Klima SG_ 2527679633 LSH_Funk_ein 2000;
BA_REL_ "GenSigTimeoutTime" BU_SG_REL_ Klima SG_ 2527679633 LSH_Klappe_Status 2000;
BA_REL_ "GenSigTimeoutTime" BU_SG_REL_ Klima SG_ 2527679633 LSH_Start_folgt 2000;
BA_REL_ "GenSigTimeoutTime" BU_SG_REL_ Klima SG_ 2527679633 LSH_Heiztemp 2000;
BA_REL_ "GenSigTimeoutTime" BU_SG_REL_ Klima SG_ 2527679633 LSH_Empf_Heizstufe 2000;
BA_REL_ "GenSigTimeoutTime" BU_SG_REL_ Klima SG_ 2527679633 LSH_Texte 2000;
BA_REL_ "GenSigTimeoutTime" BU_SG_REL_ Klima SG_ 2527679633 LSH_Waermeeintrag 2000;
BA_REL_ "GenSigTimeoutTime" BU_SG_REL_ Klima SG_ 2527679633 LSH_Ansaug_Fuell_1 2000;
BA_REL_ "GenSigTimeoutTime" BU_SG_REL_ Klima SG_ 2527679633 LSH_Ansaug_Fuell_2 2000;
BA_REL_ "GenSigTimeoutTime" BU_SG_REL_ Klima SG_ 2527679634 LSH_Zuheizen 2000;
BA_REL_ "GenSigTimeoutTime" BU_SG_REL_ Klima SG_ 2527679634 LSH_KL_DBetr_Anf 2000;
BA_REL_ "GenSigTimeoutTime" BU_SG_REL_ Klima SG_ 2527679634 LSH_Fehlerstatus 2000;
BA_REL_ "GenSigTimeoutTime" BU_SG_REL_ Klima SG_ 2527679634 LSH_Heizleistung 2000;
BA_REL_ "GenSigTimeoutTime" BU_SG_REL_ Klima SG_ 1164 MF_LSH_Zielzeit 2000;
BA_REL_ "GenSigTimeoutTime" BU_SG_REL_ Klima SG_ 1164 MF_LSH_Abschaltstufe 2000;
BA_REL_ "GenSigTimeoutTime" BU_SG_REL_ Klima SG_ 1164 MF_LSH_Einschaltverbot 2000;
BA_REL_ "GenSigTimeoutTime" BU_SG_REL_ Klima SG_ 1471 MFL_Tastencode_1 5000;
BA_REL_ "GenSigTimeoutTime" BU_SG_REL_ Klima SG_ 1471 MFL_Tastencode_2 5000;
BA_REL_ "GenSigTimeoutTime" BU_SG_REL_ Klima SG_ 1471 MFL_Eventcode_1 5000;
BA_REL_ "GenSigTimeoutTime" BU_SG_REL_ Klima SG_ 1471 MFL_Eventcode_2 5000;
BA_REL_ "GenSigTimeoutTime" BU_SG_REL_ Klima SG_ 1471 MFL_Variante 5000;
BA_REL_ "GenSigTimeoutTime" BU_SG_REL_ Klima SG_ 1600 MO_Absperrventil_oeffnen 5000;
BA_REL_ "GenSigTimeoutTime" BU_SG_REL_ Klima SG_ 1600 MO_Kuehlmittel_Temp 5000;
BA_REL_ "GenSigTimeoutTime" BU_SG_REL_ Klima SG_ 1600 MO_Hoeheninfo 5000;
BA_REL_ "GenSigTimeoutTime" BU_SG_REL_ Klima SG_ 1600 MO_Kennfeldk 5000;
BA_REL_ "GenSigTimeoutTime" BU_SG_REL_ Klima SG_ 1600 MO_Getriebe_kuehlen 5000;
BA_REL_ "GenSigTimeoutTime" BU_SG_REL_ Klima SG_ 1600 MO_Heizungspumpenansteuerung 5000;
VAL_ 1640 KL_LRH_Taster 0 "nicht_betaetigt" 1 "betaetigt" ;
VAL_ 1640 KL_LRH_Stufe 0 "Stufe_niedrig" 1 "Stufe_mittel" 2 "Stufe_hoch" 3 "AUS" ;
VAL_ 1640 HSH_Taster 0 "nicht_betaetigt" 1 "short_push" 2 "long_push" 3 "tbd" ;
VAL_ 1640 FSH_Taster 0 "nicht_betaetigt" 1 "betaetigt" ;
VAL_ 1640 KL_Zuheizer_Freigabe 0 "keine_Freigabe_Zuheizer" 1 "Zuheizerfreigabe" ;
VAL_ 1640 KL_Beschlagsgefahr 0 "keine_Beschlagsgefahr" 1 "Beschlagsgefahr" ;
VAL_ 1640 KRH_Soll_li 0 "aus" 1 "Stufe_1" 2 "Stufe_2" 3 "Stufe_3" ;
VAL_ 1640 KRH_Soll_re 0 "aus" 1 "Stufe_1" 2 "Stufe_2" 3 "Stufe_3" ;
VAL_ 1640 KL_Geblspng_Soll 0 "0V_Motorspannung" 252 "0V_sofort_Abschalten" 253 "0V_senken_mit_Rampe" 254 "reserviert" 255 "Fehler" ;
VAL_ 1640 KL_Geblspng_Fond_Soll 0 "0V_Motorspannung" 252 "0V_sofort_Abschalten" 253 "0V_senken_mit_Rampe" 254 "reserviert" 255 "Fehler" ;
VAL_ 1640 KL_I_Geblaese 255 "Fehler" ;
VAL_ 1640 KL_Kompressorstrom_soll 1022 "Init" 1023 "Fehler" ;
VAL_ 1640 KL_Umluftklappe_Status 0 "Frischluft" 1 "Teilumluft_10" 2 "Teilumluft_20" 3 "Teilumluft_30" 4 "Teilumluft_40" 5 "Teilumluft_50" 6 "Teilumluft_60" 7 "Teilumluft_70" 8 "Teilumluft_80" 9 "Teilumluft_90" 10 "Umluft" 14 "Init" 15 "Fehler" ;
VAL_ 1640 KL_PTC_Verbauinfo 0 "kein_PTC" 1 "600W_geschaltet" 2 "1000W_geschaltet" 3 "1400W_LIN" ;
VAL_ 2527679635 KL_Voko_Status 0 "aus" 1 "ein" 14 "Init" 15 "Fehler" ;
VAL_ 2527679635 KL_LRH_Soll 0 "nicht_angefordert" 1 "angefordert" ;
VAL_ 2527679635 KL_AL_VR_Anf 0 "Init" 1 "waermer" 2 "kaelter" ;
VAL_ 2527679635 KL_AL_VL_Anf 0 "Init" 1 "waermer" 2 "kaelter" ;
VAL_ 2527679635 KL_AL_HR_Anf 0 "Init" 1 "waermer" 2 "kaelter" ;
VAL_ 2527679635 KL_AL_HL_Anf 0 "Init" 1 "waermer" 2 "kaelter" ;
VAL_ 2527679635 KL_HSH_Soll 0 "nicht_angefordert" 1 "angefordert" ;
VAL_ 2527679635 KL_FSH_Soll 0 "nicht_angefordert" 1 "angefordert" ;
VAL_ 2527679635 KL_ZR_Anforderung 0 "init" 1 "inaktiv" 2 "aktiv" 3 "reserviert" ;
VAL_ 2527679635 KL_VoKo_LED 0 "Aus" 1 "Ein" ;
VAL_ 2527679635 KL_Defrost_LED 0 "Aus" 1 "Ein" ;
VAL_ 2527679635 KL_HSH_LED 0 "Aus" 1 "Ein" ;
VAL_ 2527679635 HSH_Relais_Anf 0 "nicht_angefordert" 1 "angefordert" ;
VAL_ 2527679635 FSH_Status 0 "aus" 1 "ein" 2 "tbd" 3 "Fehler" ;
VAL_ 2527679635 SIH_Stufe_LED_li 0 "Aus" 2 "Stufe_2" 4 "Stufe_4" 6 "Stufe_6" ;
VAL_ 2527679635 SIH_Stufe_LED_re 0 "Aus" 2 "Stufe_2" 4 "Stufe_4" 6 "Stufe_6" ;
VAL_ 2527679635 KL_FSH_LED 0 "Aus" 1 "Ein" ;
VAL_ 2527679635 KL_HUP_aktiv 0 "Aus" 1 "Ein" ;
VAL_ 2527679635 KL_LSH_DBetr_Ein 0 "Dauerbetrieb_nicht_gefordert" 1 "Dauerbetrieb_gefordert" ;
VAL_ 2527679635 KL_LSH_DBetr_Bestaet 0 "kein_Dauerbetrieb" 1 "Dauerbetrieb_bestaetigt" ;
VAL_ 2527679635 KL_Klappe_Status 0 "Init" 1 "Front" 2 "Heck" 3 "Front_u_Heck" 4 "misch_Front_u_Heck" ;
VAL_ 2527679635 KL_LSH_Ansteuerung 0 "Aus" 1 "Ein" 2 "Kombi_Betrieb" 3 "Heizleistung_reduziert" ;
VAL_ 2527679635 KL_Heizstufe_LSH 0 "Init" 1 "Stufe_1" 2 "Stufe_2" 3 "Stufe_3" 4 "Stufe_4" 5 "Stufe_5" 6 "Stufe_6" 7 "Stufe_7" 8 "Stufe_8" 9 "Stufe_9" 10 "Stufe_10" 15 "Fehler" ;
VAL_ 2527679635 KL_LSH_Betriebsdauer 127 "Dauerbetrieb" ;
VAL_ 2527679635 KL_Temp_ZH_Soll 0 "Funk_nicht_verbaut_nicht_aktiv" 255 "Fehler" ;
VAL_ 2589284015 KL_LRH_FoD_Status 0 "init" 1 "Funktion_inaktiv" 2 "Funktion_aktiv" ;
VAL_ 2463978878 KL_Verbauzustand 0 "Init" 1 "Fehler" 2 "Standheizung_verbaut" 3 "Standheizung_nicht_verbaut" ;
VAL_ 2463978878 KL_SHZ_verfuegbar 0 "keine_SHZ_verbaut" 1 "SHZ_Front_verbaut" 2 "SHZ_Front_Fond_verbaut" 3 "SHZ_Front_Fond_hinten_verbaut" ;
VAL_ 2463978878 KL_LRH_verfuegbar 0 "Init" 1 "Fehler" 2 "Lenkradheizung_verbaut" 3 "Lenkradheizung_nicht_verbaut" ;
VAL_ 2463978878 KL_ScheibenHZ_verfuegbar 0 "Init" 1 "Fehler" 2 "ScheibenHZ_Front_verbaut" 3 "ScheibenHZ_Fond_verbaut" 4 "ScheibenHZ_FrontFond_verbaut" 5 "ScheibenHZ_nicht_verbaut" ;
VAL_ 2463978878 KL_Variante 0 "Init" 1 "Fehler" 2 "KME_ICE" 3 "KME_BEV" 4 "KME_PHEV" 5 "CLT_ICE" 6 "CLT_BEV" 7 "CLT_PHEV" ;
VAL_ 2463978878 KL_Derivat 0 "Init" 1 "Fehler" 2 "Volkswagen" 3 "Volkswagen_Nutzfahrzeug" 4 "Audi" 5 "Seat" 6 "Skoda" ;
VAL_ 1511 KL_HV_Heizer_Strom 255 "Init" ;
VAL_ 1511 KL_EKK_Strom 255 "Init" ;
VAL_ 1511 KL_Pumpe_02_Soll 126 "Init" 127 "Fehler" ;
VAL_ 1511 KL_Ventil_03_Soll 0 "nicht_ansteuern" 1 "Ventil_ansteuern" ;
VAL_ 1511 KL_Ventil_10_Status 0 "Ventil_nicht_angesteuert" 1 "Ventil_angesteuert" 2 "reserviert" 3 "reserviert" 4 "reserviert" 5 "Ventil_nicht_verbaut" 6 "Init" 7 "Fehler" ;
VAL_ 1511 KL_Senderkennung 0 "Sender Climatronic SG" 1 "Sender Waermepumpen SG" ;
VAL_ 1511 WP_KJ_Soll 0 "Init_Keine_Anforderung" 1 "KJ_oeffnen" 2 "KJ_schliessen" 3 "Fehler" ;
VAL_ 1511 KL_Fehler_HV_EKK 0 "Init" 1 "Kein HV Fehler am EKK erkannt" 2 "HV Fehler am EKK erkannt" 3 "Fehler" ;
VAL_ 1511 KL_Fehler_HV_Heizer 0 "Init" 1 "Kein HV Fehler am HV Heizer erkannt" 2 "HV Fehler am HV Heizer erkannt" 3 "Fehler" ;
VAL_ 1511 KL_BattKond_WaPu_DZMax 62 "Init" 63 "Fehler" ;
VAL_ 1511 WP_Kuehlerluefter_Anf 255 "Fehler" ;
VAL_ 1511 KL_KM_ASV_01_Status 0 "Ventil nicht geschaltet" 1 "Ventil geschaltet" 2 "Ventil nicht verbaut" 3 "Fehler" ;
VAL_ 1511 KL_KM_ASV_02_Status 0 "Ventil nicht geschaltet" 1 "Ventil geschaltet" 2 "Ventil nicht verbaut" 3 "Fehler" ;
VAL_ 1511 KL_Vorwarn_HVHeizer_Leistung 0 "Init_Aus" 1 "500W" 2 "1000W" 3 "1500W" 4 "2000W" 5 "2500W" 6 "3000W" 7 "3500W" 8 "4000W" 9 "4500W" 10 "5000W" 11 "5500W" 12 "6000W" 13 "6500W" 14 "7000W" 15 "Fehler" ;
VAL_ 1511 KL_Status_EoHVL_EKK 0 "Init" 1 "Keine_offene_HV_Leitung_erkannt" 2 "offene_HV_Leitung_erkannt" 3 "Fehler" ;
VAL_ 1511 KL_Status_EoHVL_Heizer 0 "Init" 1 "Keine_offene_HV_Leitung_erkannt" 2 "offene_HV_Leitung_erkannt" 3 "Fehler" ;
VAL_ 1511 KL_Status_EoHVL_EKK_2 0 "Init" 1 "Keine_offene_HV_Leitung_erkannt" 2 "offene_HV_Leitung_erkannt" 3 "Fehler" ;
VAL_ 1511 KL_Status_EoHVL_Heizer_2 0 "Init" 1 "Keine_offene_HV_Leitung_erkannt" 2 "offene_HV_Leitung_erkannt" 3 "Fehler" ;
VAL_ 1514 KL_Standklima_Status_03 0 "nicht_aktiv" 1 "aktiv" 2 "eingeschraenkt_aktiv" 3 "Systemfehler" 4 "nicht_moeglich" 5 "keine_Freigabe" 6 "Init" 7 "Fehler" ;
VAL_ 1514 KL_Kundenwunsch_Kuehlen 0 "Keine_Kuehlung_gewuenscht" 1 "Kuehlung_gewuenscht" ;
VAL_ 1514 KL_OBD_Status 0 "MILaus" 1 "MILan" ;
VAL_ 1514 KL_KLE_Fehler_Anf 0 "inaktiv" 1 "aktiv" ;
VAL_ 1514 KL_Fehler_NTKreis 0 "KeinFehler" 1 "Fehler" ;
VAL_ 1514 KL_VK_Anf 0 "keine_Startanf_von_Climatronic" 1 "Startanf_via_FFB" 2 "Startanf_via_Sofortheiztaste" 3 "VK_Strategie_STH" 4 "Startanf_via_ZV_FFB" 5 "VK_Abbruch" 6 "Init" 7 "Fehler" ;
VAL_ 1514 KL_Standklima_Status_02 0 "nicht_aktiv" 1 "aktiv" 2 "eingeschraenkt_aktiv" 3 "Abbruch_durch_Benutzer" 4 "nicht_moeglich" 5 "Aussenhuelle_offen" 6 "Init" 7 "Fehler" ;
VAL_ 1514 KL_Standklima_RemoteModus 0 "Init__nicht_aktiv" 1 "Lueften" 2 "Kuehlen" 3 "Heizen" 4 "reserviert" 5 "reserviert" 6 "reserviert" 7 "reserviert" ;
VAL_ 1514 KBT_Defrost_aktiv 0 "inaktiv" 1 "aktiv" ;
VAL_ 1514 KL_VK_Betriebsdauer 62 "Init" 63 "Fehler" ;
VAL_ 1514 KL_Heizbedarf 0 "Kein_Heizbedarf" 1022 "Init" 1023 "Fehler" ;
VAL_ 1514 KL_Innentemp_KBT_Sensor 1022 "Init" 1023 "Fehler" ;
VAL_ 1514 KL_Vorkond_Strategie 0 "Aus" 1 "Spülen" 2 "Kanalkühlung" 3 "Kühlwasserzirkulation" 4 "Aktive Kühlung" 5 "Heizen" 6 "Reheat" 7 "Heizen_elektrisch" 8 "Heizen_verbrennungstechnisch" 13 "Strategie_nicht_berechnet" 14 "Konditionierung_nicht_moeglich" 15 "Init" ;
VAL_ 1515 KL_Abl_Soll_li 254 "Init" 255 "Fehler" ;
VAL_ 1515 KL_Abl_Soll_re 254 "Init" 255 "Fehler" ;
VAL_ 1515 KL_Verdampfer_Soll 254 "Init" 255 "Fehler" ;
VAL_ 1515 KL_Abl_Ist_li 1022 "Init" 1023 "Fehler" ;
VAL_ 1515 KL_Abl_Ist_re 1022 "Init" 1023 "Fehler" ;
VAL_ 1515 KL_TaupEps_Korr 1022 "Init" 1023 "Fehler" ;
VAL_ 2589283627 KL_HVH_1_VerbautStatus 0 "nicht_verbaut" 1 "verbaut" ;
VAL_ 2589283627 KL_EKK_1_VerbautStatus 0 "nicht_verbaut" 1 "verbaut" ;
VAL_ 2589283627 KL_Texte 0 "keine_Anzeige" 1 "Heizleistung_zu_gering" 2 "Kuehlleistung_zu_gering" 3 "Text_3" ;
VAL_ 2589283627 KL_HVH_2_VerbautStatus 0 "nicht_verbaut" 1 "verbaut" ;
VAL_ 2589283627 KL_EKK_2_VerbautStatus 0 "nicht_verbaut" 1 "verbaut" ;
VAL_ 2589283627 KL_Leistung_Klima_Anf 254 "Init" ;
VAL_ 2589283627 KL_Heizen_Status 0 "Keine_Heizleistung_Anfgefordert" 1 "Max_Defrost" 2 "Kaltstart" 3 "Eingeschwungen_hohe_Last" 4 "Eingeschwungen_niedrige_Last" 14 "Init" 15 "Fehler" ;
VAL_ 2589283627 KL_K_Status 0 "Init" 1 "Lueften" 2 "Kuehlen_Innenraum" 3 "Kuehlen_Chiller" 4 "Kuehlen_kombiniert" 5 "Heizen_Luft_WP" 6 "Heizen_kombiniert_WP" 7 "Kuehlen_Innenraum_mit_HGK" 8 "Kuehlen_kombiniert_mit_HGK" 9 "Heizen_Wasser_WP" 10 "Shutdown" 11 "Enteisen" 14 "Fehler" ;
VAL_ 2589283627 KL_Status_Battkuehlung 0 "Init" 1 "Keine_Kuehlanforderung" 2 "Kuehlung_in_Ordnung" 3 "Kuehlung_temporaer_nicht_aktiv" 4 "Kuehlung_inaktiv_fuer_Komfort" 5 "Kuehlung_nicht_moeglich" ;
VAL_ 2589283627 Kl_Klima_Aktiv 0 "Nicht_aktiv_oder_Init" 1 "Klima_aktiv" ;
VAL_ 2589283627 KL_Kuehlungs_Status 0 "Klimatisierung_ausgeschaltet" 1 "Pulldown" 2 "Eingeschwungen_hohe_Last" 3 "Eingeschwungen_niedrige_Last" 4 "Eingeschwungen_mit_Drehzahlbegre" 5 "BattK_nicht_moeglich" 6 "BattK_temporaer_nicht_moeglich" 14 "Init" 15 "Fehler" ;
VAL_ 2589283627 KL_HV_Energie_Anf 253 "nicht_berechnet" 254 "Init" 255 "Fehler" ;
VAL_ 2589283627 TME_HVEM_HV_Anf 0 "INIT" 1 "HV_Netz_nicht_angefordert" 2 "HV_Netz_angefordert" 3 "Fehler" ;
VAL_ 2589283627 KL_IstLeistung 254 "Init" 255 "Fehler" ;
VAL_ 2589283627 KL_Temp_Kundenwunsch 0 "Init" 1 "LO" 30 "HI" 63 "Fehler" ;
VAL_ 2463978771 KL_EKK_2_Status_Spgfreiheit 0 "Init" 1 "Komponente_spannungsfrei" 2 "Kompomente_nicht_spannungsfrei" 3 "Fehler" ;
VAL_ 2463978771 KL_HVH_2_Status_Spgfreiheit 0 "Init" 1 "Komponente_spannungsfrei" 2 "Kompomente_nicht_spannungsfrei" 3 "Fehler" ;
VAL_ 2463978771 KL_EKK_Status_Spgfreiheit 0 "Init" 1 "Komponente_spannungsfrei" 2 "Kompomente_nicht_spannungsfrei" 3 "Fehler" ;
VAL_ 2463978771 KL_eTM_SollVolumenstrom 127 "Init" ;
VAL_ 2463978771 KL_AQI_Innenraum 0 "Saubere_Luft" 1 "Luftverschmutzung_10_Prozent" 2 "Luftverschmutzung_20_Prozent" 3 "Luftverschmutzung_30_Prozent" 4 "Luftverschmutzung_40_Prozent" 5 "Luftverschmutzung_50_Prozent" 6 "Luftverschmutzung_60_Prozent" 7 "Luftverschmutzung_70_Prozent" 8 "Luftverschmutzung_80_Prozent" 9 "Luftverschmutzung_90_Prozent" 10 "Luftverschmutzung_100_Prozent" 14 "Init" 15 "Fehler" ;
VAL_ 2589283574 KL_OBD_Status_Auth 0 "MILaus" 1 "MILan" ;
VAL_ 2589283574 OBDProtocol_Klima 0 "OBDonUDS" 1 "OBDclassic" 16 "NoOBD" 254 "Init" 255 "Fehler" ;
VAL_ 2527679641 KLh_SIH_Stufe_hl 0 "Stufe_0" 1 "Stufe_1" 2 "Stufe_2" 3 "Stufe_3" 4 "Stufe_4" 5 "Stufe_5" 6 "Stufe_6" ;
VAL_ 2527679641 KLh_SIH_Stufe_hr 0 "Stufe_0" 1 "Stufe_1" 2 "Stufe_2" 3 "Stufe_3" 4 "Stufe_4" 5 "Stufe_5" 6 "Stufe_6" ;
VAL_ 2527679641 KLhs_02_alt 0 "aktuell" 1 "veraltet" ;
VAL_ 2589283728 KL_SDA_Sonderfunktionen_Sprache 0 "Befehl_1" 1 "Befehl_2" 2 "Befehl_3" 3 "Befehl_4" 4 "Befehl_5" 5 "Befehl_6" 6 "Befehl_7" 7 "Befehl_8" 8 "Befehl_9" 9 "Befehl_10" 10 "Befehl_11" 11 "Befehl_12" 12 "Befehl_13" 13 "Befehl_14" 14 "Befehl_15" 15 "Befehl_16" 16 "Befehl_17" 17 "Befehl_18" 18 "Befehl_19" 19 "Befehl_20" 20 "Befehl_21" 21 "Befehl_22" 22 "Befehl_23" 23 "Befehl_24" 24 "Befehl_25" 25 "Befehl_26" 26 "Befehl_27" 27 "Befehl_28" 28 "Befehl_29" 29 "Befehl_30" 30 "Init" 31 "Fehler" ;
VAL_ 2589283728 KL_SDA_Menutaste 0 "nicht_aktiv" 1 "aktiv" ;
VAL_ 2589283728 KL_SDA_Luft_Qualitaet 0 "Level0" 1 "Level1" 2 "Level2" 3 "Level3" 4 "Level4" 5 "Level5" 6 "Level6" 7 "Level7" 8 "Level8" 9 "Level9" 10 "Level10" 13 "nicht_verbaut" 14 "Init" 15 "Fehler" ;
VAL_ 2589283728 KL_SDA_Luft_Feinstaub 254 "Init" 255 "Fehler" ;
VAL_ 2589283728 KL_SDA_AQS_VOZBereich 0 "Messbereich_0" 1 "Messbereich_1" 2 "Messbereich_2" 3 "Messbereich_3" ;
VAL_ 2589283728 KL_SDA_AQS_Traffic 0 "unbekannt" 1 "City_Mode" 2 "Country_Mode" 3 "Highway_Mode" ;
VAL_ 2589283728 KL_SDA_AQS_NoxBereich 0 "Messbereich_0" 1 "Messbereich_1" 2 "Messbereich_2" 3 "Messbereich_3" ;
VAL_ 2589283728 KL_SDA_AQS_COBereich 0 "Messbereich_0" 1 "Messbereich_1" 2 "Messbereich_2" 3 "Messbereich_3" ;
VAL_ 2589283728 KL_SDA_AQS_COStatus 0 "nicht_aktiv" 1 "Luftguetestufe_1" 2 "Luftguetestufe_2" 3 "Luftguetestufe_3" 4 "Luftguetestufe_4" 5 "Luftguetestufe_5" 6 "Luftguetestufe_6" 7 "Luftguetestufe_7" 8 "Luftguetestufe_8" 9 "Luftguetestufe_9" 10 "Luftguetestufe_10" 15 "Fehler" ;
VAL_ 2589283728 KL_SDA_AQS_NoxStatus 0 "nicht_aktiv" 1 "Luftguetestufe_1" 2 "Luftguetestufe_2" 3 "Luftguetestufe_3" 4 "Luftguetestufe_4" 5 "Luftguetestufe_5" 6 "Luftguetestufe_6" 7 "Luftguetestufe_7" 8 "Luftguetestufe_8" 9 "Luftguetestufe_9" 10 "Luftguetestufe_10" 15 "Fehler" ;
VAL_ 2589283728 KL_SDA_AQS_VOZStatus 0 "nicht_aktiv" 1 "Luftguetestufe_1" 2 "Luftguetestufe_2" 3 "Luftguetestufe_3" 4 "Luftguetestufe_4" 5 "Luftguetestufe_5" 6 "Luftguetestufe_6" 7 "Luftguetestufe_7" 8 "Luftguetestufe_8" 9 "Luftguetestufe_9" 10 "Luftguetestufe_10" 15 "Fehler" ;
VAL_ 2589283728 KL_SDA_Klima_Automatik 0 "nicht_aktiv" 1 "aktiv" ;
VAL_ 2589283728 KL_SDA_Luftverteilung_Person 0 "nicht_aktiv" 1 "aktiv" ;
VAL_ 2589283728 KL_SDA_Luftverteilung_Scheibe 0 "nicht_aktiv" 1 "aktiv" ;
VAL_ 2589283728 KL_SDA_Luftverteilung_Unten 0 "nicht_aktiv" 1 "aktiv" ;
VAL_ 2589283728 KL_SDA_Sitzheizung_VL 0 "nicht_aktiv" 1 "Stufe_1" 2 "Stufe_2" 3 "Stufe_3" ;
VAL_ 2589283728 KL_SDA_Sitzheizung_VR 0 "nicht_aktiv" 1 "Stufe_1" 2 "Stufe_2" 3 "Stufe_3" ;
VAL_ 2589283728 KL_SDA_Sitzlueftung_VL 0 "nicht_aktiv" 1 "Stufe_1" 2 "Stufe_2" 3 "Stufe_3" ;
VAL_ 2589283728 KL_SDA_Sitzlueftung_VR 0 "nicht_aktiv" 1 "Stufe_1" 2 "Stufe_2" 3 "Stufe_3" ;
VAL_ 2589283728 KL_SDA_Sonderfkt_AirCare 0 "nicht_aktiv" 1 "aktiv" ;
VAL_ 2589283728 KL_SDA_Sonderfkt_HSH 0 "nicht_aktiv" 1 "aktiv" ;
VAL_ 2589283728 KL_SDA_Sonderfkt_MaxAC 0 "nicht_aktiv" 1 "aktiv" ;
VAL_ 2589283728 KL_SDA_Sonderfkt_MaxDefrost 0 "nicht_aktiv" 1 "aktiv" ;
VAL_ 2589283728 KL_SDA_Temp_Kundenwunsch_2 0 "Min" 1 "Stufe_1" 2 "Stufe_2" 3 "Stufe_3" 4 "Stufe_4" 5 "Stufe_5" 6 "Stufe_6" 7 "Stufe_7" 8 "Stufe_8" 9 "Stufe_9" 10 "Stufe_10" 11 "Stufe_11" 12 "Stufe_12" 13 "Stufe_13" 14 "Stufe_14" 15 "Stufe_15" 16 "Stufe_16" 17 "Stufe_17" 18 "Stufe_18" 19 "Stufe_19" 20 "Stufe_20" 21 "Stufe_21" 22 "Stufe_22" 23 "Stufe_23" 24 "Stufe_24" 25 "Stufe_25" 26 "Stufe_26" 27 "Stufe_27" 28 "Stufe_28" 29 "Stufe_29" 30 "Stufe_30" 31 "Max" ;
VAL_ 2589283728 KL_SDA_Temp_Kundenwunsch_3 0 "Min" 1 "Stufe_1" 2 "Stufe_2" 3 "Stufe_3" 4 "Stufe_4" 5 "Stufe_5" 6 "Stufe_6" 7 "Stufe_7" 8 "Stufe_8" 9 "Stufe_9" 10 "Stufe_10" 11 "Stufe_11" 12 "Stufe_12" 13 "Stufe_13" 14 "Stufe_14" 15 "Stufe_15" 16 "Stufe_16" 17 "Stufe_17" 18 "Stufe_18" 19 "Stufe_19" 20 "Stufe_20" 21 "Stufe_21" 22 "Stufe_22" 23 "Stufe_23" 24 "Stufe_24" 25 "Stufe_25" 26 "Stufe_26" 27 "Stufe_27" 28 "Stufe_28" 29 "Stufe_29" 30 "Stufe_30" 31 "Max" ;
VAL_ 1712 FS_Taupunkt 0 "nicht verfuegbar" 1023 "Fehler" ;
VAL_ 1712 FS_ResponseError 0 "normal" 1 "Fehler" ;
VAL_ 1712 FS_Temp_Scheibe 0 "nicht verfuegbar" 1023 "Fehler" ;
VAL_ 1712 FS_Temp_Sensor 0 "nicht verfuegbar" 255 "Fehler" ;
VAL_ 1712 FS_Luftfeuchte_rel 0 "nicht verfuegbar" 255 "Fehler" ;
VAL_ 1505 BCM1_Aussen_Temp_ungef 253 "nicht_verbaut" 254 "Initwert" 255 "Fehler" ;
VAL_ 1505 BCM_Heizungsabsperrventil_Status 0 "HAV_offen" 1 "HAV_geschlossen" 2 "Init_oder_nicht_verbaut" 3 "Fehler" ;
VAL_ 1505 BCM_Heizungspumpe_Status 0 "Pumpe_aus" 1 "Pumpe_aktiv_und_Stauts_iO" 2 "Init_oder_nicht_verbaut" 3 "Fehler" ;
VAL_ 1505 BCM_Kompressorkupplung_Status 0 "Kupplung_offen" 1 "Kupplung_geschlossen" 2 "Init_oder_nicht_verbaut" 3 "Fehler" ;
VAL_ 1505 BCM1_PTC_stufig_Status 0 "Aus" 1 "Stufe_1_aktiv" 2 "Stufe_2_aktiv" 3 "Stufe_3_aktiv" 6 "Init_oder_nicht_verbaut" 7 "Fehler" ;
VAL_ 1505 BCM1_FStatus_Aussentemp_ungef 0 "iO" 1 "niO" ;
VAL_ 1505 BCM1_Kompressorstrom_ist 254 "Init, bzw. nicht verfuegbar" 255 "Fehler" ;
VAL_ 1505 BCM1_OBD_FStatus_ATemp 0 "kein Fehler / Init / nicht verbaut" 1 "KS- (Kurzschluss nach minus)" 2 "KS+ (Kurzschluss nach plus)" 3 "OC (Leitungsunterbrechung)" 4 "OOR+ (Signal zu gross)" 5 "OOR- (Signal zu klein)" 6 "RC+ (Signal unplausibel zu gross)" 7 "RC- (Signal unplausibel zu klein)" 8 "KS+/OC (Kurzschluss nach plus/Unterbrechung)" 9 "KS-/OC  (Kurzschluss nach minus/Unterbrechung)" 10 "KS-/KS+  (Kurzschluss nach minus/plus)" 11 "KS-/KS+/OC (Kurzschluss nach minus/plus/Unterbrechung)" 12 "frei" 13 "frei" 14 "frei" 15 "frei" ;
VAL_ 1717 FSA_Taupunkt 1021 "nicht_verbaut" 1022 "Init" 1023 "Fehler" ;
VAL_ 1717 FSA_Err_Defekt_Tsens_TF 0 "inaktiv" 1 "aktiv" ;
VAL_ 1717 FSA_Luftfeuchte_TNCTOC 0 "Test_Completed_TOC" 1 "Test_Not_Completed_TOC" ;
VAL_ 1717 FSA_Luftfeuchte_TF 0 "inaktiv" 1 "aktiv" ;
VAL_ 1717 FSA_Err_Unterspannung_TF 0 "inaktiv" 1 "aktiv" ;
VAL_ 1717 FSA_Err_RAMROM_Check_TF 0 "inaktiv" 1 "aktiv" ;
VAL_ 1717 FSA_ResponseError 0 "normal" 1 "Fehler" ;
VAL_ 1717 FSA_Temp_Luft 1021 "nicht_verbaut" 1022 "Init" 1023 "Fehler" ;
VAL_ 1717 FSA_Err_RAMROM_Check_TNCTOC 0 "Test_Completed_TOC" 1 "Test_Not_Completed_TOC" ;
VAL_ 1717 FSA_Err_Ueberspannung_TF 0 "inaktiv" 1 "aktiv" ;
VAL_ 1717 FSA_Luftfeuchte_rel 253 "nicht_verbaut" 254 "Init" 255 "Fehler" ;
VAL_ 1717 FSA_Temp_Sensor 2045 "nicht_verbaut" 2046 "Init" 2047 "Fehler" ;
VAL_ 1717 FSA_Sensorheizung_Status 0 "inaktiv" 1 "aktiv" ;
VAL_ 1717 FSA_Err_Defekt_HumSense_TF 0 "inaktiv" 1 "aktiv" ;
VAL_ 1717 FSA_Err_Defekt_HumSens_TNCTOC 0 "Test_Completed_TOC" 1 "Test_Not_Completed_TOC" ;
VAL_ 1717 FSA_ErrMemState 0 "Init_Default" 1 "ErrMem_Active_State" 2 "ErrMem_InitProgress" 3 "ErrMem_Init_done" ;
VAL_ 1513 DS_Kaeltemittel_P 2046 "Init" 2047 "Fehler" ;
VAL_ 1513 DS_Status 0 "i.O." 1 "t.b.d." 2 "Init bzw. nicht verfügbar" 3 "Fehler" ;
VAL_ 1513 ION_Status 0 "Hochspannung_ausgeschaltet" 1 "Hochspannung_eingeschaltet" 2 "Init" ;
VAL_ 1513 ION_Status_LED 0 "Aus" 1 "Ein" ;
VAL_ 1513 AAU_Geblaese 126 "Init" 127 "Fehler" ;
VAL_ 1513 ION_Status_Taster 0 "nicht_betaetigt" 1 "betaetigt" ;
VAL_ 1513 DS_Kaeltemittel_P_WP 2046 "Init" 2047 "Fehler" ;
VAL_ 2549088581 BMS_NV_KompSchutz 0 "KS_nicht_aktiv" 1 "KS_aktiv" ;
VAL_ 2549088581 BMS_NV_Abschaltstufe 0 "keine_Einschraenkung" 1 "Funktionseinschraenkung" ;
VAL_ 2549088581 BMS_NV_Transport_Mode 0 "keine_Einschraenkung" 1 "Funktionseinschraenkung" ;
VAL_ 2549088581 BMS_NV_Nachlauftyp 0 "Komm_bei_KL15_EIN" 1 "Komm_nach_KL15_AUS" 2 "Komm_bei_KL15_AUS" ;
VAL_ 2549088581 KN_BMS_NV_ECUKnockOutTimer 63 "ECUKnockOut_deaktiviert" ;
VAL_ 2549088581 KN_BMS_NV_BusKnockOut 0 "Funktion_nicht_ausgeloest" 1 "Veto_aktiv" 2 "Funktion_ausgeloest" 3 "Funktion_deaktiviert" ;
VAL_ 2549088581 KN_BMS_NV_BusKnockOutTimer 255 "BusKnockOut_deaktiviert" ;
VAL_ 2549088581 NM_BMS_NV_Wakeup 0 "Peripherie_Wakeup__Ursache_nicht_bekannt" 1 "Bus_Wakeup" 2 "KL15_HW" ;
VAL_ 2549088581 KN_BMS_NV_ECUKnockOut 0 "Funktion_nicht_ausgeloest" 1 "Veto_war_aktiv" 2 "Funktion_ausgeloest" 3 "Funktion_deaktiviert" ;
VAL_ 2549088581 KN_BMS_NV_DiagPfad 0 "aktiv" 1 "inaktiv" ;
VAL_ 2549088581 BMS_NV_KD_Fehler 0 "kein_KD_Fehler" 1 "KD_Fehler" ;
VAL_ 2549088272 Gateway_KompSchutz 0 "inaktiv" 1 "aktiv" ;
VAL_ 2549088272 Gateway_Abschaltstufe 0 "keine_Einschraenkung" 1 "Funktionseinschraenkung" ;
VAL_ 2549088272 Gateway_Transport_Mode 0 "keine_Einschraenkung" 1 "Funktionseinschraenkung" ;
VAL_ 2549088272 Gateway_Nachlauftyp 0 "Komm_bei_KL15_EIN" 1 "Komm_nach_KL15_AUS" 2 "Komm_bei_KL15_AUS" ;
VAL_ 2549088272 NM_Gateway_Wakeup 0 "Peripherie_Wakeup__Ursache_nicht_bekannt" 1 "Bus_Wakeup" 2 "KL15_HW" 3 "ACAN_Wakeup" 4 "FCAN_Wakeup" 5 "KCAN_Wakeup" 6 "ICAN_Wakeup" 7 "DiagCAN_Wakeup" 8 "ECAN_Wakeup" 9 "Energie_LIN_Wakeup" 10 "Bedien_LIN_Wakeup" 11 "HybridCAN_Wakeup" 12 "Flexray_Wakeup" 13 "MFL_WakeUp" 14 "Ethernet" 15 "DCAN_Wakeup" 16 "K2CAN_Wakeup" 17 "CCAN" 18 "AFSCAN_Wakeup" 19 "LIN1" 20 "LIN2" 21 "LIN3" 22 "LIN4" 23 "LIN5" 24 "LIN6" 25 "FASCAN" 26 "FAS2CAN" 27 "MDKCAN" 32 "FlexRay_Branch1_WakeUp" 33 "FlexRay_Branch2_WakeUp" 34 "FlexRay_Branch3_WakeUp" 35 "FlexRay_Branch4_WakeUp" 36 "FlexRay_Branch5_WakeUp" 37 "FlexRay_Branch6_WakeUp" 38 "FlexRay_Branch7_WakeUp" 39 "FlexRay_Branch8_WakeUp" 40 "FlexRay_Branch9_WakeUp" 41 "FlexRay_Branch10_WakeUp" 42 "FlexRay_Branch11_WakeUp" 43 "FlexRay_Branch12_WakeUp" 44 "FlexRay_Branch13_WakeUp" 45 "FlexRay_Branch14_WakeUp" 46 "FlexRay_Branch15_WakeUp" 47 "FlexRay_Branch16_WakeUp" 128 "Energiemanagement" 129 "Funktionswakeup_OBDC" 130 "Hochvoltenergiemanagement" 131 "CWU_empfangen" 132 "Fuer_Bus_relevanten_FC_empfangen" 133 "OnlineDienst_empfangen" 134 "HV_Aktivieren" 135 "HV_Deaktivieren" 136 "VTS_Suche_DriverCard" 137 "VTS_Hupen_Blinken" 138 "Remote_Vehicle_Status" 139 "Plug_and_Charge" 140 "VTS_Wakeup_Infotainment" 141 "EMHLR" 142 "NFcGW_fordert_OTA_FC_an" 143 "Komponentenschutz" 144 "UserStateServer" 145 "Dimmung" 146 "Kessy" 147 "StandardAussenlicht" 148 "ParkKoordinator" 149 "HVLMDynamicChargingPOI" 150 "HVLMChargingManagementServer" 151 "HVLMExtendedChargingMonitoring" 152 "Zentralverriegelung" 153 "FunctionOnDemand" 154 "IAA" 155 "StandKlimatisierung" 156 "RealTimeMonitor" 157 "Klemmensteuerung" 158 "Fremdladung_erkannt" ;
VAL_ 2549088272 KN_GW_DiagPfad 0 "aktiv" 1 "inaktiv" ;
VAL_ 2549088272 GW_KD_Fehler 0 "kein_KD_Fehler" 1 "KD_Fehler" ;
VAL_ 2549088326 Klima_KompSchutz 0 "inaktiv" 1 "aktiv" ;
VAL_ 2549088326 Klima_Abschaltstufe 0 "keine_Einschraenkung" 1 "Funktionseinschraenkung" ;
VAL_ 2549088326 Klima_Transport_Mode 0 "keine_Einschraenkung" 1 "Funktionseinschraenkung" ;
VAL_ 2549088326 Klima_Nachlauftyp 0 "Komm_bei_KL15_EIN" 1 "Komm_nach_KL15_AUS" 2 "Komm_bei_KL15_AUS" ;
VAL_ 2549088326 KN_Klima_ECUKnockOutTimer 63 "ECUKnockOut_deaktiviert" ;
VAL_ 2549088326 KN_Klima_BusKnockOut 0 "Funktion_nicht_ausgeloest" 1 "Veto_aktiv" 2 "Funktion_ausgeloest" 3 "Funktion_deaktiviert" ;
VAL_ 2549088326 KN_Klima_BusKnockOutTimer 255 "BusKnockOut_deaktiviert" ;
VAL_ 2549088326 NM_Klima_Wakeup 0 "Peripherie_Wakeup__Ursache_nicht_bekannt" 1 "Bus_Wakeup" 2 "KL15_HW" 3 "KL30_Reset" 4 "STH_Taste" 5 "Restwaerme_Menuauswahl" 128 "STH_Ein__Zielzeitlogik" 129 "Standfunktion_Funk_EIN" 130 "Umentscheidung_STL_nach_STH" 131 "Ablauf_der_max_Betriebsdauer" 132 "Geblaese_aus_ein" ;
VAL_ 2549088326 KN_Klima_ECUKnockOut 0 "Funktion_nicht_ausgeloest" 1 "Veto_war_aktiv" 2 "Funktion_ausgeloest" 3 "Funktion_deaktiviert" ;
VAL_ 2549088326 KN_KL_DiagPfad 0 "aktiv" 1 "inaktiv" ;
VAL_ 2549088326 NM_Klima_Lokalaktiv 0 "war_nicht_lokal_aktiv" 1 "war_lokal_aktiv" ;
VAL_ 2549088326 NM_Klima_Subsystemaktiv 0 "Subsystem_war_nicht_lokalaktiv" 1 "war_lokalaktiv" ;
VAL_ 2549088326 KL_KD_Fehler 0 "kein_KD_Fehler" 1 "KD_Fehler" ;
VAL_ 779 KBI_ABS_Lampe 0 "ABS Lampe aus" 1 "ABS Lampe ein" ;
VAL_ 779 KBI_ESP_Lampe 0 "ESP Lampe aus" 1 "ESP Lampe ein" ;
VAL_ 779 KBI_BKL_Lampe 0 "BKL aus" 1 "BKL ein" ;
VAL_ 779 KBI_Airbag_Lampe 0 "Airbag Lampe aus" 1 "Airbag Lampe ein" ;
VAL_ 779 KBI_SILA_gueltig 0 "ungueltig" 1 "gueltig" ;
VAL_ 779 KBI_Vorglueh_System_Lampe 0 "Lampe aus" 1 "Lampe ein" ;
VAL_ 779 KBI_NV_in_Anzeige 0 "NV_nicht_in_Anzeige" 1 "NV_in_Anzeige" ;
VAL_ 779 KBI_Anzeigestatus_ACC 0 "keine_ACC_Anzeige" 1 "ACC_Anzeige_aktiv" ;
VAL_ 779 KBI_Anzeigestatus_GRA 0 "nicht_vorhanden" 1 "Anzeigemoeglichkeit_vorhanden" 2 "reserviert" 3 "Fehler" ;
VAL_ 779 KBI_Oeldruck_Schalter 0 "offen____p_kleiner_pnenn" 1 "geschlossen____p_groessergleich_pnenn" ;
VAL_ 779 KBI_Tankwarnung 0 "Lampe aus" 1 "Lampe ein" ;
VAL_ 779 KBI_MFA_v_Einheit_01 0 "kmh" 1 "mph" ;
VAL_ 779 KBI_im_Stellgliedtest 0 "kein Stellgliedtest" 1 "Kombi im Stellgliedtest" ;
VAL_ 779 KBI_Anzeigefehler_LDW 0 "nicht vorhanden bzw. unterstützt" 1 "Anzeige iO" 2 "Anzeigefehler" 3 "nicht definiert" ;
VAL_ 779 KBI_Tankwarnung_ungueltig 0 "KBI_Tankwarnung_gueltig" 1 "KBI_Tankwarnung_ungueltig" ;
VAL_ 779 KBI_Oeldruckwarnung 0 "inaktiv" 1 "aktiv" ;
VAL_ 779 KBI_Handbremse 0 "nicht_angezogen" 1 "angezogen" ;
VAL_ 779 KBI_PLA_in_Anzeige 0 "PLA_nicht_in_Anzeige" 1 "PLA_in_Anzeige" ;
VAL_ 779 KBI_Anzeigefehler_NV 0 "kein_Anzeigefehler" 1 "Anzeigefehler" ;
VAL_ 779 KBI_Anzeigestatus_LIM 0 "nicht_vorhanden" 1 "Anzeigemoeglichkeit_vorhanden" 2 "reserviert" 3 "Fehler" ;
VAL_ 779 KBI_ARA_in_Anzeige 0 "ARA nicht in Anzeige" 1 "ARA in Anzeige" ;
VAL_ 779 KBI_Taster_Lift 0 "nicht_betaetigt" 1 "betaetigt" ;
VAL_ 779 KBI_Taster_Fahrwerk 0 "nicht_betaetigt" 1 "betaetigt" ;
VAL_ 779 KBI_Audioabsenkung_MIB 0 "keine_Audio_Absenkung" 1 "Audio_Absenkung_Stufe_1" 2 "Audio_Absenkung_Stufe_2" 3 "Audio_Absenkung_Stufe_3" ;
VAL_ 779 KBI_Bestaetigung_ESP_Off 0 "ESP_off_nicht_quittiert" 1 "ESP_off_quittiert" 2 "Abbruch" ;
VAL_ 779 KBI_Anzeigestatus_RHP 0 "nicht_unterstuetzt_oder_Startup" 1 "Anzeige iO" 2 "Anzeigefehler" 3 "nicht definiert" ;
VAL_ 779 KBI_Konsistenz_ACC 0 "ACC Botschaft konsistent" 1 "ACC Botschaft inkonsistent" ;
VAL_ 779 KBI_Fehler_Anzeige_ACC 0 " iO" 1 "Anzeigefehler ACC" ;
VAL_ 779 KBI_Anzeigefehler_SWA 0 "nicht vorhanden bzw. unterstützt" 1 "Anzeige iO" 2 "Anzeigefehler" 3 "nicht definiert" ;
VAL_ 779 KBI_Systemstatus 0 "KBI_IO" 1 "KBI_System_Failure" ;
VAL_ 1719 KBI_Kilometerstand 1048574 "Init" 1048575 "Fehler" ;
VAL_ 1719 KBI_Standzeit_02 131069 "nicht_verfuegbar" 131070 "Init" 131071 "Fehler" ;
VAL_ 1719 KBI_Reserve_Warnung_Sek 0 "Keine_Warnung" 1 "Sekundaere_Reservewarnung" ;
VAL_ 1719 KBI_RDK_Kalibrier_Anf 0 "keine_Kalibrieranforderung" 1 "Kalibrieranforderung" ;
VAL_ 1719 KBI_Inhalt_Tank 126 "Init" 127 "Fehler" ;
VAL_ 1719 KBI_FStatus_Tank 0 "Tankfüllstand i.O." 1 "Tankfüllstand n.i.O" ;
VAL_ 1719 KBI_aktive_Laengsfunktion_02 0 "Init" 1 "Speedlimiter" 2 "GRA_oder_ACC" 3 "PACCh" 4 "HDC" 5 "p_GRA" 6 "p_Lim" 7 "ACC_im_GRA_Modus" 8 "Travel_Assist" 9 "RHP" ;
VAL_ 1719 KBI_FoD_PopUP_Quittiert 0 "nicht_quittiert" 1 "Meldung_quittiert" ;
VAL_ 1719 KBI_GRA_im_ACC 0 "GRA_im_ACC_nicht_ausgewaehlt" 1 "GRA_im_ACC_ausgewaehlt" ;
VAL_ 1719 KBI_Oelwechsel_durchgefuehrt 0 "Oelwechsel_nicht_durchgefuehrt" 1 "Oelwechsel_durchgefuehrt" ;
VAL_ 1719 KBI_QBit_Aussen_Temp_gef 0 "gueltiger_Wert" 1 "Ersatz_Init_oder_Fehlerwert" ;
VAL_ 1719 KBI_Aussen_Temp_gef 253 "nicht verbaut" 254 "Init" 255 "Fehler" ;
VAL_ 2527679639 KBI_Weg_Zaehler_F 0 "kein Fehler" 1 "Fehler" ;
VAL_ 2527679639 KBI_Anzeige_ID_quittiert 0 "Init" ;
VAL_ 2527679639 KBI_Min_Tankinhalt 126 "Init" 127 "Fehler" ;
VAL_ 2527679639 KBI_Jokerkey 0 "nicht_betaetigt" 1 "betaetigt" ;
VAL_ 2527679639 KBI_RS_Druck_uebernehmen 0 " Druck für Rundstreckenmodue nicht uebernehmen" 1 " Druck für Rundstreckenmodus uebernehmen" ;
VAL_ 2527679639 KBI_RS_Druckauswahl_Aktiv 0 "inaktiv" 1 "aktiv" ;
VAL_ 2527679639 KBI_RS_Mode_fortsetzen 0 "Rundstreckenmodus_nicht_fortsetzen" 1 "Rundstreckenmodus_fortsetzen" ;
VAL_ 2527679639 KBI_Rundstreckenmodus 0 "nicht_angefordert" 1 "angefordert" ;
VAL_ 2527679639 AuthTime_Trigger_Distribution 0 "inaktiv" 1 "aktiv" ;
VAL_ 2527679639 KBI_FoD_VirtualCockpitPlus_State 0 "Init" 1 "locked" 2 "unlocked" ;
VAL_ 2589283631 KBI_Tankinhalt_roh 2046 "Init" 2047 "Fehler" ;
VAL_ 2589283631 KBI_BC_Reset_E1 0 "SG_Reset" 1 "Reset_Zaehler" 2 "Reset_Zaehler" 3 "Reset_Zaehler" 4 "Reset_Zaehler" 5 "Reset_Zaehler" 6 "Reset_Zaehler" 7 "Init" ;
VAL_ 2589283631 KBI_BC_Reset_E2 0 "SG_Reset" 1 "Reset_Zaehler" 2 "Reset_Zaehler" 3 "Reset_Zaehler" 4 "Reset_Zaehler" 5 "Reset_Zaehler" 6 "Reset_Zaehler" 7 "Init" ;
VAL_ 2589283631 KBI_BC_Reset_E3 0 "SG_Reset" 1 "Reset_Zaehler" 2 "Reset_Zaehler" 3 "Reset_Zaehler" 4 "Reset_Zaehler" 5 "Reset_Zaehler" 6 "Reset_Zaehler" 7 "Init" ;
VAL_ 822 LR_HZG_Temp_Sensor 253 "KS_Plus__Unterbrechung" 254 "Init" 255 "Tempsensor_fehlerhaft__KS_GND" ;
VAL_ 822 LR_HZG_Taster_on_off 0 "nicht_betaetigt" 1 "betaetigt" ;
VAL_ 822 LR_HZG_Konfiguration 0 "Init" 1 "Parametersatz_1" 2 "Parametersatz_2" 3 "Parametersatz_3" 4 "Parametersatz_4" 5 "Parametersatz_5" 6 "Parametersatz_6" 7 "Parametersatz_7" ;
VAL_ 2527679633 LSH_Geblaese_aktiv 0 "Geblaese_inaktiv" 1 "Geblaese_aktiv" ;
VAL_ 2527679633 LSH_LED 0 "keine_Rueckmeldung" 1 "Rueckmeldung_in_Betrieb" ;
VAL_ 2527679633 LSH_Servicemode 0 "inaktiv" 1 "aktiv" ;
VAL_ 2527679633 LSH_Funk_aus 0 "kein_Funkbefehl_erhalten" 1 "Funkbefehl_erhalten" ;
VAL_ 2527679633 LSH_Funk_ein 0 "kein_Funkbefehl_erhalten" 1 "Funkbefehl_erhalten" ;
VAL_ 2527679633 LSH_Klappe_Status 0 "Init" 1 "Front" 2 "Heck" 3 "Front_u_Heck" 4 "misch_Front_u_Heck" ;
VAL_ 2527679633 LSH_Start_folgt 0 "kein_Start_folgt" 1 "Start_folgt" ;
VAL_ 2527679633 LSH_Heiztemp 254 "Init" 255 "Fehler" ;
VAL_ 2527679633 LSH_Empf_Heizstufe 0 "Init" 1 "Stufe_1" 2 "Stufe_2" 3 "Stufe_3" 4 "Stufe_4" 5 "Stufe_5" 6 "Stufe_6" 7 "Stufe_7" 8 "Stufe_8" 9 "Stufe_9" 10 "Stufe_10" 15 "Fehler" ;
VAL_ 2527679633 LSH_Texte 0 "keine_Anzeige" 1 "Batteriemanagementeinschraenkung" 2 "Kraftstoffmangel" 3 "interner_Systemfehler" 4 "Heizzeitueberschreitung" ;
VAL_ 2527679633 LSH_Waermeeintrag 510 "Init" 511 "Fehler" ;
VAL_ 2527679633 LSH_Ansaug_Fuell_1 254 "Init" 255 "Fehler" ;
VAL_ 2527679633 LSH_Ansaug_Fuell_2 254 "Init" 255 "Fehler" ;
VAL_ 2527679634 LSH_Zuheizen 0 "Aus" 1 "Ein" ;
VAL_ 2527679634 LSH_KVS_Ueberlauf 0 "kein_Ueberlauf" 1 "Kraftstoff_Ueberlauf_erkannt" ;
VAL_ 2527679634 LSH_KL_DBetr_Anf 0 "nicht_angefordert" 1 "angefordert" ;
VAL_ 2527679634 LSH_Fehlerstatus 0 "kein_Fehler" 1 "Unterspannung" 2 "Tankfuellstand_zu_gering" 3 "Fehler_Betrieb_verhindert" 4 "Heizgeraet_verriegelt" 5 "Fehler_Betrieb_nicht_verhindert" 6 "Emissionsueberschreitung" ;
VAL_ 1164 MFG_Infotainment_Autark 0 "Autarkie_no" 1 "Autarkie_yes" ;
VAL_ 1164 MFG_Klappe_Status 0 "Init" 1 "Front" 2 "Heck" 3 "Front_u_Heck" 4 "misch_Front_u_Heck" ;
VAL_ 1164 MFG_LSH_DBetr_Ein 0 "Dauerbetrieb_nicht_gefordert" 1 "Dauerbetrieb_gefordert" ;
VAL_ 1164 MFG_LSH_Betriebsdauer 127 "Dauerbetrieb" ;
VAL_ 1164 MFG_LSH_DBetr_Bestaet 0 "kein_Dauerbetrieb" 1 "Dauerbetrieb_bestaetigt" ;
VAL_ 1164 MFG_LSH_Ansteuerung 0 "Aus" 1 "Ein" 2 "Kombi_Betrieb" 3 "Heizleistung_reduziert" ;
VAL_ 1164 MF_Radiomute 0 "Kein_Mute" 1 "Mute" ;
VAL_ 1164 MF_Relais_2_Batterie 0 "nicht_betaetigt" 1 "betaetigt" ;
VAL_ 1164 MF_Batteriediagnose 0 "keine_Anzeige" 1 "Anzeige_Batterieservice" 2 "Anzeige_aberkannte_Batterie" 3 "Anzeige_schwache_Batterie" 4 "Anzeige_Batterie_OK" 5 "Anzeige_Batterie_Laden" 6 "Anzeige_Batterie_Pruefen" 7 "Fehler" ;
VAL_ 1164 MFG_AppConnect_Anf 0 "AppConnect_keine_Anforderung" 1 "AppConnect_Anforderung" 2 "AppConnect_Darstellungsrueckgabe" ;
VAL_ 1164 MF_Lampenausfall 0 "iO" 1 "defekt" ;
VAL_ 1164 MF_Blinker_L_Sta 0 "inaktiv" 1 "aktiv" ;
VAL_ 1164 MF_Blinker_R_Sta 0 "inaktiv" 1 "aktiv" ;
VAL_ 1164 MF_interm_Nebelscheinwerfer 0 "inaktiv" 1 "aktiv" ;
VAL_ 1164 MF_Generatordiagnose 0 "keine_Warnung" 1 "Warnung_Stufe_1" 2 "Warnung_Stufe_2" 3 "Nicht_verbaut" ;
VAL_ 1164 MF_Heck_entriegeln 0 "nicht_entriegeln" 1 "entriegeln" ;
VAL_ 1164 MF_Heck_verriegeln 0 "nicht_verriegeln" 1 "verriegeln" ;
VAL_ 1164 MF_2BatSOCzugering 0 "inaktiv" 1 "aktiv" ;
VAL_ 1164 MF_Fahrerhinweis 0 "keine_Anzeige" 1 "Warnung_Verrollsicherheit" 2 "Warnung_Fahrzeug_im_Freien" 3 "Warnung_Verlassen_Verriegeln" 4 "reserved" 5 "reserved" 6 "reserved" 7 "reserved" ;
VAL_ 1164 MF_ZV_Unlock 0 "nicht_entriegeln" 1 "entriegeln" ;
VAL_ 1164 MF_Tuerverriegelung_hinten 0 "inaktiv" 1 "aktiv" ;
VAL_ 1164 MF_2BattAb 0 "inaktiv" 1 "aktiv" ;
VAL_ 1164 MF_2BattHlkAnf 0 "inaktiv" 1 "aktiv" ;
VAL_ 1164 MF_2BattLadWarn 0 "inaktiv" 1 "aktiv" ;
VAL_ 1164 MF_2BattLlaAnf 0 "inaktiv" 1 "aktiv" ;
VAL_ 1164 MF_2BattSpannungsAnf 0 "keine_Anforderung" 1 "Anforderung_Stufe1" 2 "Anforderung_Stufe2" 3 "Anforderung_Stufe3" ;
VAL_ 1164 MF_NotStartAktiv 0 "inaktiv" 1 "aktiv" ;
VAL_ 1164 MF_ExterneLadungWarn 0 "inaktiv" 1 "aktiv" ;
VAL_ 1164 MF_LSH_Zielzeit 14 "Init" 15 "Fehler" ;
VAL_ 1164 MF_LSH_Abschaltstufe 0 "Init" 1 "Stufe1" 2 "Stufe2" 3 "Stufe3" 4 "Transportmodus" 7 "Ruhestrommessmodus" ;
VAL_ 1164 MF_LSH_Einschaltverbot 0 "Init_volleVerfuegbarkeit" 1 "Standheizung_bzw_lueftung_nicht_aktivierbar" ;
VAL_ 1471 MFL_Tastencode_1 0 "Key_Released__No_Key" 1 "Context_Menu" 2 "Menu_Up__Next_Screen" 3 "Menu_Down__Previous_Screen" 4 "Up" 5 "Down" 6 "Up__Down_ThumbWheel" 7 "OK__ThumbWheel_Button" 8 "Cancel__Escape" 9 "Main_Menu" 10 "Side_Menu_left" 11 "Side_Menu_right" 12 "FAS_Menu" 13 "Left__Right_ThumbWheel" 14 "FAS_Menu_ThumbWheel" 16 "Volume_Up" 17 "Volume_Down" 18 "Volume_Up__Down_ThumbWheel" 19 "Volume_ThumbWheel_Button" 20 "Audio_Source" 21 "Arrow_A_Up__Right" 22 "Arrow_A_Down__Left" 23 "Arrow_B_Up__Right" 24 "Arrow_B_Down__Left" 25 "PTT__PushToTalk" 26 "PTT_Cancel" 27 "Route_Info" 28 "Hook" 29 "Hang_Up" 30 "Off_Hook" 31 "Light_On__Off" 32 "Mute" 33 "Joker1" 34 "Joker2" 35 "View" 36 "Arrow_A_Up__Down_ThumbWheel" 37 "Lenkradheizung" 38 "Rekuperation" 39 "Tube_Toggle" 40 "DRS_Drag_Reduction_System" 41 "Stopwatch_Start_Stop" 42 "Stopwatch_Nextlap" 100 "MAP" 101 "MAP_Boost" 102 "Turn_signal_left" 103 "Turn_signal_right" 104 "Turn_signal_off" 105 "Flashlight" 106 "Highbeam" 107 "Washer_button" 108 "Wiper_button_left" 109 "Wiper_button_right" 110 "Wiper_button_cancel" 111 "Exhaust_Sound" 112 "Drive_Select_button" 113 "Sport_button" 114 "ESP_Drift_Selection_ThumbWheel" 115 "PTT_special_vehicle" 116 "TravelAssist" 117 "Launch_Control" 118 "Drift_Mode_Button_Increase" 119 "Drift_Mode_Button_Decrease" 120 "Drift_Mode_Button_Select" 121 "Drive_Mode_Button_Increase" 122 "Drive_Mode_Button_Decrease" 123 "Drive_Mode_Button_Select" 124 "E_Boost_Button_Increase" 125 "E_Boost_Button_Decrease" 126 "E_Boost_Button_Select" 127 "PerformanceHybridButton_Increase" 128 "PerformanceHybridButton_Decrease" 129 "EV_Mode_Button" 130 "HUD_Button" 131 "PASM_Wheel" 132 "PASM_Button" 133 "PTV_Wheel" 134 "PTV_Button" 135 "TC_ESC_Wheel" 136 "TC_ESC_Button" 240 "Startup_Reset" 241 "Initialization" ;
VAL_ 1471 MFL_Tastencode_2 0 "Key_Released__No_Key" 1 "Context_Menu" 2 "Menu_Up__Next_Screen" 3 "Menu_Down__Previous_Screen" 4 "Up" 5 "Down" 6 "Up__Down_ThumbWheel" 7 "OK__ThumbWheel_Button" 8 "Cancel__Escape" 9 "Main_Menu" 10 "Side_Menu_left" 11 "Side_Menu_right" 12 "FAS_Menu" 13 "Left__Right_ThumbWheel" 14 "FAS_Menu_ThumbWheel" 16 "Volume_Up" 17 "Volume_Down" 18 "Volume_Up__Down_ThumbWheel" 19 "Volume_ThumbWheel_Button" 20 "Audio_Source" 21 "Arrow_A_Up__Right" 22 "Arrow_A_Down__Left" 23 "Arrow_B_Up__Right" 24 "Arrow_B_Down__Left" 25 "PTT__PushToTalk" 26 "PTT_Cancel" 27 "Route_Info" 28 "Hook" 29 "Hang_Up" 30 "Off_Hook" 31 "Light_On__Off" 32 "Mute" 33 "Joker1" 34 "Joker2" 35 "View" 36 "Arrow_A_Up_Right_Down_Left_ThumbWheel" 37 "Lenkradheizung" 38 "Rekuperation" 39 "Tube_Toggle" 40 "DRS_Drag_Reduction_System" 41 "Stopwatch_Start_Stop" 42 "Stopwatch_Nextlap" 100 "MAP" 101 "MAP_Boost" 102 "Turn_signal_left" 103 "Turn_signal_right" 104 "Turn_signal_off" 105 "Flashlight" 106 "Highbeam" 107 "Washer_button" 108 "Wiper_button_left" 109 "Wiper_button_right" 110 "Wiper_button_cancel" 111 "Exhaust_Sound" 112 "Drive_Select_button" 113 "Sport_button" 114 "ESP_Drift_Selection_ThumbWheel" 115 "PTT_special_vehicle" 116 "TravelAssist" 117 "Launch_Control" 118 "Drift_Mode_Button_Increase" 119 "Drift_Mode_Button_Decrease" 120 "Drift_Mode_Button_Select" 121 "Drive_Mode_Button_Increase" 122 "Drive_Mode_Button_Decrease" 123 "Drive_Mode_Button_Select" 124 "E_Boost_Button_Increase" 125 "E_Boost_Button_Decrease" 126 "E_Boost_Button_Select" 127 "PerformanceHybridButton_Increase" 128 "PerformanceHybridButton_Decrease" 129 "EV_Mode_Button" 130 "HUD_Button" 131 "PASM_Wheel" 132 "PASM_Button" 133 "PTV_Wheel" 134 "PTV_Button" 135 "TC_ESC_Wheel" 136 "TC_ESC_Button" 240 "Startup_Reset" 241 "Initialization" ;
VAL_ 1471 MFL_Eventcode_1 0 "W_no_event____T_no_event" 1 "W_1_Tick_up__T_pressed_normal" 2 "W_2_Ticks_up__T_touched" 3 "W_3_Ticks_up__T_double_click_nor" 4 "W_4_Ticks_up__T_long_press_nor_1" 5 "W_5_Ticks_up__T_long_press_nor_2" 6 "W_6_Ticks_up__T_long_press_nor_3" 7 "W_7_Ticks_up" 9 "W_7_Ticks_dn__T_pressed_strong" 10 "W_6_Ticks_dn" 11 "W_5_Ticks_dn__T_double_click_str" 12 "W_4_Ticks_dn__T_long_press_str_1" 13 "W_3_Ticks_dn__T_long_press_str_2" 14 "W_2_Ticks_dn__T_long_press_str_3" 15 "W_1_Tick_dn" ;
VAL_ 1471 MFL_Eventcode_2 0 "W_no_event____T_no_event" 1 "W_1_Tick_up__T_pressed_normal" 2 "W_2_Ticks_up__T_touched" 3 "W_3_Ticks_up__T_double_click_nor" 4 "W_4_Ticks_up__T_long_press_nor_1" 5 "W_5_Ticks_up__T_long_press_nor_2" 6 "W_6_Ticks_up__T_long_press_nor_3" 7 "W_7_Ticks_up" 9 "W_7_Ticks_dn__T_pressed_strong" 10 "W_6_Ticks_dn" 11 "W_5_Ticks_dn__T_double_click_str" 12 "W_4_Ticks_dn__T_long_press_str_1" 13 "W_3_Ticks_dn__T_long_press_str_2" 14 "W_2_Ticks_dn__T_long_press_str_3" 15 "W_1_Tick_dn" ;
VAL_ 1471 MFL_Marke 0 "VW" 1 "Audi" 2 "Seat" 3 "Skoda" 4 "VW_Nutzf" 5 "Bugatti" 6 "Lamborghini" 7 "Bentley" 8 "Rolls Royce" 9 "Quattro" 10 "kein_Hersteller_1" 11 "kein_Hersteller_2" 12 "kein_Hersteller_3" 13 "kein_Hersteller_4" 14 "Ford" 15 "Porsche" ;
VAL_ 1600 MO_QBit_Ansaugluft_Temp 0 "gueltiger_Wert" 1 "Ersatz_Init_oder_Fehlerwert" ;
VAL_ 1600 MO_QBit_Oel_Temp 0 "gueltiger_Wert" 1 "Ersatz_Init_oder_Fehlerwert" ;
VAL_ 1600 MO_QBit_Kuehlmittel_Temp 0 "gueltiger_Wert" 1 "Ersatz_Init_oder_Fehlerwert" ;
VAL_ 1600 MO_KL15_Abschaltempfehlung 0 "Keine Empfehlung" 1 "Abschaltempfehlung" ;
VAL_ 1600 MO_HYB_Fehler_HV_Netz 0 "i_O" 1 "kein_generatorischer_Betrieb_moeglich" ;
VAL_ 1600 MO_aktives_Getriebeheizen 0 "kein_Ventil_ansteuern" 1 "Ventil_muss_angesteuert_werden" ;
VAL_ 1600 MO_Absperrventil_oeffnen 0 "nicht_verfuegbar" 1 "Ansteuerung_Ventil_zulaessig" 2 "Ventil_oeffnen_oder_geoeffnet" 3 "Ventil_schliessen_oder_geschlossen" ;
VAL_ 1600 MO_Ansaugluft_Temp 254 "Init" 255 "Fehler" ;
VAL_ 1600 MO_Oel_Temp 253 "nicht_verbaut" 254 "Init" 255 "Fehler" ;
VAL_ 1600 MO_Kuehlmittel_Temp 254 "Init" 255 "Fehler" ;
VAL_ 1600 MO_Hoeheninfo 255 "Fehler" ;
VAL_ 1600 MO_Kennfeldk 0 "keine Kennfeldkühlung vorhanden" 1 "Kennfeldkühlung vorhanden" ;
VAL_ 1600 MO_Versionsinfo_02 0 "zum_Projektbeginn_aufgeraeumter_CAN" 1 "Motor_03_mit_10ms" 16 "MQB_mit_neuer_Momentenschnittstelle" ;
VAL_ 1600 MO_QBit_Hoeheninfo 0 "gueltiger_Wert" 1 "Ersatz_Init_oder_Fehlerwert" ;
VAL_ 1600 MO_Getriebe_kuehlen 0 "nicht_kuehlen" 1 "kuehlen" ;
VAL_ 1600 MO_Heizungspumpenansteuerung 13 "Fehler" 14 "Init" 15 "nicht_verbaut" ;
VAL_ 1600 MO_SpannungsAnf 0 "keine_Anforderung" 1 "Anforderung" ;
